VERSION "dbc-export 1 2025.20.8"

NS_ :

BS_:

BU_: ADSP APB APP APS APSB BB BMS CC CMP CMPD CP DAS DI DIF DIR DPB EPAS3P EPAS3S EPASTP EPASTS EPBL EPBR ESP EVSE FC GTW HCML HCMR HVP IBST ICR IDB LS OCS1P ODIN PARK PCS PLG PM PMF PMR PNCD PTC RADC RCM RCM2 RCM3 RCU SCCM SCM SCS SDCR TAS TCU TPMS TRCM UDS UI UIS UMC USM VC VCFRONT VCLEFT VCRIGHT VCSEC VEH

BO_ 1343 BMS_alertLog: 8 BMS
 SG_ BMS_alertID M : 0|8@1+ (1,0) [0|255] "" Vector__XXX
 SG_ BMS_alertSet : 15|1@1+ (1,0) [0|1] "" Vector__XXX
 SG_ BMS_a001_gatewayPackEnergy m1 : 16|2@1+ (1,0) [0|3] "" Vector__XXX
 SG_ BMS_a001_expectedPackEnergy m1 : 18|2@1+ (1,0) [0|3] "" Vector__XXX
 SG_ BMS_a002_gatewayPackPerformanceD m2 : 16|3@1+ (1,0) [0|7] "" Vector__XXX
 SG_ BMS_a002_expectedPackPerformance m2 : 19|3@1+ (1,0) [0|7] "" Vector__XXX
 SG_ BMS_a002_bmsPackMass m2 : 24|8@1+ (1,300) [300|555] "kg" Vector__XXX
 SG_ BMS_a003_calBlockData_0 m3 : 16|32@1+ (1,0) [0|4294967295] "" Vector__XXX
 SG_ BMS_a007_minPackTemperature m7 : 16|8@1+ (0.5,-40) [-40|87.5] "DegC" Vector__XXX
 SG_ BMS_a007_packCurrent m7 : 24|14@1+ (0.1,0) [0|1638.3] "A" Vector__XXX
 SG_ BMS_a007_idealCurrentTarget m7 : 40|14@1+ (0.1,0) [0|1638.3] "A" Vector__XXX
 SG_ BMS_a017_packCurrent m17 : 16|8@1+ (8,-1500) [-1500|540] "A" Vector__XXX
 SG_ BMS_a017_ovBrickVID m17 : 24|7@1+ (1,1) [1|128] "" Vector__XXX
 SG_ BMS_a017_ovBrickV m17 : 32|16@1+ (7.62939453125e-05,0) [0|4.99992370605] "V" Vector__XXX
 SG_ BMS_a018_packCurrent m18 : 16|8@1+ (8,-1496) [-1496|544] "A" Vector__XXX
 SG_ BMS_a018_uvBrickVID m18 : 24|7@1+ (1,1) [1|128] "" Vector__XXX
 SG_ BMS_a018_uvBrickV m18 : 32|16@1+ (7.62939453125e-05,0) [0|4.99992370605] "V" Vector__XXX
 SG_ BMS_a019_coolantInletT m19 : 16|8@1+ (0.4,-20) [-20|82] "C" Vector__XXX
 SG_ BMS_a019_activeCoolingTarget m19 : 24|8@1+ (0.4,-20) [-20|82] "C" Vector__XXX
 SG_ BMS_a019_maxBrickT m19 : 32|8@1+ (0.4,-20) [-20|82] "C" Vector__XXX
 SG_ BMS_a019_maxBrickTID m19 : 40|5@1+ (1,1) [1|32] "" Vector__XXX
 SG_ BMS_a021_chargeViolation m21 : 16|1@1+ (1,0) [0|1] "" Vector__XXX
 SG_ BMS_a021_currentLimit m21 : 24|8@1+ (8,-1496) [-1496|544] "A" Vector__XXX
 SG_ BMS_a021_packCurrent m21 : 32|8@1+ (8,-1496) [-1496|544] "A" Vector__XXX
 SG_ BMS_a022_chargeAccumulatorViolat m22 : 16|1@1+ (1,0) [0|1] "" Vector__XXX
 SG_ BMS_a022_chargeAccumulatorValue m22 : 17|23@1+ (10,0) [0|83886070] "A^2s" Vector__XXX
 SG_ BMS_a022_chargeAccumulatorLimit m22 : 40|23@1+ (10,0) [0|83886070] "A^2s" Vector__XXX
 SG_ BMS_a023_ovStackDeviceID m23 : 16|5@1+ (1,1) [1|32] "-" Vector__XXX
 SG_ BMS_a023_ovStackV m23 : 24|16@1+ (0.00128,0) [0|83.8848] "V" Vector__XXX
 SG_ BMS_a024_brickID m24 : 16|8@1+ (1,1) [1|256] "-" Vector__XXX
 SG_ BMS_a024_deltaV m24 : 24|16@1- (0.0001,0) [-3.2768|3.2767] "V" Vector__XXX
 SG_ BMS_a024_avgDvPrev m24 : 40|16@1- (0.0001,0) [-3.2768|3.2767] "V" Vector__XXX
 SG_ BMS_a024_packCurrent m24 : 56|8@1+ (8,-1500) [-1500|540] "A" Vector__XXX
 SG_ BMS_a027_swIsolationCount m27 : 16|8@1+ (1,0) [0|255] "" Vector__XXX
 SG_ BMS_a027_swIsoDegradationCount m27 : 24|8@1+ (1,0) [0|255] "" Vector__XXX
 SG_ BMS_a030_worstBrickID m30 : 16|8@1+ (1,1) [1|256] "" Vector__XXX
 SG_ BMS_a030_maxBrickImpedance m30 : 24|10@1+ (0.1,0) [0|102.3] "mOhm" Vector__XXX
 SG_ BMS_a030_maxNormalizedImpedanceD m30 : 34|7@1+ (0.04,0) [0|5.08] "Ratio" Vector__XXX
 SG_ BMS_a030_faultThreshold m30 : 41|7@1+ (0.04,0) [0|5.08] "Ratio" Vector__XXX
 SG_ BMS_a030_numBricks m30 : 48|8@1+ (1,0) [0|255] "" Vector__XXX
 SG_ BMS_a030_worstBrickSoc m30 : 56|8@1+ (0.5,0) [0|127.5] "PCT" Vector__XXX
 SG_ BMS_a035_isoR m35 : 16|9@1+ (10,0) [0|5110] "kOhm" Vector__XXX
 SG_ BMS_a035_mode m35 : 25|3@1+ (1,0) [0|7] "" Vector__XXX
 SG_ BMS_a035_activeSideVNoR m35 : 28|9@1+ (1,0) [0|511] "V" Vector__XXX
 SG_ BMS_a035_activeSideVWithR m35 : 37|9@1+ (1,0) [0|511] "V" Vector__XXX
 SG_ BMS_a035_passiveSideVNoR m35 : 46|9@1+ (1,0) [0|511] "V" Vector__XXX
 SG_ BMS_a035_passiveSideVWithR m35 : 55|9@1+ (1,0) [0|511] "V" Vector__XXX
 SG_ BMS_a037_floodPort1State m37 : 16|3@1+ (1,0) [1|7] "" Vector__XXX
 SG_ BMS_a037_floodPort1Voltage m37 : 19|12@1+ (0.001,0) [0|4.095] "V" Vector__XXX
 SG_ BMS_a037_floodPort2State m37 : 32|3@1+ (1,0) [1|7] "" Vector__XXX
 SG_ BMS_a037_floodPort2Voltage m37 : 35|12@1+ (0.001,0) [0|4.095] "V" Vector__XXX
 SG_ BMS_a039_dcLinkVoltage m39 : 16|10@1+ (1,0) [0|1023] "V" Vector__XXX
 SG_ BMS_a039_packVoltage m39 : 26|10@1+ (1,0) [0|1023] "V" Vector__XXX
 SG_ BMS_a039_packContactorState m39 : 36|4@1+ (1,0) [1|15] "" Vector__XXX
 SG_ BMS_a039_packCurrent m39 : 40|8@1+ (8,-1496) [-1496|544] "A" Vector__XXX
 SG_ BMS_a039_maxBrickV m39 : 48|8@1+ (0.01,2) [2|4.55] "V" Vector__XXX
 SG_ BMS_a039_state m39 : 56|4@1+ (1,0) [0|15] "" Vector__XXX
 SG_ BMS_a041_resetType m41 : 16|4@1+ (1,0) [0|15] "" Vector__XXX
 SG_ BMS_a050_MIA_numBadReadings m50 : 16|8@1+ (1,0) [0|255] "" Vector__XXX
 SG_ BMS_a050_MIA_numSnaReadings m50 : 24|8@1+ (1,0) [0|255] "" Vector__XXX
 SG_ BMS_a051_hvp1V5Ref m51 : 16|12@1+ (0.001,0) [0|4.095] "V" Vector__XXX
 SG_ BMS_a051_hvp3V0Ref m51 : 28|12@1+ (0.001,0) [0|4.095] "V" Vector__XXX
 SG_ BMS_a051_bms3V0Ref m51 : 40|12@1+ (0.001,0) [0|4.095] "V" Vector__XXX
 SG_ BMS_a056_standbySupplyOutV m56 : 16|12@1+ (0.01,0) [0|40.95] "V" Vector__XXX
 SG_ BMS_a056_packVoltage m56 : 28|16@1+ (0.01,0) [0|655.35] "V" Vector__XXX
 SG_ BMS_a056_minBrickVoltage m56 : 44|12@1+ (0.002,0) [0|8.19] "V" Vector__XXX
 SG_ BMS_a056_standbyEnabled m56 : 56|1@1+ (1,0) [0|1] "" Vector__XXX
 SG_ BMS_a056_standbySwGood m56 : 57|1@1+ (1,0) [0|1] "" Vector__XXX
 SG_ BMS_a056_ssOutTooHigh m56 : 58|1@1+ (1,0) [0|1] "" Vector__XXX
 SG_ BMS_a056_ssOutTooLow m56 : 59|1@1+ (1,0) [0|1] "" Vector__XXX
 SG_ BMS_a056_ssStuckOn m56 : 60|1@1+ (1,0) [0|1] "" Vector__XXX
 SG_ BMS_a056_ssStuckOff m56 : 61|1@1+ (1,0) [0|1] "" Vector__XXX
 SG_ BMS_a058_bandoThmModelState m58 : 16|4@1+ (1,0) [1|15] "" Vector__XXX
 SG_ BMS_a058_thermistorTempsInvalid m58 : 20|1@1+ (1,0) [0|1] "" Vector__XXX
 SG_ BMS_a058_inletCoolantTempInvalid m58 : 21|1@1+ (1,0) [0|1] "" Vector__XXX
 SG_ BMS_a058_ambientTempInvalid m58 : 22|1@1+ (1,0) [0|1] "" Vector__XXX
 SG_ BMS_a058_flowRateInvalid m58 : 23|1@1+ (1,0) [0|1] "" Vector__XXX
 SG_ BMS_a058_brickDissipationInvalid m58 : 24|1@1+ (1,0) [0|1] "" Vector__XXX
 SG_ BMS_a058_sanityCheckFailed m58 : 25|1@1+ (1,0) [0|1] "" Vector__XXX
 SG_ BMS_a058_tempDelta1 m58 : 32|7@1- (0.2,0) [-12.8|12.6] "C" Vector__XXX
 SG_ BMS_a058_tempDelta2 m58 : 40|7@1- (0.2,0) [-12.8|12.6] "C" Vector__XXX
 SG_ BMS_a058_tempDelta3 m58 : 48|7@1- (0.2,0) [-12.8|12.6] "C" Vector__XXX
 SG_ BMS_a058_tempDelta4 m58 : 56|7@1- (0.2,0) [-12.8|12.6] "C" Vector__XXX
 SG_ BMS_a059_sumBrickVoltages m59 : 16|16@1+ (0.01,0) [0|655.35] "V" Vector__XXX
 SG_ BMS_a059_packVoltage m59 : 32|16@1+ (0.01,0) [0|655.35] "V" Vector__XXX
 SG_ BMS_a062_state m62 : 16|4@1+ (1,0) [0|15] "" Vector__XXX
 SG_ BMS_a062_minBrickVId m62 : 24|7@1+ (1,1) [1|128] "" Vector__XXX
 SG_ BMS_a062_minBrickVoltage m62 : 32|12@1+ (0.002,0) [0|8.19] "V" Vector__XXX
 SG_ BMS_a062_maxBrickVId m62 : 44|7@1+ (1,1) [1|128] "" Vector__XXX
 SG_ BMS_a062_maxBrickVoltage m62 : 51|12@1+ (0.002,0) [0|8.19] "V" Vector__XXX
 SG_ BMS_a063_cpFaultInV m63 : 16|12@1+ (0.001,0) [0|4.095] "V" Vector__XXX
 SG_ BMS_a064_minBrickSOCID m64 : 16|7@1+ (1,1) [1|128] "" Vector__XXX
 SG_ BMS_a064_minBrickSOC m64 : 24|8@1+ (0.5,0) [0|127.5] "PCT" Vector__XXX
 SG_ BMS_a064_maxBrickSOCID m64 : 32|7@1+ (1,1) [1|128] "" Vector__XXX
 SG_ BMS_a064_maxBrickSOC m64 : 40|8@1+ (0.5,0) [0|127.5] "PCT" Vector__XXX
 SG_ BMS_a064_avgBrickSOC m64 : 48|8@1+ (0.5,0) [0|127.5] "PCT" Vector__XXX
 SG_ BMS_a065_minBrickCacId m65 : 16|7@1+ (1,1) [1|128] "" Vector__XXX
 SG_ BMS_a065_minBrickCac m65 : 24|13@1+ (0.1,0) [0|819.1] "Ah" Vector__XXX
 SG_ BMS_a065_avgBrickCac m65 : 40|13@1+ (0.1,0) [0|819.1] "Ah" Vector__XXX
 SG_ BMS_a065_modCacImbalancePct m65 : 53|10@1+ (0.1,0) [0|102.3] "%" Vector__XXX
 SG_ BMS_a066_minBrickSocId m66 : 16|7@1+ (1,1) [1|128] "" Vector__XXX
 SG_ BMS_a066_minBrickSocByOcvMax m66 : 24|8@1+ (0.5,0) [0|127.5] "PCT" Vector__XXX
 SG_ BMS_a066_maxBrickSocId m66 : 32|7@1+ (1,1) [1|128] "" Vector__XXX
 SG_ BMS_a066_maxBrickSocByOcvMin m66 : 40|8@1+ (0.5,0) [0|127.5] "PCT" Vector__XXX
 SG_ BMS_a066_maxBrickSoc m66 : 48|8@1+ (0.5,0) [0|127.5] "PCT" Vector__XXX
 SG_ BMS_a066_avgBrickSoc m66 : 56|8@1+ (0.5,0) [0|127.5] "PCT" Vector__XXX
 SG_ BMS_a067_minBrickCacId m67 : 16|7@1+ (1,1) [1|128] "" Vector__XXX
 SG_ BMS_a067_minBrickCac m67 : 24|13@1+ (0.1,0) [0|819.1] "Ah" Vector__XXX
 SG_ BMS_a067_avgBrickCac m67 : 40|13@1+ (0.1,0) [0|819.1] "Ah" Vector__XXX
 SG_ BMS_a067_modCacImbalancePct m67 : 53|10@1+ (0.1,0) [0|102.3] "%" Vector__XXX
 SG_ BMS_a068_minBrickCacId m68 : 16|7@1+ (1,1) [1|128] "" Vector__XXX
 SG_ BMS_a068_minBrickCac m68 : 24|13@1+ (0.1,0) [0|819.1] "Ah" Vector__XXX
 SG_ BMS_a068_avgBrickCac m68 : 40|13@1+ (0.1,0) [0|819.1] "Ah" Vector__XXX
 SG_ BMS_a068_modCacImbalancePct m68 : 53|10@1+ (0.1,0) [0|102.3] "%" Vector__XXX
 SG_ BMS_a069_dischargePowerPackVolta m69 : 16|8@1- (0.025,-3.15) [-6.35|0.025] "kW" Vector__XXX
 SG_ BMS_a069_dischargePowerBrickVolt m69 : 24|8@1- (0.005,-0.63) [-1.27|0.005] "kW" Vector__XXX
 SG_ BMS_a069_SOC m69 : 32|8@1+ (0.05,0) [0|12.75] "PCT" Vector__XXX
 SG_ BMS_a069_minBrickT m69 : 40|8@1- (0.5,24) [-40|87.5] "DegC" Vector__XXX
 SG_ BMS_a069_minBrickVLimit m69 : 48|8@1+ (0.01,2) [2|4.55] "V" Vector__XXX
 SG_ BMS_a069_minBrickV m69 : 56|8@1+ (0.01,2) [2|4.55] "V" Vector__XXX
 SG_ BMS_a070_state m70 : 16|4@1+ (1,0) [0|15] "" Vector__XXX
 SG_ BMS_a070_minBrickVId m70 : 24|7@1+ (1,1) [1|128] "" Vector__XXX
 SG_ BMS_a070_minBrickVoltage m70 : 32|12@1+ (0.002,0) [0|8.19] "V" Vector__XXX
 SG_ BMS_a070_maxBrickVId m70 : 44|7@1+ (1,1) [1|128] "" Vector__XXX
 SG_ BMS_a070_maxBrickVoltage m70 : 51|12@1+ (0.002,0) [0|8.19] "V" Vector__XXX
 SG_ BMS_a071_stateRequest m71 : 16|4@1+ (1,0) [0|15] "" Vector__XXX
 SG_ BMS_a071_state m71 : 20|4@1+ (1,0) [0|15] "" Vector__XXX
 SG_ BMS_a071_transitionAlertId m71 : 24|10@1+ (1,0) [0|1023] "" Vector__XXX
 SG_ BMS_a074_maxBrickVTarget m74 : 16|8@1+ (0.01,2) [2|4.55] "V" Vector__XXX
 SG_ BMS_a074_maxBrickV m74 : 24|8@1+ (0.01,2) [2|4.55] "V" Vector__XXX
 SG_ BMS_a075_chargeType m75 : 16|1@1+ (1,0) [0|1] "" Vector__XXX
 SG_ BMS_a076_netAh m76 : 16|21@1- (0.01,0) [-10485.76|10485.75] "Ah" Vector__XXX
 SG_ BMS_a076_tetheringActive m76 : 37|1@1+ (1,0) [0|1] "" Vector__XXX
 SG_ BMS_a078_peakDchInChg m78 : 16|16@1- (0.1,0) [-3276.8|3276.7] "A" Vector__XXX
 SG_ BMS_a079_maxBrickVTarget m79 : 16|8@1+ (0.01,2) [2|4.55] "V" Vector__XXX
 SG_ BMS_a079_maxBrickV m79 : 24|8@1+ (0.01,2) [2|4.55] "V" Vector__XXX
 SG_ BMS_a081_stateRequest m81 : 16|4@1+ (1,0) [0|15] "" Vector__XXX
 SG_ BMS_a081_firstBlockingAlertId m81 : 24|8@1+ (1,0) [0|255] "" Vector__XXX
 SG_ BMS_a081_secondBlockingAlertId m81 : 32|8@1+ (1,0) [0|255] "" Vector__XXX
 SG_ BMS_a081_thirdBlockingAlertId m81 : 40|8@1+ (1,0) [0|255] "" Vector__XXX
 SG_ BMS_a081_fourthBlockingAlertId m81 : 48|8@1+ (1,0) [0|255] "" Vector__XXX
 SG_ BMS_a081_totalAlertCount m81 : 56|8@1+ (1,0) [0|255] "" Vector__XXX
 SG_ BMS_a082_stateRequest m82 : 16|4@1+ (1,0) [0|15] "" Vector__XXX
 SG_ BMS_a082_firstAlertId m82 : 24|8@1+ (1,0) [0|255] "" Vector__XXX
 SG_ BMS_a082_secondAlertId m82 : 32|8@1+ (1,0) [0|255] "" Vector__XXX
 SG_ BMS_a082_thirdAlertId m82 : 40|8@1+ (1,0) [0|255] "" Vector__XXX
 SG_ BMS_a082_fourthAlertId m82 : 48|8@1+ (1,0) [0|255] "" Vector__XXX
 SG_ BMS_a082_totalAlertCount m82 : 56|8@1+ (1,0) [0|255] "" Vector__XXX
 SG_ BMS_a083_packContactorRequest m83 : 16|3@1+ (1,0) [1|7] "" Vector__XXX
 SG_ BMS_a085_packContactorSetStatePr m85 : 16|4@1+ (1,0) [1|15] "" Vector__XXX
 SG_ BMS_a085_packContactorSetState m85 : 20|4@1+ (1,0) [1|15] "" Vector__XXX
 SG_ BMS_a085_packContactorSetRe_0001 m85 : 24|3@1+ (1,0) [1|7] "" Vector__XXX
 SG_ BMS_a085_packContactorSetRequest m85 : 27|3@1+ (1,0) [1|7] "" Vector__XXX
 SG_ BMS_a086_fcContactorSetStatePrev m86 : 16|4@1+ (1,0) [1|15] "" Vector__XXX
 SG_ BMS_a086_fcContactorSetState m86 : 20|4@1+ (1,0) [1|15] "" Vector__XXX
 SG_ BMS_a086_fcContactorSetRequestPr m86 : 24|3@1+ (1,0) [1|7] "" Vector__XXX
 SG_ BMS_a086_fcContactorSetRequest m86 : 27|3@1+ (1,0) [1|7] "" Vector__XXX
 SG_ BMS_a087_blockingAlert m87 : 16|8@1+ (1,0) [0|255] "" Vector__XXX
 SG_ BMS_a090_GTWmessageTout m90 : 16|4@1+ (1,0) [0|15] "" Vector__XXX
 SG_ BMS_a097_missingFrame m97 : 16|1@1+ (1,0) [0|1] "" Vector__XXX
 SG_ BMS_a097_timeout m97 : 17|1@1+ (1,0) [0|1] "" Vector__XXX
 SG_ BMS_a098_breakLocationA m98 : 16|5@1+ (1,0) [0|31] "" Vector__XXX
 SG_ BMS_a098_bmbCommStatusTypeA m98 : 21|2@1+ (1,0) [0|3] "" Vector__XXX
 SG_ BMS_a098_breakLocationB m98 : 24|5@1+ (1,0) [0|31] "" Vector__XXX
 SG_ BMS_a098_bmbCommStatusTypeB m98 : 29|2@1+ (1,0) [0|3] "" Vector__XXX
 SG_ BMS_a098_alertFromHvp m98 : 31|1@1+ (1,0) [0|1] "" Vector__XXX
 SG_ BMS_a099_breakLocationA m99 : 16|5@1+ (1,0) [0|31] "" Vector__XXX
 SG_ BMS_a099_bmbCommStatusTypeA m99 : 21|2@1+ (1,0) [0|3] "" Vector__XXX
 SG_ BMS_a099_breakLocationB m99 : 24|5@1+ (1,0) [0|31] "" Vector__XXX
 SG_ BMS_a099_bmbCommStatusTypeB m99 : 29|2@1+ (1,0) [0|3] "" Vector__XXX
 SG_ BMS_a099_bmbChainBreakType m99 : 32|3@1+ (1,0) [0|7] "" Vector__XXX
 SG_ BMS_a099_alertFromHvp m99 : 35|1@1+ (1,0) [0|1] "" Vector__XXX
 SG_ BMS_a100_testTrigger m100 : 16|1@1+ (1,0) [0|1] "" Vector__XXX
 SG_ BMS_a100_setFromNvm m100 : 17|1@1+ (1,0) [0|1] "" Vector__XXX
 SG_ BMS_a100_voltageDeviation m100 : 18|1@1+ (1,0) [0|1] "" Vector__XXX
 SG_ BMS_a100_voltageLoss m100 : 19|1@1+ (1,0) [0|1] "" Vector__XXX
 SG_ BMS_a105_tSenseFailedModule1 m105 : 16|1@1+ (1,0) [0|1] "" Vector__XXX
 SG_ BMS_a105_avgBrickTModule1 m105 : 17|8@1+ (0.5,0) [0|127.5] "C" Vector__XXX
 SG_ BMS_a105_tSenseFailedModule2 m105 : 25|1@1+ (1,0) [0|1] "" Vector__XXX
 SG_ BMS_a105_avgBrickTModule2 m105 : 26|8@1+ (0.5,0) [0|127.5] "C" Vector__XXX
 SG_ BMS_a105_tSenseFailedModule3 m105 : 34|1@1+ (1,0) [0|1] "" Vector__XXX
 SG_ BMS_a105_avgBrickTModule3 m105 : 35|8@1+ (0.5,0) [0|127.5] "C" Vector__XXX
 SG_ BMS_a105_tSenseFailedModule4 m105 : 43|1@1+ (1,0) [0|1] "" Vector__XXX
 SG_ BMS_a105_avgBrickTModule4 m105 : 44|8@1+ (0.5,0) [0|127.5] "C" Vector__XXX
 SG_ BMS_a105_inletTemp m105 : 52|8@1+ (0.5,0) [0|127.5] "C" Vector__XXX
 SG_ BMS_a106_minBrickT m106 : 16|8@1+ (0.5,0) [0|127.5] "C" Vector__XXX
 SG_ BMS_a106_maxBrickT m106 : 24|8@1+ (0.5,0) [0|127.5] "C" Vector__XXX
 SG_ BMS_a106_avgBrickT m106 : 32|8@1+ (0.5,0) [0|127.5] "C" Vector__XXX
 SG_ BMS_a106_inletTemp m106 : 40|8@1+ (0.5,0) [0|127.5] "C" Vector__XXX
 SG_ BMS_a107_MIA_numBadReadings m107 : 16|8@1+ (1,0) [0|255] "" Vector__XXX
 SG_ BMS_a107_MIA_numSnaReadings m107 : 24|8@1+ (1,0) [0|255] "" Vector__XXX
 SG_ BMS_a109_muteMask m109 : 16|16@1+ (1,0) [0|65535] "" Vector__XXX
 SG_ BMS_a109_packInBleed m109 : 32|1@1+ (1,0) [0|1] "" Vector__XXX
 SG_ BMS_a117_brickID m117 : 16|7@1+ (1,1) [1|128] "" Vector__XXX
 SG_ BMS_a117_brickSoc2 m117 : 23|10@1+ (0.1,0) [0|102.2] "%" Vector__XXX
 SG_ BMS_a117_dSocAlertThreshold m117 : 33|5@1+ (0.125,-4) [-4|-0.125] "%" Vector__XXX
 SG_ BMS_a117_dSocAlpha m117 : 48|12@1+ (0.0030517578125,-12.4969482422) [-12.4969482422|-0.003051757825] "%" Vector__XXX
 SG_ BMS_a122_thermistorID m122 : 16|5@1+ (1,1) [1|32] "" Vector__XXX
 SG_ BMS_a122_irrationalThermistorTem m122 : 24|8@1+ (0.5,-40) [-40|87.5] "DegC" Vector__XXX
 SG_ BMS_a122_averageRawThermistorTem m122 : 32|8@1+ (0.5,-40) [-40|87.5] "DegC" Vector__XXX
 SG_ BMS_a122_minRawThermistorTemp m122 : 40|8@1+ (0.5,-40) [-40|87.5] "DegC" Vector__XXX
 SG_ BMS_a122_maxRawThermistorTemp m122 : 48|8@1+ (0.5,-40) [-40|87.5] "DegC" Vector__XXX
 SG_ BMS_a122_numValidThermistors m122 : 56|5@1+ (1,0) [0|31] "" Vector__XXX
 SG_ BMS_a123_packPlus m123 : 32|8@1+ (4,0) [0|1020] "V" Vector__XXX
 SG_ BMS_a123_isoR m123 : 40|10@1+ (10,0) [0|10230] "kOhm" Vector__XXX
 SG_ BMS_a123_packMinus m123 : 56|8@1- (4,0) [-512|508] "V" Vector__XXX
 SG_ BMS_a129_brickID m129 : 16|8@1+ (1,1) [1|256] "-" Vector__XXX
 SG_ BMS_a129_deltaV m129 : 24|16@1+ (0.0001,0) [0|6.5535] "V" Vector__XXX
 SG_ BMS_a129_retryCount m129 : 40|4@1+ (1,0) [0|15] "-" Vector__XXX
 SG_ BMS_a131_brickID m131 : 16|8@1+ (1,1) [1|256] "-" Vector__XXX
 SG_ BMS_a131_deltaV m131 : 24|16@1+ (0.0001,0) [0|6.5535] "V" Vector__XXX
 SG_ BMS_a131_retryCount m131 : 40|4@1+ (1,0) [0|15] "-" Vector__XXX
 SG_ BMS_a132_multiVendorErrorMask m132 : 16|16@1+ (1,0) [0|65535] "" Vector__XXX
 SG_ BMS_a135_bmbDiagnosticsType m135 : 16|2@1+ (1,0) [0|3] "" Vector__XXX
 SG_ BMS_a135_bmbDeviceId m135 : 18|4@1+ (1,1) [1|16] "" Vector__XXX
 SG_ BMS_a135_readCVA m135 : 22|1@1+ (1,0) [0|1] "" Vector__XXX
 SG_ BMS_a135_readCVB m135 : 23|1@1+ (1,0) [0|1] "" Vector__XXX
 SG_ BMS_a135_readCVC m135 : 24|1@1+ (1,0) [0|1] "" Vector__XXX
 SG_ BMS_a135_readCVD m135 : 25|1@1+ (1,0) [0|1] "" Vector__XXX
 SG_ BMS_a135_readCVE m135 : 26|1@1+ (1,0) [0|1] "" Vector__XXX
 SG_ BMS_a135_readCVF m135 : 27|1@1+ (1,0) [0|1] "" Vector__XXX
 SG_ BMS_a135_readSNA m135 : 28|1@1+ (1,0) [0|1] "" Vector__XXX
 SG_ BMS_a135_readSNB m135 : 29|1@1+ (1,0) [0|1] "" Vector__XXX
 SG_ BMS_a135_readSNC m135 : 30|1@1+ (1,0) [0|1] "" Vector__XXX
 SG_ BMS_a135_readSND m135 : 31|1@1+ (1,0) [0|1] "" Vector__XXX
 SG_ BMS_a135_readSNE m135 : 32|1@1+ (1,0) [0|1] "" Vector__XXX
 SG_ BMS_a135_readSNF m135 : 33|1@1+ (1,0) [0|1] "" Vector__XXX
 SG_ BMS_a135_readAUXA m135 : 34|1@1+ (1,0) [0|1] "" Vector__XXX
 SG_ BMS_a135_readAUXB m135 : 35|1@1+ (1,0) [0|1] "" Vector__XXX
 SG_ BMS_a135_readSTAT m135 : 36|1@1+ (1,0) [0|1] "" Vector__XXX
 SG_ BMS_a136_maxBrickTID m136 : 16|5@1+ (1,1) [1|32] "" Vector__XXX
 SG_ BMS_a136_coolantInletT m136 : 24|8@1+ (0.4,-20) [-20|82] "C" Vector__XXX
 SG_ BMS_a136_activeCoolingTarget m136 : 32|8@1+ (0.4,-20) [-20|82] "C" Vector__XXX
 SG_ BMS_a136_maxBrickT m136 : 40|8@1+ (0.4,-20) [-20|82] "C" Vector__XXX
 SG_ BMS_a139_packVoltage m139 : 16|16@1- (0.01,0) [-327.68|327.67] "V" Vector__XXX
 SG_ BMS_a139_dcLinkVoltage m139 : 32|16@1+ (0.01,0) [0|655.35] "V" Vector__XXX
 SG_ BMS_a140_bmbDeviceMask m140 : 16|16@1+ (1,0) [0|65535] "" Vector__XXX
 SG_ BMS_a140_faultType m140 : 32|8@1+ (1,0) [0|255] "" Vector__XXX
 SG_ BMS_a142_isolationResistance m142 : 16|10@1+ (10,0) [0|10230] "kOhm" Vector__XXX
 SG_ BMS_a142_mode m142 : 32|3@1+ (1,0) [0|7] "" Vector__XXX
 SG_ BMS_a143_initialSoc m143 : 16|9@1+ (0.2,0) [0|102.2] "%" Vector__XXX
 SG_ BMS_a143_endingSoc m143 : 25|9@1+ (0.2,0) [0|102.2] "%" Vector__XXX
 SG_ BMS_a143_deltaAh m143 : 34|9@1+ (0.5,0) [0|255.5] "Ah" Vector__XXX
 SG_ BMS_a143_cacChangeBrickID m143 : 48|7@1+ (1,1) [1|128] "" Vector__XXX
 SG_ BMS_a143_cacUpdateError m143 : 56|8@1+ (0.1,0) [0|25.5] "Ah" Vector__XXX
 SG_ BMS_a144_HVP_major_version m144 : 16|16@1+ (1,0) [0|65535] "" Vector__XXX
 SG_ BMS_a144_HVP_minor_version m144 : 32|16@1+ (1,0) [0|65535] "" Vector__XXX
 SG_ BMS_a144_BMS_minor_version m144 : 48|16@1+ (1,0) [0|65535] "" Vector__XXX
 SG_ BMS_a145_maxSocChange m145 : 16|11@1- (0.1,0) [-102.4|102.3] "%" Vector__XXX
 SG_ BMS_a145_maxSocChangeBrickID m145 : 32|7@1+ (1,1) [1|128] "" Vector__XXX
 SG_ BMS_a145_numBricksChanged m145 : 40|7@1+ (1,0) [0|127] "" Vector__XXX
 SG_ BMS_a145_brickChangeHystRatio m145 : 48|10@1+ (0.001,0) [0|1.022] "Ratio" Vector__XXX
 SG_ BMS_a146_maxBrickV m146 : 16|8@1+ (0.01,2) [2|4.55] "V" Vector__XXX
 SG_ BMS_a146_state m146 : 24|4@1+ (1,0) [0|15] "" Vector__XXX
 SG_ BMS_a146_packCurrent m146 : 32|8@1+ (8,-1496) [-1496|544] "A" Vector__XXX
 SG_ BMS_a146_uvBrickVID m146 : 40|7@1+ (1,1) [1|128] "" Vector__XXX
 SG_ BMS_a146_uvBrickV m146 : 48|16@1+ (7.62939453125e-05,0) [0|4.99992370605] "V" Vector__XXX
 SG_ BMS_a151_isoPositiveR m151 : 32|10@1+ (10,0) [0|10230] "kOhm" Vector__XXX
 SG_ BMS_a151_isoNegativeR m151 : 42|10@1+ (10,0) [0|10230] "kOhm" Vector__XXX
 SG_ BMS_a152_isoR m152 : 16|9@1+ (10,0) [0|5110] "kOhm" Vector__XXX
 SG_ BMS_a152_mode m152 : 25|3@1+ (1,0) [0|7] "" Vector__XXX
 SG_ BMS_a152_activeSideVNoR m152 : 28|9@1+ (1,0) [0|511] "V" Vector__XXX
 SG_ BMS_a152_activeSideVWithR m152 : 37|9@1+ (1,0) [0|511] "V" Vector__XXX
 SG_ BMS_a152_passiveSideVNoR m152 : 46|9@1+ (1,0) [0|511] "V" Vector__XXX
 SG_ BMS_a152_passiveSideVWithR m152 : 55|9@1+ (1,0) [0|511] "V" Vector__XXX
 SG_ BMS_a156_VrefSample m156 : 16|16@1+ (0.0001,0) [0|6.5535] "V" Vector__XXX
 SG_ BMS_a156_bmbDeviceId m156 : 32|4@1+ (1,1) [1|16] "" Vector__XXX
 SG_ BMS_a156_VrefStatus m156 : 36|2@1+ (1,0) [0|3] "" Vector__XXX
 SG_ BMS_a158_shuntCurrentMia m158 : 16|1@1+ (1,0) [0|1] "" Vector__XXX
 SG_ BMS_a158_contactorStateMia m158 : 17|1@1+ (1,0) [0|1] "" Vector__XXX
 SG_ BMS_a158_hvpFaultsMia m158 : 18|1@1+ (1,0) [0|1] "" Vector__XXX
 SG_ BMS_a162_dischargePower_W m162 : 16|16@1- (1,0) [-32768|32767] "W" Vector__XXX
 SG_ BMS_a162_minSoc m162 : 32|16@1+ (1,0) [0|65535] "%" Vector__XXX
 SG_ BMS_a162_socThreshold m162 : 48|16@1+ (1,0) [0|65535] "%" Vector__XXX
 SG_ BMS_a164_regenPower m164 : 16|32@1+ (1,0) [0|4294967295] "W" Vector__XXX
 SG_ BMS_a165_packPositiveV m165 : 16|12@1- (0.25,0) [-512|511.75] "V" Vector__XXX
 SG_ BMS_a165_packNegativeV m165 : 28|12@1- (0.25,0) [-512|511.75] "V" Vector__XXX
 SG_ BMS_a165_dcLinkPositiveV m165 : 40|12@1- (0.25,0) [-512|511.75] "V" Vector__XXX
 SG_ BMS_a165_dcLinkNegativeV m165 : 52|12@1- (0.25,0) [-512|511.75] "V" Vector__XXX
 SG_ BMS_a166_packPositiveV m166 : 16|12@1- (0.25,0) [-512|511.75] "V" Vector__XXX
 SG_ BMS_a166_packNegativeV m166 : 28|12@1- (0.25,0) [-512|511.75] "V" Vector__XXX
 SG_ BMS_a166_dcLinkPositiveV m166 : 40|12@1- (0.25,0) [-512|511.75] "V" Vector__XXX
 SG_ BMS_a166_dcLinkNegativeV m166 : 52|12@1- (0.25,0) [-512|511.75] "V" Vector__XXX
 SG_ BMS_a167_fcContPositiveAuxOpen m167 : 16|1@1+ (1,0) [0|1] "" Vector__XXX
 SG_ BMS_a167_fcContNegativeAuxOpen m167 : 17|1@1+ (1,0) [0|1] "" Vector__XXX
 SG_ BMS_a167_dcLinkPositiveV m167 : 18|11@1- (0.5,0) [-512|511.5] "V" Vector__XXX
 SG_ BMS_a167_dcLinkNegativeV m167 : 29|11@1- (0.5,0) [-512|511.5] "V" Vector__XXX
 SG_ BMS_a167_fcLinkPositiveV m167 : 40|11@1- (0.5,0) [-512|511.5] "V" Vector__XXX
 SG_ BMS_a167_fcLinkNegativeV m167 : 51|11@1- (0.5,0) [-512|511.5] "V" Vector__XXX
 SG_ BMS_a168_fcContPositiveAuxOpen m168 : 16|1@1+ (1,0) [0|1] "" Vector__XXX
 SG_ BMS_a168_fcContNegativeAuxOpen m168 : 17|1@1+ (1,0) [0|1] "" Vector__XXX
 SG_ BMS_a168_dcLinkPositiveV m168 : 18|11@1- (0.5,0) [-512|511.5] "V" Vector__XXX
 SG_ BMS_a168_dcLinkNegativeV m168 : 29|11@1- (0.5,0) [-512|511.5] "V" Vector__XXX
 SG_ BMS_a168_fcLinkPositiveV m168 : 40|11@1- (0.5,0) [-512|511.5] "V" Vector__XXX
 SG_ BMS_a168_fcLinkNegativeV m168 : 51|11@1- (0.5,0) [-512|511.5] "V" Vector__XXX
 SG_ BMS_a169_DCAndFCContactorsWelded m169 : 16|1@1+ (1,0) [0|1] "" Vector__XXX
 SG_ BMS_a170_limpModeActive m170 : 16|1@1+ (1,0) [0|1] "" Vector__XXX
 SG_ BMS_a171_stackVoltage m171 : 16|16@1+ (0.00128,0) [0|83.8848] "V" Vector__XXX
 SG_ BMS_a171_sumBrickVoltage m171 : 32|16@1+ (0.00128,0) [0|83.8848] "V" Vector__XXX
 SG_ BMS_a171_stackId m171 : 48|8@1+ (1,1) [1|256] "" Vector__XXX
 SG_ BMS_a172_swIsolationCount m172 : 16|8@1+ (1,0) [0|255] "" Vector__XXX
 SG_ BMS_a172_swIsoDegradationCount m172 : 24|8@1+ (1,0) [0|255] "" Vector__XXX
 SG_ BMS_a177_energyAlertThreshold m177 : 16|10@1+ (0.1,0) [0|102.3] "KWh" Vector__XXX
 SG_ BMS_a177_energyBuffer m177 : 26|10@1+ (0.1,0) [0|102.3] "KWh" Vector__XXX
 SG_ BMS_a178_diPower m178 : 16|9@1- (4.3137254715,250.196075439) [-854.117645265|1350.19607067] "kW" Vector__XXX
 SG_ BMS_a178_energyError m178 : 25|8@1- (2,0) [-256|254] "kJ" Vector__XXX
 SG_ BMS_a178_powerError m178 : 33|9@1- (1,0) [-256|255] "kW" Vector__XXX
 SG_ BMS_a178_minPowerError m178 : 42|9@1- (1,0) [-256|255] "kW" Vector__XXX
 SG_ BMS_a178_maxPowerError m178 : 51|9@1- (1,0) [-256|255] "kW" Vector__XXX
 SG_ BMS_a178_diMiaCount m178 : 60|2@1+ (1,0) [0|3] "" Vector__XXX
 SG_ BMS_a178_diSnaCount m178 : 62|2@1+ (1,0) [0|3] "" Vector__XXX

BO_ 800 BMS_alertMatrix: 8 BMS
 SG_ BMS_matrixIndex M : 0|4@1+ (1,0) [0|15] "" Vector__XXX
 SG_ BMS_a001_Pack_Config_Mismatch m0 : 4|1@1+ (1,0) [0|1] "" Vector__XXX
 SG_ BMS_a002_Pack_Performance_Config m0 : 5|1@1+ (1,0) [0|1] "" Vector__XXX
 SG_ BMS_a003_SW_Pack_Birth_Date_Miss m0 : 6|1@1+ (1,0) [0|1] "" Vector__XXX
 SG_ BMS_a004_Cal_Vs_Serial_Birth_Dat m0 : 7|1@1+ (1,0) [0|1] "" Vector__XXX
 SG_ BMS_a007_SW_Slowed_Chg_Batt_Cold m0 : 10|1@1+ (1,0) [0|1] "" Vector__XXX
 SG_ BMS_a016_Pack_Module_Id_Mismatch m0 : 19|1@1+ (1,0) [0|1] "" Vector__XXX
 SG_ BMS_a017_SW_Brick_OV m0 : 20|1@1+ (1,0) [0|1] "" Vector__XXX
 SG_ BMS_a018_SW_Brick_UV m0 : 21|1@1+ (1,0) [0|1] "" Vector__XXX
 SG_ BMS_a019_SW_Module_OT m0 : 22|1@1+ (1,0) [0|1] "" Vector__XXX
 SG_ BMS_a020_SW_Brick_Instability m0 : 23|1@1+ (1,0) [0|1] "" Vector__XXX
 SG_ BMS_a021_SW_Dr_Limits_Regulation m0 : 24|1@1+ (1,0) [0|1] "" Vector__XXX
 SG_ BMS_a022_SW_Over_Current m0 : 25|1@1+ (1,0) [0|1] "" Vector__XXX
 SG_ BMS_a023_SW_Stack_OV m0 : 26|1@1+ (1,0) [0|1] "" Vector__XXX
 SG_ BMS_a024_SW_Islanded_Brick m0 : 27|1@1+ (1,0) [0|1] "" Vector__XXX
 SG_ BMS_a025_SW_PwrBalance_Anomaly m0 : 28|1@1+ (1,0) [0|1] "" Vector__XXX
 SG_ BMS_a026_SW_HFCurrent_Anomaly m0 : 29|1@1+ (1,0) [0|1] "" Vector__XXX
 SG_ BMS_a027_SW_Repeated_Isolation_F m0 : 30|1@1+ (1,0) [0|1] "" Vector__XXX
 SG_ BMS_a028_ShuntAsicCurrentOffsetD m0 : 31|1@1+ (1,0) [0|1] "" Vector__XXX
 SG_ BMS_a029_dSoc_Limiting m0 : 32|1@1+ (1,0) [0|1] "" Vector__XXX
 SG_ BMS_a030_Impedance_Deviation m0 : 33|1@1+ (1,0) [0|1] "" Vector__XXX
 SG_ BMS_a031_AlertsSetDuringSleep m0 : 34|1@1+ (1,0) [0|1] "" Vector__XXX
 SG_ BMS_a032_VoltageLoss m0 : 35|1@1+ (1,0) [0|1] "" Vector__XXX
 SG_ BMS_a033_VoltageDeviation m0 : 36|1@1+ (1,0) [0|1] "" Vector__XXX
 SG_ BMS_a034_SW_Passive_Isolation m0 : 37|1@1+ (1,0) [0|1] "" Vector__XXX
 SG_ BMS_a035_SW_Isolation m0 : 38|1@1+ (1,0) [0|1] "" Vector__XXX
 SG_ BMS_a036_SW_HvpHvilFault m0 : 39|1@1+ (1,0) [0|1] "" Vector__XXX
 SG_ BMS_a037_SW_Flood_Port_Open m0 : 40|1@1+ (1,0) [0|1] "" Vector__XXX
 SG_ BMS_a039_SW_DC_Link_Over_Voltage m0 : 42|1@1+ (1,0) [0|1] "" Vector__XXX
 SG_ BMS_a040_SW_Watch_Dog_HW_Trigger m0 : 43|1@1+ (1,0) [0|1] "" Vector__XXX
 SG_ BMS_a041_SW_Destructive_Reset_So m0 : 44|1@1+ (1,0) [0|1] "" Vector__XXX
 SG_ BMS_a042_SW_MPU_Error m0 : 45|1@1+ (1,0) [0|1] "" Vector__XXX
 SG_ BMS_a043_SW_Watch_Dog_Reset m0 : 46|1@1+ (1,0) [0|1] "" Vector__XXX
 SG_ BMS_a044_SW_Assertion m0 : 47|1@1+ (1,0) [0|1] "" Vector__XXX
 SG_ BMS_a045_SW_Exception m0 : 48|1@1+ (1,0) [0|1] "" Vector__XXX
 SG_ BMS_a046_SW_Task_Stack_Usage m0 : 49|1@1+ (1,0) [0|1] "" Vector__XXX
 SG_ BMS_a047_SW_Task_Stack_Overflow m0 : 50|1@1+ (1,0) [0|1] "" Vector__XXX
 SG_ BMS_a048_SW_Watch_Dog_Warning m0 : 51|1@1+ (1,0) [0|1] "" Vector__XXX
 SG_ BMS_a049_SW_Thermal_Event m0 : 52|1@1+ (1,0) [0|1] "" Vector__XXX
 SG_ BMS_a050_SW_Brick_Voltage_MIA m0 : 53|1@1+ (1,0) [0|1] "" Vector__XXX
 SG_ BMS_a051_SW_HVC_Vref_Bad m0 : 54|1@1+ (1,0) [0|1] "" Vector__XXX
 SG_ BMS_a052_SW_PCS_MIA m0 : 55|1@1+ (1,0) [0|1] "" Vector__XXX
 SG_ BMS_a054_SW_Ver_Supply_Fault m0 : 57|1@1+ (1,0) [0|1] "" Vector__XXX
 SG_ BMS_a055_SW_HvChain_Model_Fault m0 : 58|1@1+ (1,0) [0|1] "" Vector__XXX
 SG_ BMS_a056_SW_Standby_Supply_Fault m0 : 59|1@1+ (1,0) [0|1] "" Vector__XXX
 SG_ BMS_a057_SW_Bandolier_Model_Warn m0 : 60|1@1+ (1,0) [0|1] "" Vector__XXX
 SG_ BMS_a058_SW_Bandolier_Model_Rese m0 : 61|1@1+ (1,0) [0|1] "" Vector__XXX
 SG_ BMS_a059_SW_Pack_Voltage_Sensing m0 : 62|1@1+ (1,0) [0|1] "" Vector__XXX
 SG_ BMS_a060_SW_Leakage_Test_Failure m0 : 63|1@1+ (1,0) [0|1] "" Vector__XXX
 SG_ BMS_a061_SW_BrickV_Change m1 : 4|1@1+ (1,0) [0|1] "" Vector__XXX
 SG_ BMS_a062_SW_BrickV_Imbalance m1 : 5|1@1+ (1,0) [0|1] "" Vector__XXX
 SG_ BMS_a063_SW_ChargePort_Fault m1 : 6|1@1+ (1,0) [0|1] "" Vector__XXX
 SG_ BMS_a064_SW_SOC_Imbalance m1 : 7|1@1+ (1,0) [0|1] "" Vector__XXX
 SG_ BMS_a065_SW_CAC_Imbalance m1 : 8|1@1+ (1,0) [0|1] "" Vector__XXX
 SG_ BMS_a066_SOC_Imbalance_Warning m1 : 9|1@1+ (1,0) [0|1] "" Vector__XXX
 SG_ BMS_a067_CAC_Imbalance_Limiting m1 : 10|1@1+ (1,0) [0|1] "" Vector__XXX
 SG_ BMS_a068_CAC_Imbalance_Limp m1 : 11|1@1+ (1,0) [0|1] "" Vector__XXX
 SG_ BMS_a069_SW_Low_Power m1 : 12|1@1+ (1,0) [0|1] "" Vector__XXX
 SG_ BMS_a070_BrickV_Imbalance_Limiti m1 : 13|1@1+ (1,0) [0|1] "" Vector__XXX
 SG_ BMS_a071_SW_SM_TransCon_Not_Met m1 : 14|1@1+ (1,0) [0|1] "" Vector__XXX
 SG_ BMS_a072_Module_Brick_Split m1 : 15|1@1+ (1,0) [0|1] "" Vector__XXX
 SG_ BMS_a073_Unexpected_Loss_Of_Lv m1 : 16|1@1+ (1,0) [0|1] "" Vector__XXX
 SG_ BMS_a074_Max_Charge_Level_Reduce m1 : 17|1@1+ (1,0) [0|1] "" Vector__XXX
 SG_ BMS_a075_SW_Chg_Disable_Failure m1 : 18|1@1+ (1,0) [0|1] "" Vector__XXX
 SG_ BMS_a076_SW_Dch_While_Charging m1 : 19|1@1+ (1,0) [0|1] "" Vector__XXX
 SG_ BMS_a077_SW_Charger_Regulation m1 : 20|1@1+ (1,0) [0|1] "" Vector__XXX
 SG_ BMS_a078_Rapid_Dch_While_Chargin m1 : 21|1@1+ (1,0) [0|1] "" Vector__XXX
 SG_ BMS_a079_Max_Charge_Level_Exceed m1 : 22|1@1+ (1,0) [0|1] "" Vector__XXX
 SG_ BMS_a080_SW_Pack_Ctr_Impedance m1 : 23|1@1+ (1,0) [0|1] "" Vector__XXX
 SG_ BMS_a081_SW_Ctr_Close_Blocked m1 : 24|1@1+ (1,0) [0|1] "" Vector__XXX
 SG_ BMS_a082_SW_Ctr_Force_Open m1 : 25|1@1+ (1,0) [0|1] "" Vector__XXX
 SG_ BMS_a083_SW_Ctr_Close_Failure m1 : 26|1@1+ (1,0) [0|1] "" Vector__XXX
 SG_ BMS_a084_SW_Sleep_Wake_Aborted m1 : 27|1@1+ (1,0) [0|1] "" Vector__XXX
 SG_ BMS_a085_SW_Pack_Contactor_Misma m1 : 28|1@1+ (1,0) [0|1] "" Vector__XXX
 SG_ BMS_a086_SW_FC_Contactor_Mismatc m1 : 29|1@1+ (1,0) [0|1] "" Vector__XXX
 SG_ BMS_a087_SW_Feim_Test_Blocked m1 : 30|1@1+ (1,0) [0|1] "" Vector__XXX
 SG_ BMS_a088_SW_VcFront_MIA_InDrive m1 : 31|1@1+ (1,0) [0|1] "" Vector__XXX
 SG_ BMS_a089_SW_VcFront_MIA m1 : 32|1@1+ (1,0) [0|1] "" Vector__XXX
 SG_ BMS_a090_SW_Gateway_MIA m1 : 33|1@1+ (1,0) [0|1] "" Vector__XXX
 SG_ BMS_a091_SW_ChargePort_MIA m1 : 34|1@1+ (1,0) [0|1] "" Vector__XXX
 SG_ BMS_a092_SW_ChargePort_Mia_On_Hv m1 : 35|1@1+ (1,0) [0|1] "" Vector__XXX
 SG_ BMS_a094_SW_Drive_Inverter_MIA m1 : 37|1@1+ (1,0) [0|1] "" Vector__XXX
 SG_ BMS_a095_SW_UI_MIA m1 : 38|1@1+ (1,0) [0|1] "" Vector__XXX
 SG_ BMS_a097_SW_BMB_Over_CAN_Communi m1 : 40|1@1+ (1,0) [0|1] "" Vector__XXX
 SG_ BMS_a098_SW_BMB_Data_Integrity_L m1 : 41|1@1+ (1,0) [0|1] "" Vector__XXX
 SG_ BMS_a099_SW_BMB_Communication m1 : 42|1@1+ (1,0) [0|1] "" Vector__XXX
 SG_ BMS_a100_ThermalEventSuspected m1 : 43|1@1+ (1,0) [0|1] "" Vector__XXX
 SG_ BMS_a105_SW_One_Module_Tsense m1 : 48|1@1+ (1,0) [0|1] "" Vector__XXX
 SG_ BMS_a106_SW_All_Module_Tsense m1 : 49|1@1+ (1,0) [0|1] "" Vector__XXX
 SG_ BMS_a107_SW_Stack_Voltage_MIA m1 : 50|1@1+ (1,0) [0|1] "" Vector__XXX
 SG_ BMS_a108_SW_BMB_Device_OT m1 : 51|1@1+ (1,0) [0|1] "" Vector__XXX
 SG_ BMS_a109_HW_BMB_Mute_Status_Mism m1 : 52|1@1+ (1,0) [0|1] "" Vector__XXX
 SG_ BMS_a110_LifeModel_AvgOffset_Cha m1 : 53|1@1+ (1,0) [0|1] "" Vector__XXX
 SG_ BMS_a111_LifeModel_Spread_Change m1 : 54|1@1+ (1,0) [0|1] "" Vector__XXX
 SG_ BMS_a112_LifeModel_Discontinuity m1 : 55|1@1+ (1,0) [0|1] "" Vector__XXX
 SG_ BMS_a115_Energy_Rubberbanding_Re m1 : 58|1@1+ (1,0) [0|1] "" Vector__XXX
 SG_ BMS_a117_SW_Delta_SOC_Weak_Short m1 : 60|1@1+ (1,0) [0|1] "" Vector__XXX
 SG_ BMS_a119_Fast_Open_Vsh_Detected m1 : 62|1@1+ (1,0) [0|1] "" Vector__XXX
 SG_ BMS_a121_SW_NVRAM_Config_Error m2 : 4|1@1+ (1,0) [0|1] "" Vector__XXX
 SG_ BMS_a122_SW_BMS_Therm_Irrational m2 : 5|1@1+ (1,0) [0|1] "" Vector__XXX
 SG_ BMS_a123_SW_Internal_Isolation m2 : 6|1@1+ (1,0) [0|1] "" Vector__XXX
 SG_ BMS_a124_Battery_Coolant_Flood m2 : 7|1@1+ (1,0) [0|1] "" Vector__XXX
 SG_ BMS_a126_SW_Thermistor_Failure m2 : 9|1@1+ (1,0) [0|1] "" Vector__XXX
 SG_ BMS_a127_SW_shunt_SNA m2 : 10|1@1+ (1,0) [0|1] "" Vector__XXX
 SG_ BMS_a128_SW_shunt_MIA m2 : 11|1@1+ (1,0) [0|1] "" Vector__XXX
 SG_ BMS_a129_SW_VSH_Failure m2 : 12|1@1+ (1,0) [0|1] "" Vector__XXX
 SG_ BMS_a130_IO_CAN_Error m2 : 13|1@1+ (1,0) [0|1] "" Vector__XXX
 SG_ BMS_a131_Bleed_FET_Failure m2 : 14|1@1+ (1,0) [0|1] "" Vector__XXX
 SG_ BMS_a132_HW_BMB_OTP_Uncorrctbl m2 : 15|1@1+ (1,0) [0|1] "" Vector__XXX
 SG_ BMS_a133_IO_CAN_Bus_Off m2 : 16|1@1+ (1,0) [0|1] "" Vector__XXX
 SG_ BMS_a134_SW_Delayed_Ctr_Off m2 : 17|1@1+ (1,0) [0|1] "" Vector__XXX
 SG_ BMS_a135_HW_BMB_Diagnostics_Fail m2 : 18|1@1+ (1,0) [0|1] "" Vector__XXX
 SG_ BMS_a136_SW_Module_OT_Warning m2 : 19|1@1+ (1,0) [0|1] "" Vector__XXX
 SG_ BMS_a137_SW_Brick_UV_Warning m2 : 20|1@1+ (1,0) [0|1] "" Vector__XXX
 SG_ BMS_a138_SW_Brick_OV_Warning m2 : 21|1@1+ (1,0) [0|1] "" Vector__XXX
 SG_ BMS_a139_SW_DC_Link_V_Irrational m2 : 22|1@1+ (1,0) [0|1] "" Vector__XXX
 SG_ BMS_a140_HW_BMB_Status_Fault m2 : 23|1@1+ (1,0) [0|1] "" Vector__XXX
 SG_ BMS_a141_SW_BMB_Status_Warning m2 : 24|1@1+ (1,0) [0|1] "" Vector__XXX
 SG_ BMS_a142_SW_Isolation_Degradatio m2 : 25|1@1+ (1,0) [0|1] "" Vector__XXX
 SG_ BMS_a143_SW_CAC_Change m2 : 26|1@1+ (1,0) [0|1] "" Vector__XXX
 SG_ BMS_a144_Hvp_Config_Mismatch m2 : 27|1@1+ (1,0) [0|1] "" Vector__XXX
 SG_ BMS_a145_SW_SOC_Change m2 : 28|1@1+ (1,0) [0|1] "" Vector__XXX
 SG_ BMS_a146_SW_Brick_Overdischarged m2 : 29|1@1+ (1,0) [0|1] "" Vector__XXX
 SG_ BMS_a147_SW_SOC_High_Ah_Error m2 : 30|1@1+ (1,0) [0|1] "" Vector__XXX
 SG_ BMS_a148_SW_Unsupported_BMB_ASIC m2 : 31|1@1+ (1,0) [0|1] "" Vector__XXX
 SG_ BMS_a149_SW_Missing_Config_Block m2 : 32|1@1+ (1,0) [0|1] "" Vector__XXX
 SG_ BMS_a150_SW_Missing_Part_Number m2 : 33|1@1+ (1,0) [0|1] "" Vector__XXX
 SG_ BMS_a151_SW_external_isolation m2 : 34|1@1+ (1,0) [0|1] "" Vector__XXX
 SG_ BMS_a152_Isolation_In_Dc_Charge m2 : 35|1@1+ (1,0) [0|1] "" Vector__XXX
 SG_ BMS_a154_SW_Brick_OV_Warning_Sto m2 : 37|1@1+ (1,0) [0|1] "" Vector__XXX
 SG_ BMS_a155_SW_Weak_short_impedence m2 : 38|1@1+ (1,0) [0|1] "" Vector__XXX
 SG_ BMS_a156_SW_BMB_Vref_bad m2 : 39|1@1+ (1,0) [0|1] "" Vector__XXX
 SG_ BMS_a157_SW_Hist_Update_Missed m2 : 40|1@1+ (1,0) [0|1] "" Vector__XXX
 SG_ BMS_a158_SW_HVP_HVI_Comms m2 : 41|1@1+ (1,0) [0|1] "" Vector__XXX
 SG_ BMS_a159_SW_HVP_ECU_Error m2 : 42|1@1+ (1,0) [0|1] "" Vector__XXX
 SG_ BMS_a160_SW_FC_Ctr_Clean_Failed m2 : 43|1@1+ (1,0) [0|1] "" Vector__XXX
 SG_ BMS_a161_SW_BMB_Vref_warning m2 : 44|1@1+ (1,0) [0|1] "" Vector__XXX
 SG_ BMS_a162_SW_No_Power_For_Support m2 : 45|1@1+ (1,0) [0|1] "" Vector__XXX
 SG_ BMS_a164_SW_Uncontrolled_Regen m2 : 47|1@1+ (1,0) [0|1] "" Vector__XXX
 SG_ BMS_a165_SW_Pack_Partial_Weld m2 : 48|1@1+ (1,0) [0|1] "" Vector__XXX
 SG_ BMS_a166_SW_Pack_Full_Weld m2 : 49|1@1+ (1,0) [0|1] "" Vector__XXX
 SG_ BMS_a167_SW_FC_Partial_Weld m2 : 50|1@1+ (1,0) [0|1] "" Vector__XXX
 SG_ BMS_a168_SW_FC_Full_Weld m2 : 51|1@1+ (1,0) [0|1] "" Vector__XXX
 SG_ BMS_a169_SW_FC_Pack_Weld m2 : 52|1@1+ (1,0) [0|1] "" Vector__XXX
 SG_ BMS_a170_SW_Limp_Mode m2 : 53|1@1+ (1,0) [0|1] "" Vector__XXX
 SG_ BMS_a171_SW_Stack_Voltage_Sense m2 : 54|1@1+ (1,0) [0|1] "" Vector__XXX
 SG_ BMS_a172_SW_Isolation_Failure_In m2 : 55|1@1+ (1,0) [0|1] "" Vector__XXX
 SG_ BMS_a174_SW_Charge_Failure m2 : 57|1@1+ (1,0) [0|1] "" Vector__XXX
 SG_ BMS_a175_Charge_Failure_External m2 : 58|1@1+ (1,0) [0|1] "" Vector__XXX
 SG_ BMS_a176_SW_GracefulPowerOff m2 : 59|1@1+ (1,0) [0|1] "" Vector__XXX
 SG_ BMS_a177_SW_Energy_Buffer_Size m2 : 60|1@1+ (1,0) [0|1] "" Vector__XXX
 SG_ BMS_a178_SW_Uncontrolled_Regen_P m2 : 61|1@1+ (1,0) [0|1] "" Vector__XXX
 SG_ BMS_a179_HvpGpoRequestActive m2 : 62|1@1+ (1,0) [0|1] "" Vector__XXX
 SG_ BMS_a180_SW_ECU_reset_blocked m2 : 63|1@1+ (1,0) [0|1] "" Vector__XXX
 SG_ BMS_a181_SW_Shunt_Over_Temperatu m3 : 4|1@1+ (1,0) [0|1] "" Vector__XXX
 SG_ BMS_a182_LifeModel_NoCurrentLoss m3 : 5|1@1+ (1,0) [0|1] "" Vector__XXX
 SG_ BMS_a183_LifeModel_StoDcrGrowth_ m3 : 6|1@1+ (1,0) [0|1] "" Vector__XXX
 SG_ BMS_a184_LifeModel_CyclingLoss_C m3 : 7|1@1+ (1,0) [0|1] "" Vector__XXX
 SG_ BMS_a185_LifeModel_CyclingDcrGro m3 : 8|1@1+ (1,0) [0|1] "" Vector__XXX
 SG_ BMS_a186_RippleHeatingChargeFaul m3 : 9|1@1+ (1,0) [0|1] "" Vector__XXX
 SG_ BMS_a187_RippleHeatingEmergencyS m3 : 10|1@1+ (1,0) [0|1] "" Vector__XXX
 SG_ BMS_a188_DtcConfirmed m3 : 11|1@1+ (1,0) [0|1] "" Vector__XXX

BO_ 818 BMS_bmbMinMax: 6 BMS
 SG_ BMS_bmbMinMaxMultiplexer M : 0|2@1+ (1,0) [0|3] "" Vector__XXX
 SG_ BMS_thermistorNumTMin m0 : 2|4@1+ (1,0) [0|15] "" Vector__XXX
 SG_ BMS_thermistorNumTMax m0 : 8|4@1+ (1,0) [0|15] "" Vector__XXX
 SG_ BMS_thermistorTMax m0 : 16|8@1+ (0.5,-40) [-40|87.5] "DegC" Vector__XXX
 SG_ BMS_thermistorTMin m0 : 24|8@1+ (0.5,-40) [-40|87.5] "DegC" Vector__XXX
 SG_ BMS_thermistorTAvg m0 : 32|8@1+ (0.5,-40) [-40|87.5] "DegC" Vector__XXX
 SG_ BMS_brickVoltageMax m1 : 2|12@1+ (0.002,0) [0|5] "V" Vector__XXX
 SG_ BMS_brickVoltageMin m1 : 16|12@1+ (0.002,0) [0|5] "V" Vector__XXX
 SG_ BMS_brickNumVoltageMax m1 : 32|7@1+ (1,1) [1|128] "" Vector__XXX
 SG_ BMS_brickNumVoltageMin m1 : 40|7@1+ (1,1) [1|128] "" Vector__XXX

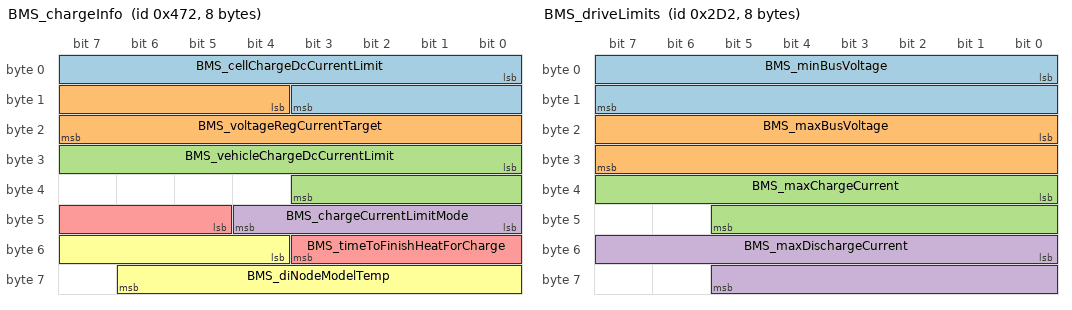
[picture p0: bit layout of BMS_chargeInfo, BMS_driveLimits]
BO_ 1138 BMS_chargeInfo: 8 BMS
 SG_ BMS_cellChargeDcCurrentLimit : 0|12@1+ (0.5,0) [0|2047.5] "A" Vector__XXX
 SG_ BMS_voltageRegCurrentTarget : 12|12@1+ (0.5,0) [0|2047.5] "A" Vector__XXX
 SG_ BMS_vehicleChargeDcCurrentLimit : 24|12@1+ (0.5,0) [0|2047.5] "A" Vector__XXX
 SG_ BMS_chargeCurrentLimitMode : 40|5@1+ (1,0) [0|31] "" Vector__XXX
 SG_ BMS_timeToFinishHeatForCharge : 45|7@1+ (5,0) [0|600] "min" Vector__XXX
 SG_ BMS_diNodeModelTemp : 52|11@1+ (0.1,-50) [-50|154.6] "degC" Vector__XXX

BO_ 562 BMS_contactorRequest: 8 BMS
 SG_ BMS_internalHvilSenseV : 16|16@1+ (0.001,0) [0|65.534] "V" Vector__XXX
 SG_ BMS_hvilCoverVSense : 32|16@1+ (0.001,0) [0|65.534] "V" Vector__XXX

BO_ 2029 BMS_debugInfo_10Hz: 8 BMS
 SG_ BMS_10HzDebug_Id M : 0|6@1+ (1,0) [0|63] "" Vector__XXX
 SG_ BMS_activeCoolCellTargetT m33 : 6|9@1+ (0.25,-25) [-25|100] "DegC" Vector__XXX
 SG_ BMS_passiveCoolCellTargetT m33 : 15|9@1+ (0.25,-25) [-25|100] "DegC" Vector__XXX

BO_ 722 BMS_driveLimits: 8 BMS
 SG_ BMS_minBusVoltage : 0|16@1+ (0.02,0) [0|1200] "V" Vector__XXX
 SG_ BMS_maxBusVoltage : 16|16@1+ (0.02,0) [0|1200] "V" Vector__XXX
 SG_ BMS_maxChargeCurrent : 32|14@1+ (0.1,0) [0|1638.2] "A" Vector__XXX
 SG_ BMS_maxDischargeCurrent : 48|14@1+ (0.15,0) [0|2455] "A" Vector__XXX

BO_ 690 BMS_energyStatus: 8 BMS
 SG_ BMS_energyStatusMultiplexer M : 0|2@1+ (1,0) [0|3] "" Vector__XXX
 SG_ BMS_nominalFullPackEnergy m0 : 16|16@1+ (0.02,0) [0|1310.68] "kWh" Vector__XXX
 SG_ BMS_nominalEnergyRemaining m0 : 32|16@1+ (0.02,0) [0|1310.68] "kWh" Vector__XXX
 SG_ BMS_idealEnergyRemaining m0 : 48|16@1+ (0.02,0) [0|1310.68] "kWh" Vector__XXX
 SG_ BMS_fullChargeComplete m1 : 15|1@1+ (1,0) [0|1] "" Vector__XXX
 SG_ BMS_energyBuffer m1 : 16|16@1+ (0.01,0) [0|655.34] "kWh" Vector__XXX
 SG_ BMS_expectedEnergyRemaining m1 : 32|16@1+ (0.02,0) [0|1310.68] "kWh" Vector__XXX
 SG_ BMS_energyToChargeComplete m1 : 48|16@1+ (0.02,0) [0|1310.68] "kWh" Vector__XXX
 SG_ BMS_energyRemainingDisplay m2 : 8|16@1+ (0.02,0) [0|1310.68] "kWh" Vector__XXX
 SG_ BMS_energyRemainingTDisplay m2 : 24|16@1+ (0.02,0) [0|1310.68] "kWh" Vector__XXX
 SG_ BMS_energyDisplayErrorBlendRate m2 : 40|12@1+ (0.0156288165599,0) [0|64] "%" Vector__XXX
 SG_ BMS_userFacingSoe m2 : 52|11@1+ (0.05,0) [0|100] "%" Vector__XXX

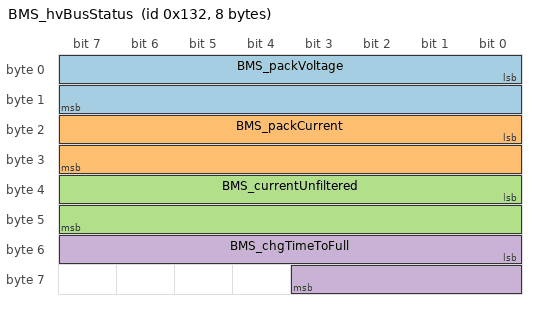
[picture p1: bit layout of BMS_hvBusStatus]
BO_ 306 BMS_hvBusStatus: 8 BMS
 SG_ BMS_packVoltage : 0|16@1+ (0.01,0) [0|655.35] "V" Vector__XXX
 SG_ BMS_packCurrent : 16|16@1- (0.1,0) [-3276.7|3276.7] "A" Vector__XXX
 SG_ BMS_currentUnfiltered : 32|16@1- (0.05,-822) [-2460.3|816.3] "A" Vector__XXX
 SG_ BMS_chgTimeToFull : 48|12@1+ (0.01666667,0) [0|68.23334698] "Hours" Vector__XXX

BO_ 768 BMS_info: 8 BMS
 SG_ BMS_infoIndex M : 0|8@1+ (1,0) [0|255] "" Vector__XXX
 SG_ BMS_buildType m10 : 8|3@1+ (1,0) [0|7] "" Vector__XXX
 SG_ BMS_buildConfigId m10 : 16|16@1+ (1,0) [0|65535] "" Vector__XXX
 SG_ BMS_hardwareId m10 : 32|16@1+ (1,0) [0|65535] "" Vector__XXX
 SG_ BMS_componentId m10 : 48|16@1+ (1,0) [0|65535] "" Vector__XXX
 SG_ BMS_pcbaId m11 : 16|8@1+ (1,0) [0|255] "" Vector__XXX
 SG_ BMS_assemblyId m11 : 24|8@1+ (1,0) [0|255] "" Vector__XXX
 SG_ BMS_usageId m11 : 32|16@1+ (1,0) [0|65535] "" Vector__XXX
 SG_ BMS_subUsageId m11 : 48|16@1+ (1,0) [0|65535] "" Vector__XXX
 SG_ BMS_platformType m13 : 8|8@1+ (1,0) [0|255] "" Vector__XXX
 SG_ BMS_appCrc m13 : 32|32@1+ (1,0) [0|4294967295] "" Vector__XXX
 SG_ BMS_appGitHash m17 : 8|56@1+ (1,0) [0|7.20575940379e+16] "" Vector__XXX
 SG_ BMS_bootGitHash m18 : 8|56@1+ (1,0) [0|7.20575940379e+16] "" Vector__XXX
 SG_ BMS_bootUdsProtoVersion m20 : 8|8@1+ (1,0) [0|255] "" Vector__XXX
 SG_ BMS_bootCrc m20 : 32|32@1+ (1,0) [0|4294967295] "" Vector__XXX

BO_ 978 BMS_kwhCounter: 8 BMS
 SG_ BMS_kwhDischargeTotal : 0|32@1+ (0.001,0) [0|268435.456] "KWh" Vector__XXX
 SG_ BMS_kwhChargeTotal : 32|32@1+ (0.001,0) [0|268435.456] "KWh" Vector__XXX

BO_ 1010 BMS_kwhCountersMultiplexed: 8 BMS
 SG_ BMS_kwhCounter_Id M : 0|4@1+ (1,0) [0|15] "" Vector__XXX
 SG_ BMS_acChargerKwhTotal m0 : 8|32@1+ (0.001,0) [0|268435.456] "KWh" Vector__XXX
 SG_ BMS_dcChargerKwhTotal m1 : 8|32@1+ (0.001,0) [0|268435.456] "KWh" Vector__XXX
 SG_ BMS_kwhRegenChargeTotal m2 : 8|32@1+ (0.001,0) [0|268435.456] "KWh" Vector__XXX
 SG_ BMS_kwhDriveDischargeTotal m3 : 8|32@1+ (0.001,0) [0|268435.456] "KWh" Vector__XXX
 SG_ BMS_kwhDischargeTotalModule1 m4 : 8|28@1+ (0.001,0) [0|268435.455] "KWh" Vector__XXX
 SG_ BMS_kwhChargeTotalModule1 m4 : 36|28@1+ (0.001,0) [0|268435.455] "KWh" Vector__XXX
 SG_ BMS_kwhAcChargeTotalModule1 m5 : 8|28@1+ (0.001,0) [0|268435.455] "KWh" Vector__XXX
 SG_ BMS_kwhDcChargeTotalModule1 m5 : 36|28@1+ (0.001,0) [0|268435.455] "KWh" Vector__XXX
 SG_ BMS_kwhDischargeTotalModule2 m6 : 8|28@1+ (0.001,0) [0|268435.455] "KWh" Vector__XXX
 SG_ BMS_kwhChargeTotalModule2 m6 : 36|28@1+ (0.001,0) [0|268435.455] "KWh" Vector__XXX
 SG_ BMS_kwhAcChargeTotalModule2 m7 : 8|28@1+ (0.001,0) [0|268435.455] "KWh" Vector__XXX
 SG_ BMS_kwhDcChargeTotalModule2 m7 : 36|28@1+ (0.001,0) [0|268435.455] "KWh" Vector__XXX
 SG_ BMS_kwhDischargeTotalModule3 m8 : 8|28@1+ (0.001,0) [0|268435.455] "KWh" Vector__XXX
 SG_ BMS_kwhChargeTotalModule3 m8 : 36|28@1+ (0.001,0) [0|268435.455] "KWh" Vector__XXX
 SG_ BMS_kwhAcChargeTotalModule3 m9 : 8|28@1+ (0.001,0) [0|268435.455] "KWh" Vector__XXX
 SG_ BMS_kwhDcChargeTotalModule3 m9 : 36|28@1+ (0.001,0) [0|268435.455] "KWh" Vector__XXX
 SG_ BMS_kwhDischargeTotalModule4 m10 : 8|28@1+ (0.001,0) [0|268435.455] "KWh" Vector__XXX
 SG_ BMS_kwhChargeTotalModule4 m10 : 36|28@1+ (0.001,0) [0|268435.455] "KWh" Vector__XXX
 SG_ BMS_kwhAcChargeTotalModule4 m11 : 8|28@1+ (0.001,0) [0|268435.455] "KWh" Vector__XXX
 SG_ BMS_kwhDcChargeTotalModule4 m11 : 36|28@1+ (0.001,0) [0|268435.455] "KWh" Vector__XXX

BO_ 884 BMS_log1: 8 BMS
 SG_ BMS_log1MuxId M : 0|8@1+ (1,0) [0|255] "" Vector__XXX
 SG_ BMS_hvChargeStatus m8 : 16|4@1+ (1,0) [0|15] "" Vector__XXX
 SG_ BMS_extDcPrechargeVoltageLimit m8 : 20|12@1+ (0.146502256393,0) [0|599.926739929] "V" Vector__XXX
 SG_ BMS_dcChargeCurrentRequest m8 : 32|14@1- (0.25,0) [-2048|2047.75] "A" Vector__XXX
 SG_ BMS_dcChargeCurrentLimit m8 : 46|13@1- (0.5,0) [-2048|2047.5] "A" Vector__XXX
 SG_ BMS_dcDischargeEnabled m8 : 59|1@1+ (1,0) [0|1] "" Vector__XXX
 SG_ BMS_rippleChargeRetryCount m8 : 60|3@1+ (1,0) [0|7] "" Vector__XXX
 SG_ BMS_dcChargeVoltageLimit m9 : 8|12@1+ (0.146502256393,0) [0|599.926739929] "V" Vector__XXX
 SG_ BMS_dcChargePowerLimit m9 : 20|12@1- (1,0) [-2048|2047] "kW" Vector__XXX
 SG_ BMS_acChargePowerRequest m9 : 32|16@1+ (0.001,0) [0|65.535] "kW" Vector__XXX
 SG_ BMS_maxExtIsoFcLinkV m9 : 48|13@1+ (0.134293735027,0) [0|1099.99998361] "V" Vector__XXX
 SG_ BMS_minModeledPackTemp m10 : 8|11@1+ (0.1,-50) [-50|154.7] "C" Vector__XXX
 SG_ BMS_maxModeledPackTemp m10 : 19|11@1+ (0.1,-50) [-50|154.7] "C" Vector__XXX
 SG_ BMS_socByDeltaVEnabled m15 : 8|1@1+ (1,0) [0|1] "" Vector__XXX
 SG_ BMS_socByDvMaxSocLimit m15 : 9|10@1+ (0.1,0) [0|102.2] "%" Vector__XXX
 SG_ BMS_socByDvVoltageChangeOverAh m15 : 19|9@1+ (0.002,0) [0|1] "V" Vector__XXX
 SG_ BMS_socByDvMaxSocByAhCorrected m15 : 28|10@1+ (0.1,0) [0|102.2] "%" Vector__XXX
 SG_ BMS_socByDvMaxBrickVoltage m15 : 40|12@1+ (0.002,0) [0|5] "V" Vector__XXX
 SG_ BMS_socByDvMaxBrickId m15 : 56|8@1+ (1,1) [1|256] "" Vector__XXX

BO_TX_BU_ 1343 : BMS;
BO_TX_BU_ 800 : BMS;
BO_TX_BU_ 818 : BMS;
BO_TX_BU_ 1138 : BMS;
BO_TX_BU_ 562 : BMS;
BO_TX_BU_ 2029 : BMS;
BO_TX_BU_ 722 : BMS;
BO_TX_BU_ 690 : BMS;
BO_TX_BU_ 306 : BMS;
BO_TX_BU_ 768 : BMS;
BO_TX_BU_ 978 : BMS;
BO_TX_BU_ 1010 : BMS;
BO_TX_BU_ 884 : BMS;
CM_ BO_ 1343 "High-voltage battery management system message: alert log";
CM_ SG_ 1343 BMS_alertID "High-voltage battery management system: alert ID; raw 127 = signal not available (SNA)";
CM_ SG_ 1343 BMS_alertSet "High-voltage battery management system: alert set";
CM_ SG_ 1343 BMS_a001_gatewayPackEnergy "High-voltage battery management system: a001 gateway pack energy";
CM_ SG_ 1343 BMS_a001_expectedPackEnergy "High-voltage battery management system: a001 expected pack energy";
CM_ SG_ 1343 BMS_a002_gatewayPackPerformanceD "High-voltage battery management system: a002 gateway pack performance deviation";
CM_ SG_ 1343 BMS_a002_expectedPackPerformance "High-voltage battery management system: a002 expected pack performance deviation";
CM_ SG_ 1343 BMS_a002_bmsPackMass "High-voltage battery management system: a002 bms pack mass";
CM_ SG_ 1343 BMS_a003_calBlockData_0 "High-voltage battery management system: a003 cal block data 0";
CM_ SG_ 1343 BMS_a007_minPackTemperature "High-voltage battery management system: a007 min pack temperature";
CM_ SG_ 1343 BMS_a007_packCurrent "High-voltage battery management system: a007 pack current";
CM_ SG_ 1343 BMS_a007_idealCurrentTarget "High-voltage battery management system: a007 ideal current target";
CM_ SG_ 1343 BMS_a017_packCurrent "High-voltage battery management system: a017 pack current";
CM_ SG_ 1343 BMS_a017_ovBrickVID "High-voltage battery management system: a017 ov brick VID";
CM_ SG_ 1343 BMS_a017_ovBrickV "High-voltage battery management system: a017 ov brick v";
CM_ SG_ 1343 BMS_a018_packCurrent "High-voltage battery management system: a018 pack current";
CM_ SG_ 1343 BMS_a018_uvBrickVID "High-voltage battery management system: a018 uv brick VID";
CM_ SG_ 1343 BMS_a018_uvBrickV "High-voltage battery management system: a018 uv brick v";
CM_ SG_ 1343 BMS_a019_coolantInletT "High-voltage battery management system: a019 coolant inlet t";
CM_ SG_ 1343 BMS_a019_activeCoolingTarget "High-voltage battery management system: a019 active cooling target";
CM_ SG_ 1343 BMS_a019_maxBrickT "High-voltage battery management system: a019 max brick t";
CM_ SG_ 1343 BMS_a019_maxBrickTID "High-voltage battery management system: a019 max brick TID";
CM_ SG_ 1343 BMS_a021_chargeViolation "High-voltage battery management system: a021 charge violation";
CM_ SG_ 1343 BMS_a021_currentLimit "High-voltage battery management system: a021 current limit";
CM_ SG_ 1343 BMS_a021_packCurrent "High-voltage battery management system: a021 pack current";
CM_ SG_ 1343 BMS_a022_chargeAccumulatorViolat "High-voltage battery management system: a022 charge accumulator violation";
CM_ SG_ 1343 BMS_a022_chargeAccumulatorValue "High-voltage battery management system: a022 charge accumulator value";
CM_ SG_ 1343 BMS_a022_chargeAccumulatorLimit "High-voltage battery management system: a022 charge accumulator limit";
CM_ SG_ 1343 BMS_a023_ovStackDeviceID "High-voltage battery management system: a023 ov stack device ID";
CM_ SG_ 1343 BMS_a023_ovStackV "High-voltage battery management system: a023 ov stack v";
CM_ SG_ 1343 BMS_a024_brickID "High-voltage battery management system: a024 brick ID";
CM_ SG_ 1343 BMS_a024_deltaV "High-voltage battery management system: a024 delta v";
CM_ SG_ 1343 BMS_a024_avgDvPrev "High-voltage battery management system: a024 avg dv prev";
CM_ SG_ 1343 BMS_a024_packCurrent "High-voltage battery management system: a024 pack current";
CM_ SG_ 1343 BMS_a027_swIsolationCount "High-voltage battery management system: a027 sw isolation count";
CM_ SG_ 1343 BMS_a027_swIsoDegradationCount "High-voltage battery management system: a027 sw iso degradation count";
CM_ SG_ 1343 BMS_a030_worstBrickID "High-voltage battery management system: a030 worst brick ID";
CM_ SG_ 1343 BMS_a030_maxBrickImpedance "High-voltage battery management system: a030 max brick impedance";
CM_ SG_ 1343 BMS_a030_maxNormalizedImpedanceD "High-voltage battery management system: a030 max normalized impedance dev";
CM_ SG_ 1343 BMS_a030_faultThreshold "High-voltage battery management system: a030 fault threshold";
CM_ SG_ 1343 BMS_a030_numBricks "High-voltage battery management system: a030 num bricks";
CM_ SG_ 1343 BMS_a030_worstBrickSoc "High-voltage battery management system: a030 worst brick soc";
CM_ SG_ 1343 BMS_a035_isoR "High-voltage battery management system: a035 iso r";
CM_ SG_ 1343 BMS_a035_mode "High-voltage battery management system: a035 mode";
CM_ SG_ 1343 BMS_a035_activeSideVNoR "High-voltage battery management system: a035 active side v no r";
CM_ SG_ 1343 BMS_a035_activeSideVWithR "High-voltage battery management system: a035 active side v with r";
CM_ SG_ 1343 BMS_a035_passiveSideVNoR "High-voltage battery management system: a035 passive side v no r";
CM_ SG_ 1343 BMS_a035_passiveSideVWithR "High-voltage battery management system: a035 passive side v with r";
CM_ SG_ 1343 BMS_a037_floodPort1State "High-voltage battery management system: a037 flood port1 state; raw 0 = signal not available (SNA)";
CM_ SG_ 1343 BMS_a037_floodPort1Voltage "High-voltage battery management system: a037 flood port1 voltage";
CM_ SG_ 1343 BMS_a037_floodPort2State "High-voltage battery management system: a037 flood port2 state; raw 0 = signal not available (SNA)";
CM_ SG_ 1343 BMS_a037_floodPort2Voltage "High-voltage battery management system: a037 flood port2 voltage";
CM_ SG_ 1343 BMS_a039_dcLinkVoltage "High-voltage battery management system: a039 dc link voltage";
CM_ SG_ 1343 BMS_a039_packVoltage "High-voltage battery management system: a039 pack voltage";
CM_ SG_ 1343 BMS_a039_packContactorState "High-voltage battery management system: a039 pack contactor state; raw 0 = signal not available (SNA)";
CM_ SG_ 1343 BMS_a039_packCurrent "High-voltage battery management system: a039 pack current";
CM_ SG_ 1343 BMS_a039_maxBrickV "High-voltage battery management system: a039 max brick v";
CM_ SG_ 1343 BMS_a039_state "High-voltage battery management system: a039 state; raw 9 = signal not available (SNA)";
CM_ SG_ 1343 BMS_a041_resetType "High-voltage battery management system: a041 reset type";
CM_ SG_ 1343 BMS_a050_MIA_numBadReadings "High-voltage battery management system: a050 MIA num bad readings";
CM_ SG_ 1343 BMS_a050_MIA_numSnaReadings "High-voltage battery management system: a050 MIA num sna readings";
CM_ SG_ 1343 BMS_a051_hvp1V5Ref "High-voltage battery management system: a051 hvp1 V5 ref";
CM_ SG_ 1343 BMS_a051_hvp3V0Ref "High-voltage battery management system: a051 hvp3 V0 ref";
CM_ SG_ 1343 BMS_a051_bms3V0Ref "High-voltage battery management system: a051 bms3 V0 ref";
CM_ SG_ 1343 BMS_a056_standbySupplyOutV "High-voltage battery management system: a056 standby supply out v";
CM_ SG_ 1343 BMS_a056_packVoltage "High-voltage battery management system: a056 pack voltage";
CM_ SG_ 1343 BMS_a056_minBrickVoltage "High-voltage battery management system: a056 min brick voltage";
CM_ SG_ 1343 BMS_a056_standbyEnabled "High-voltage battery management system: a056 standby enabled";
CM_ SG_ 1343 BMS_a056_standbySwGood "High-voltage battery management system: a056 standby sw good";
CM_ SG_ 1343 BMS_a056_ssOutTooHigh "High-voltage battery management system: a056 ss out too high";
CM_ SG_ 1343 BMS_a056_ssOutTooLow "High-voltage battery management system: a056 ss out too low";
CM_ SG_ 1343 BMS_a056_ssStuckOn "High-voltage battery management system: a056 ss stuck on";
CM_ SG_ 1343 BMS_a056_ssStuckOff "High-voltage battery management system: a056 ss stuck off";
CM_ SG_ 1343 BMS_a058_bandoThmModelState "High-voltage battery management system: a058 bando thm model state; raw 0 = signal not available (SNA)";
CM_ SG_ 1343 BMS_a058_thermistorTempsInvalid "High-voltage battery management system: a058 thermistor temps invalid";
CM_ SG_ 1343 BMS_a058_inletCoolantTempInvalid "High-voltage battery management system: a058 inlet coolant temp invalid";
CM_ SG_ 1343 BMS_a058_ambientTempInvalid "High-voltage battery management system: a058 ambient temp invalid";
CM_ SG_ 1343 BMS_a058_flowRateInvalid "High-voltage battery management system: a058 flow rate invalid";
CM_ SG_ 1343 BMS_a058_brickDissipationInvalid "High-voltage battery management system: a058 brick dissipation invalid";
CM_ SG_ 1343 BMS_a058_sanityCheckFailed "High-voltage battery management system: a058 sanity check failed";
CM_ SG_ 1343 BMS_a058_tempDelta1 "High-voltage battery management system: a058 temp delta1";
CM_ SG_ 1343 BMS_a058_tempDelta2 "High-voltage battery management system: a058 temp delta2";
CM_ SG_ 1343 BMS_a058_tempDelta3 "High-voltage battery management system: a058 temp delta3";
CM_ SG_ 1343 BMS_a058_tempDelta4 "High-voltage battery management system: a058 temp delta4";
CM_ SG_ 1343 BMS_a059_sumBrickVoltages "High-voltage battery management system: a059 sum brick voltages";
CM_ SG_ 1343 BMS_a059_packVoltage "High-voltage battery management system: a059 pack voltage";
CM_ SG_ 1343 BMS_a062_state "High-voltage battery management system: a062 state; raw 9 = signal not available (SNA)";
CM_ SG_ 1343 BMS_a062_minBrickVId "High-voltage battery management system: a062 min brick v id";
CM_ SG_ 1343 BMS_a062_minBrickVoltage "High-voltage battery management system: a062 min brick voltage";
CM_ SG_ 1343 BMS_a062_maxBrickVId "High-voltage battery management system: a062 max brick v id";
CM_ SG_ 1343 BMS_a062_maxBrickVoltage "High-voltage battery management system: a062 max brick voltage";
CM_ SG_ 1343 BMS_a063_cpFaultInV "High-voltage battery management system: a063 cp fault in v";
CM_ SG_ 1343 BMS_a064_minBrickSOCID "High-voltage battery management system: a064 min brick SOCID";
CM_ SG_ 1343 BMS_a064_minBrickSOC "High-voltage battery management system: a064 min brick SOC";
CM_ SG_ 1343 BMS_a064_maxBrickSOCID "High-voltage battery management system: a064 max brick SOCID";
CM_ SG_ 1343 BMS_a064_maxBrickSOC "High-voltage battery management system: a064 max brick SOC";
CM_ SG_ 1343 BMS_a064_avgBrickSOC "High-voltage battery management system: a064 avg brick SOC";
CM_ SG_ 1343 BMS_a065_minBrickCacId "High-voltage battery management system: a065 min brick cac id";
CM_ SG_ 1343 BMS_a065_minBrickCac "High-voltage battery management system: a065 min brick cac";
CM_ SG_ 1343 BMS_a065_avgBrickCac "High-voltage battery management system: a065 avg brick cac";
CM_ SG_ 1343 BMS_a065_modCacImbalancePct "High-voltage battery management system: a065 mod cac imbalance pct";
CM_ SG_ 1343 BMS_a066_minBrickSocId "High-voltage battery management system: a066 min brick soc id";
CM_ SG_ 1343 BMS_a066_minBrickSocByOcvMax "High-voltage battery management system: a066 min brick soc by ocv max";
CM_ SG_ 1343 BMS_a066_maxBrickSocId "High-voltage battery management system: a066 max brick soc id";
CM_ SG_ 1343 BMS_a066_maxBrickSocByOcvMin "High-voltage battery management system: a066 max brick soc by ocv min";
CM_ SG_ 1343 BMS_a066_maxBrickSoc "High-voltage battery management system: a066 max brick soc";
CM_ SG_ 1343 BMS_a066_avgBrickSoc "High-voltage battery management system: a066 avg brick soc";
CM_ SG_ 1343 BMS_a067_minBrickCacId "High-voltage battery management system: a067 min brick cac id";
CM_ SG_ 1343 BMS_a067_minBrickCac "High-voltage battery management system: a067 min brick cac";
CM_ SG_ 1343 BMS_a067_avgBrickCac "High-voltage battery management system: a067 avg brick cac";
CM_ SG_ 1343 BMS_a067_modCacImbalancePct "High-voltage battery management system: a067 mod cac imbalance pct";
CM_ SG_ 1343 BMS_a068_minBrickCacId "High-voltage battery management system: a068 min brick cac id";
CM_ SG_ 1343 BMS_a068_minBrickCac "High-voltage battery management system: a068 min brick cac";
CM_ SG_ 1343 BMS_a068_avgBrickCac "High-voltage battery management system: a068 avg brick cac";
CM_ SG_ 1343 BMS_a068_modCacImbalancePct "High-voltage battery management system: a068 mod cac imbalance pct";
CM_ SG_ 1343 BMS_a069_dischargePowerPackVolta "High-voltage battery management system: a069 discharge power pack voltage floor";
CM_ SG_ 1343 BMS_a069_dischargePowerBrickVolt "High-voltage battery management system: a069 discharge power brick voltage floor";
CM_ SG_ 1343 BMS_a069_SOC "High-voltage battery management system: a069 SOC";
CM_ SG_ 1343 BMS_a069_minBrickT "High-voltage battery management system: a069 min brick t";
CM_ SG_ 1343 BMS_a069_minBrickVLimit "High-voltage battery management system: a069 min brick v limit";
CM_ SG_ 1343 BMS_a069_minBrickV "High-voltage battery management system: a069 min brick v";
CM_ SG_ 1343 BMS_a070_state "High-voltage battery management system: a070 state; raw 9 = signal not available (SNA)";
CM_ SG_ 1343 BMS_a070_minBrickVId "High-voltage battery management system: a070 min brick v id";
CM_ SG_ 1343 BMS_a070_minBrickVoltage "High-voltage battery management system: a070 min brick voltage";
CM_ SG_ 1343 BMS_a070_maxBrickVId "High-voltage battery management system: a070 max brick v id";
CM_ SG_ 1343 BMS_a070_maxBrickVoltage "High-voltage battery management system: a070 max brick voltage";
CM_ SG_ 1343 BMS_a071_stateRequest "High-voltage battery management system: a071 state request; raw 9 = signal not available (SNA)";
CM_ SG_ 1343 BMS_a071_state "High-voltage battery management system: a071 state; raw 9 = signal not available (SNA)";
CM_ SG_ 1343 BMS_a071_transitionAlertId "High-voltage battery management system: a071 transition alert id";
CM_ SG_ 1343 BMS_a074_maxBrickVTarget "High-voltage battery management system: a074 max brick v target";
CM_ SG_ 1343 BMS_a074_maxBrickV "High-voltage battery management system: a074 max brick v";
CM_ SG_ 1343 BMS_a075_chargeType "High-voltage battery management system: a075 charge type";
CM_ SG_ 1343 BMS_a076_netAh "High-voltage battery management system: a076 net ah";
CM_ SG_ 1343 BMS_a076_tetheringActive "High-voltage battery management system: a076 tethering active";
CM_ SG_ 1343 BMS_a078_peakDchInChg "High-voltage battery management system: a078 peak dch in chg; raw 32768 = signal not available (SNA)";
CM_ SG_ 1343 BMS_a079_maxBrickVTarget "High-voltage battery management system: a079 max brick v target";
CM_ SG_ 1343 BMS_a079_maxBrickV "High-voltage battery management system: a079 max brick v";
CM_ SG_ 1343 BMS_a081_stateRequest "High-voltage battery management system: a081 state request; raw 9 = signal not available (SNA)";
CM_ SG_ 1343 BMS_a081_firstBlockingAlertId "High-voltage battery management system: a081 first blocking alert id; raw 127 = signal not available (SNA)";
CM_ SG_ 1343 BMS_a081_secondBlockingAlertId "High-voltage battery management system: a081 second blocking alert id; raw 127 = signal not available (SNA)";
CM_ SG_ 1343 BMS_a081_thirdBlockingAlertId "High-voltage battery management system: a081 third blocking alert id; raw 127 = signal not available (SNA)";
CM_ SG_ 1343 BMS_a081_fourthBlockingAlertId "High-voltage battery management system: a081 fourth blocking alert id; raw 127 = signal not available (SNA)";
CM_ SG_ 1343 BMS_a081_totalAlertCount "High-voltage battery management system: a081 total alert count";
CM_ SG_ 1343 BMS_a082_stateRequest "High-voltage battery management system: a082 state request; raw 9 = signal not available (SNA)";
CM_ SG_ 1343 BMS_a082_firstAlertId "High-voltage battery management system: a082 first alert id; raw 127 = signal not available (SNA)";
CM_ SG_ 1343 BMS_a082_secondAlertId "High-voltage battery management system: a082 second alert id; raw 127 = signal not available (SNA)";
CM_ SG_ 1343 BMS_a082_thirdAlertId "High-voltage battery management system: a082 third alert id; raw 127 = signal not available (SNA)";
CM_ SG_ 1343 BMS_a082_fourthAlertId "High-voltage battery management system: a082 fourth alert id; raw 127 = signal not available (SNA)";
CM_ SG_ 1343 BMS_a082_totalAlertCount "High-voltage battery management system: a082 total alert count";
CM_ SG_ 1343 BMS_a083_packContactorRequest "High-voltage battery management system: a083 pack contactor request; raw 0 = signal not available (SNA)";
CM_ SG_ 1343 BMS_a085_packContactorSetStatePr "High-voltage battery management system: a085 pack contactor set state prev; raw 0 = signal not available (SNA)";
CM_ SG_ 1343 BMS_a085_packContactorSetState "High-voltage battery management system: a085 pack contactor set state; raw 0 = signal not available (SNA)";
CM_ SG_ 1343 BMS_a085_packContactorSetRe_0001 "High-voltage battery management system: a085 pack contactor set request prev; raw 0 = signal not available (SNA)";
CM_ SG_ 1343 BMS_a085_packContactorSetRequest "High-voltage battery management system: a085 pack contactor set request; raw 0 = signal not available (SNA)";
CM_ SG_ 1343 BMS_a086_fcContactorSetStatePrev "High-voltage battery management system: a086 fc contactor set state prev; raw 0 = signal not available (SNA)";
CM_ SG_ 1343 BMS_a086_fcContactorSetState "High-voltage battery management system: a086 fc contactor set state; raw 0 = signal not available (SNA)";
CM_ SG_ 1343 BMS_a086_fcContactorSetRequestPr "High-voltage battery management system: a086 fc contactor set request prev; raw 0 = signal not available (SNA)";
CM_ SG_ 1343 BMS_a086_fcContactorSetRequest "High-voltage battery management system: a086 fc contactor set request; raw 0 = signal not available (SNA)";
CM_ SG_ 1343 BMS_a087_blockingAlert "High-voltage battery management system: a087 blocking alert; raw 127 = signal not available (SNA)";
CM_ SG_ 1343 BMS_a090_GTWmessageTout "High-voltage battery management system: a090 GT wmessage tout";
CM_ SG_ 1343 BMS_a097_missingFrame "High-voltage battery management system: a097 missing frame";
CM_ SG_ 1343 BMS_a097_timeout "High-voltage battery management system: a097 timeout";
CM_ SG_ 1343 BMS_a098_breakLocationA "High-voltage battery management system: a098 break location a";
CM_ SG_ 1343 BMS_a098_bmbCommStatusTypeA "High-voltage battery management system: a098 bmb comm status type a";
CM_ SG_ 1343 BMS_a098_breakLocationB "High-voltage battery management system: a098 break location b";
CM_ SG_ 1343 BMS_a098_bmbCommStatusTypeB "High-voltage battery management system: a098 bmb comm status type b";
CM_ SG_ 1343 BMS_a098_alertFromHvp "High-voltage battery management system: a098 alert from hvp";
CM_ SG_ 1343 BMS_a099_breakLocationA "High-voltage battery management system: a099 break location a";
CM_ SG_ 1343 BMS_a099_bmbCommStatusTypeA "High-voltage battery management system: a099 bmb comm status type a";
CM_ SG_ 1343 BMS_a099_breakLocationB "High-voltage battery management system: a099 break location b";
CM_ SG_ 1343 BMS_a099_bmbCommStatusTypeB "High-voltage battery management system: a099 bmb comm status type b";
CM_ SG_ 1343 BMS_a099_bmbChainBreakType "High-voltage battery management system: a099 bmb chain break type";
CM_ SG_ 1343 BMS_a099_alertFromHvp "High-voltage battery management system: a099 alert from hvp";
CM_ SG_ 1343 BMS_a100_testTrigger "High-voltage battery management system: a100 test trigger";
CM_ SG_ 1343 BMS_a100_setFromNvm "High-voltage battery management system: a100 set from nvm";
CM_ SG_ 1343 BMS_a100_voltageDeviation "High-voltage battery management system: a100 voltage deviation";
CM_ SG_ 1343 BMS_a100_voltageLoss "High-voltage battery management system: a100 voltage loss";
CM_ SG_ 1343 BMS_a105_tSenseFailedModule1 "High-voltage battery management system: a105 t sense failed module1";
CM_ SG_ 1343 BMS_a105_avgBrickTModule1 "High-voltage battery management system: a105 avg brick t module1";
CM_ SG_ 1343 BMS_a105_tSenseFailedModule2 "High-voltage battery management system: a105 t sense failed module2";
CM_ SG_ 1343 BMS_a105_avgBrickTModule2 "High-voltage battery management system: a105 avg brick t module2";
CM_ SG_ 1343 BMS_a105_tSenseFailedModule3 "High-voltage battery management system: a105 t sense failed module3";
CM_ SG_ 1343 BMS_a105_avgBrickTModule3 "High-voltage battery management system: a105 avg brick t module3";
CM_ SG_ 1343 BMS_a105_tSenseFailedModule4 "High-voltage battery management system: a105 t sense failed module4";
CM_ SG_ 1343 BMS_a105_avgBrickTModule4 "High-voltage battery management system: a105 avg brick t module4";
CM_ SG_ 1343 BMS_a105_inletTemp "High-voltage battery management system: a105 inlet temp";
CM_ SG_ 1343 BMS_a106_minBrickT "High-voltage battery management system: a106 min brick t";
CM_ SG_ 1343 BMS_a106_maxBrickT "High-voltage battery management system: a106 max brick t";
CM_ SG_ 1343 BMS_a106_avgBrickT "High-voltage battery management system: a106 avg brick t";
CM_ SG_ 1343 BMS_a106_inletTemp "High-voltage battery management system: a106 inlet temp";
CM_ SG_ 1343 BMS_a107_MIA_numBadReadings "High-voltage battery management system: a107 MIA num bad readings";
CM_ SG_ 1343 BMS_a107_MIA_numSnaReadings "High-voltage battery management system: a107 MIA num sna readings";
CM_ SG_ 1343 BMS_a109_muteMask "High-voltage battery management system: a109 mute mask";
CM_ SG_ 1343 BMS_a109_packInBleed "High-voltage battery management system: a109 pack in bleed";
CM_ SG_ 1343 BMS_a117_brickID "High-voltage battery management system: a117 brick ID";
CM_ SG_ 1343 BMS_a117_brickSoc2 "High-voltage battery management system: a117 brick soc2; raw 1023 = signal not available (SNA)";
CM_ SG_ 1343 BMS_a117_dSocAlertThreshold "High-voltage battery management system: a117 d soc alert threshold";
CM_ SG_ 1343 BMS_a117_dSocAlpha "High-voltage battery management system: a117 d soc alpha; raw 4095 = signal not available (SNA)";
CM_ SG_ 1343 BMS_a122_thermistorID "High-voltage battery management system: a122 thermistor ID";
CM_ SG_ 1343 BMS_a122_irrationalThermistorTem "High-voltage battery management system: a122 irrational thermistor temp";
CM_ SG_ 1343 BMS_a122_averageRawThermistorTem "High-voltage battery management system: a122 average raw thermistor temp";
CM_ SG_ 1343 BMS_a122_minRawThermistorTemp "High-voltage battery management system: a122 min raw thermistor temp";
CM_ SG_ 1343 BMS_a122_maxRawThermistorTemp "High-voltage battery management system: a122 max raw thermistor temp";
CM_ SG_ 1343 BMS_a122_numValidThermistors "High-voltage battery management system: a122 num valid thermistors";
CM_ SG_ 1343 BMS_a123_packPlus "High-voltage battery management system: a123 pack plus";
CM_ SG_ 1343 BMS_a123_isoR "High-voltage battery management system: a123 iso r";
CM_ SG_ 1343 BMS_a123_packMinus "High-voltage battery management system: a123 pack minus";
CM_ SG_ 1343 BMS_a129_brickID "High-voltage battery management system: a129 brick ID";
CM_ SG_ 1343 BMS_a129_deltaV "High-voltage battery management system: a129 delta v";
CM_ SG_ 1343 BMS_a129_retryCount "High-voltage battery management system: a129 retry count";
CM_ SG_ 1343 BMS_a131_brickID "High-voltage battery management system: a131 brick ID";
CM_ SG_ 1343 BMS_a131_deltaV "High-voltage battery management system: a131 delta v";
CM_ SG_ 1343 BMS_a131_retryCount "High-voltage battery management system: a131 retry count";
CM_ SG_ 1343 BMS_a132_multiVendorErrorMask "High-voltage battery management system: a132 multi vendor error mask";
CM_ SG_ 1343 BMS_a135_bmbDiagnosticsType "High-voltage battery management system: a135 bmb diagnostics type";
CM_ SG_ 1343 BMS_a135_bmbDeviceId "High-voltage battery management system: a135 bmb device id";
CM_ SG_ 1343 BMS_a135_readCVA "High-voltage battery management system: a135 read CVA";
CM_ SG_ 1343 BMS_a135_readCVB "High-voltage battery management system: a135 read CVB";
CM_ SG_ 1343 BMS_a135_readCVC "High-voltage battery management system: a135 read CVC";
CM_ SG_ 1343 BMS_a135_readCVD "High-voltage battery management system: a135 read CVD";
CM_ SG_ 1343 BMS_a135_readCVE "High-voltage battery management system: a135 read CVE";
CM_ SG_ 1343 BMS_a135_readCVF "High-voltage battery management system: a135 read CVF";
CM_ SG_ 1343 BMS_a135_readSNA "High-voltage battery management system: a135 read SNA";
CM_ SG_ 1343 BMS_a135_readSNB "High-voltage battery management system: a135 read SNB";
CM_ SG_ 1343 BMS_a135_readSNC "High-voltage battery management system: a135 read SNC";
CM_ SG_ 1343 BMS_a135_readSND "High-voltage battery management system: a135 read SND";
CM_ SG_ 1343 BMS_a135_readSNE "High-voltage battery management system: a135 read SNE";
CM_ SG_ 1343 BMS_a135_readSNF "High-voltage battery management system: a135 read SNF";
CM_ SG_ 1343 BMS_a135_readAUXA "High-voltage battery management system: a135 read AUXA";
CM_ SG_ 1343 BMS_a135_readAUXB "High-voltage battery management system: a135 read AUXB";
CM_ SG_ 1343 BMS_a135_readSTAT "High-voltage battery management system: a135 read STAT";
CM_ SG_ 1343 BMS_a136_maxBrickTID "High-voltage battery management system: a136 max brick TID";
CM_ SG_ 1343 BMS_a136_coolantInletT "High-voltage battery management system: a136 coolant inlet t";
CM_ SG_ 1343 BMS_a136_activeCoolingTarget "High-voltage battery management system: a136 active cooling target";
CM_ SG_ 1343 BMS_a136_maxBrickT "High-voltage battery management system: a136 max brick t";
CM_ SG_ 1343 BMS_a139_packVoltage "High-voltage battery management system: a139 pack voltage";
CM_ SG_ 1343 BMS_a139_dcLinkVoltage "High-voltage battery management system: a139 dc link voltage";
CM_ SG_ 1343 BMS_a140_bmbDeviceMask "High-voltage battery management system: a140 bmb device mask";
CM_ SG_ 1343 BMS_a140_faultType "High-voltage battery management system: a140 fault type";
CM_ SG_ 1343 BMS_a142_isolationResistance "High-voltage battery management system: a142 isolation resistance";
CM_ SG_ 1343 BMS_a142_mode "High-voltage battery management system: a142 mode";
CM_ SG_ 1343 BMS_a143_initialSoc "High-voltage battery management system: a143 initial soc";
CM_ SG_ 1343 BMS_a143_endingSoc "High-voltage battery management system: a143 ending soc";
CM_ SG_ 1343 BMS_a143_deltaAh "High-voltage battery management system: a143 delta ah";
CM_ SG_ 1343 BMS_a143_cacChangeBrickID "High-voltage battery management system: a143 cac change brick ID";
CM_ SG_ 1343 BMS_a143_cacUpdateError "High-voltage battery management system: a143 cac update error";
CM_ SG_ 1343 BMS_a144_HVP_major_version "High-voltage battery management system: a144 HVP major version";
CM_ SG_ 1343 BMS_a144_HVP_minor_version "High-voltage battery management system: a144 HVP minor version";
CM_ SG_ 1343 BMS_a144_BMS_minor_version "High-voltage battery management system: a144 BMS minor version";
CM_ SG_ 1343 BMS_a145_maxSocChange "High-voltage battery management system: a145 max soc change";
CM_ SG_ 1343 BMS_a145_maxSocChangeBrickID "High-voltage battery management system: a145 max soc change brick ID";
CM_ SG_ 1343 BMS_a145_numBricksChanged "High-voltage battery management system: a145 num bricks changed";
CM_ SG_ 1343 BMS_a145_brickChangeHystRatio "High-voltage battery management system: a145 brick change hyst ratio; raw 1023 = signal not available (SNA)";
CM_ SG_ 1343 BMS_a146_maxBrickV "High-voltage battery management system: a146 max brick v";
CM_ SG_ 1343 BMS_a146_state "High-voltage battery management system: a146 state; raw 9 = signal not available (SNA)";
CM_ SG_ 1343 BMS_a146_packCurrent "High-voltage battery management system: a146 pack current";
CM_ SG_ 1343 BMS_a146_uvBrickVID "High-voltage battery management system: a146 uv brick VID";
CM_ SG_ 1343 BMS_a146_uvBrickV "High-voltage battery management system: a146 uv brick v";
CM_ SG_ 1343 BMS_a151_isoPositiveR "High-voltage battery management system: a151 iso positive r";
CM_ SG_ 1343 BMS_a151_isoNegativeR "High-voltage battery management system: a151 iso negative r";
CM_ SG_ 1343 BMS_a152_isoR "High-voltage battery management system: a152 iso r";
CM_ SG_ 1343 BMS_a152_mode "High-voltage battery management system: a152 mode";
CM_ SG_ 1343 BMS_a152_activeSideVNoR "High-voltage battery management system: a152 active side v no r";
CM_ SG_ 1343 BMS_a152_activeSideVWithR "High-voltage battery management system: a152 active side v with r";
CM_ SG_ 1343 BMS_a152_passiveSideVNoR "High-voltage battery management system: a152 passive side v no r";
CM_ SG_ 1343 BMS_a152_passiveSideVWithR "High-voltage battery management system: a152 passive side v with r";
CM_ SG_ 1343 BMS_a156_VrefSample "High-voltage battery management system: a156 vref sample";
CM_ SG_ 1343 BMS_a156_bmbDeviceId "High-voltage battery management system: a156 bmb device id";
CM_ SG_ 1343 BMS_a156_VrefStatus "High-voltage battery management system: a156 vref status";
CM_ SG_ 1343 BMS_a158_shuntCurrentMia "High-voltage battery management system: a158 shunt current mia";
CM_ SG_ 1343 BMS_a158_contactorStateMia "High-voltage battery management system: a158 contactor state mia";
CM_ SG_ 1343 BMS_a158_hvpFaultsMia "High-voltage battery management system: a158 hvp faults mia";
CM_ SG_ 1343 BMS_a162_dischargePower_W "High-voltage battery management system: a162 discharge power w";
CM_ SG_ 1343 BMS_a162_minSoc "High-voltage battery management system: a162 min soc";
CM_ SG_ 1343 BMS_a162_socThreshold "High-voltage battery management system: a162 soc threshold";
CM_ SG_ 1343 BMS_a164_regenPower "High-voltage battery management system: a164 regen power";
CM_ SG_ 1343 BMS_a165_packPositiveV "High-voltage battery management system: a165 pack positive v";
CM_ SG_ 1343 BMS_a165_packNegativeV "High-voltage battery management system: a165 pack negative v";
CM_ SG_ 1343 BMS_a165_dcLinkPositiveV "High-voltage battery management system: a165 dc link positive v";
CM_ SG_ 1343 BMS_a165_dcLinkNegativeV "High-voltage battery management system: a165 dc link negative v";
CM_ SG_ 1343 BMS_a166_packPositiveV "High-voltage battery management system: a166 pack positive v";
CM_ SG_ 1343 BMS_a166_packNegativeV "High-voltage battery management system: a166 pack negative v";
CM_ SG_ 1343 BMS_a166_dcLinkPositiveV "High-voltage battery management system: a166 dc link positive v";
CM_ SG_ 1343 BMS_a166_dcLinkNegativeV "High-voltage battery management system: a166 dc link negative v";
CM_ SG_ 1343 BMS_a167_fcContPositiveAuxOpen "High-voltage battery management system: a167 fc cont positive aux open";
CM_ SG_ 1343 BMS_a167_fcContNegativeAuxOpen "High-voltage battery management system: a167 fc cont negative aux open";
CM_ SG_ 1343 BMS_a167_dcLinkPositiveV "High-voltage battery management system: a167 dc link positive v";
CM_ SG_ 1343 BMS_a167_dcLinkNegativeV "High-voltage battery management system: a167 dc link negative v";
CM_ SG_ 1343 BMS_a167_fcLinkPositiveV "High-voltage battery management system: a167 fc link positive v";
CM_ SG_ 1343 BMS_a167_fcLinkNegativeV "High-voltage battery management system: a167 fc link negative v";
CM_ SG_ 1343 BMS_a168_fcContPositiveAuxOpen "High-voltage battery management system: a168 fc cont positive aux open";
CM_ SG_ 1343 BMS_a168_fcContNegativeAuxOpen "High-voltage battery management system: a168 fc cont negative aux open";
CM_ SG_ 1343 BMS_a168_dcLinkPositiveV "High-voltage battery management system: a168 dc link positive v";
CM_ SG_ 1343 BMS_a168_dcLinkNegativeV "High-voltage battery management system: a168 dc link negative v";
CM_ SG_ 1343 BMS_a168_fcLinkPositiveV "High-voltage battery management system: a168 fc link positive v";
CM_ SG_ 1343 BMS_a168_fcLinkNegativeV "High-voltage battery management system: a168 fc link negative v";
CM_ SG_ 1343 BMS_a169_DCAndFCContactorsWelded "High-voltage battery management system: a169 DC and FC contactors welded";
CM_ SG_ 1343 BMS_a170_limpModeActive "High-voltage battery management system: a170 limp mode active";
CM_ SG_ 1343 BMS_a171_stackVoltage "High-voltage battery management system: a171 stack voltage";
CM_ SG_ 1343 BMS_a171_sumBrickVoltage "High-voltage battery management system: a171 sum brick voltage";
CM_ SG_ 1343 BMS_a171_stackId "High-voltage battery management system: a171 stack id";
CM_ SG_ 1343 BMS_a172_swIsolationCount "High-voltage battery management system: a172 sw isolation count";
CM_ SG_ 1343 BMS_a172_swIsoDegradationCount "High-voltage battery management system: a172 sw iso degradation count";
CM_ SG_ 1343 BMS_a177_energyAlertThreshold "High-voltage battery management system: a177 energy alert threshold";
CM_ SG_ 1343 BMS_a177_energyBuffer "High-voltage battery management system: a177 energy buffer";
CM_ SG_ 1343 BMS_a178_diPower "High-voltage battery management system: a178 di power";
CM_ SG_ 1343 BMS_a178_energyError "High-voltage battery management system: a178 energy error";
CM_ SG_ 1343 BMS_a178_powerError "High-voltage battery management system: a178 power error";
CM_ SG_ 1343 BMS_a178_minPowerError "High-voltage battery management system: a178 min power error";
CM_ SG_ 1343 BMS_a178_maxPowerError "High-voltage battery management system: a178 max power error";
CM_ SG_ 1343 BMS_a178_diMiaCount "High-voltage battery management system: a178 di mia count";
CM_ SG_ 1343 BMS_a178_diSnaCount "High-voltage battery management system: a178 di sna count";
CM_ BO_ 800 "High-voltage battery management system message: alert matrix";
CM_ SG_ 800 BMS_matrixIndex "High-voltage battery management system: matrix index";
CM_ SG_ 800 BMS_a001_Pack_Config_Mismatch "High-voltage battery management system: a001 pack config mismatch";
CM_ SG_ 800 BMS_a002_Pack_Performance_Config "High-voltage battery management system: a002 pack performance config mismatch";
CM_ SG_ 800 BMS_a003_SW_Pack_Birth_Date_Miss "High-voltage battery management system: a003 SW pack birth date missing";
CM_ SG_ 800 BMS_a004_Cal_Vs_Serial_Birth_Dat "High-voltage battery management system: a004 cal vs serial birth date mismatch";
CM_ SG_ 800 BMS_a007_SW_Slowed_Chg_Batt_Cold "High-voltage battery management system: a007 SW slowed chg batt cold";
CM_ SG_ 800 BMS_a016_Pack_Module_Id_Mismatch "High-voltage battery management system: a016 pack module id mismatch";
CM_ SG_ 800 BMS_a017_SW_Brick_OV "High-voltage battery management system: a017 SW brick OV";
CM_ SG_ 800 BMS_a018_SW_Brick_UV "High-voltage battery management system: a018 SW brick UV";
CM_ SG_ 800 BMS_a019_SW_Module_OT "High-voltage battery management system: a019 SW module OT";
CM_ SG_ 800 BMS_a020_SW_Brick_Instability "High-voltage battery management system: a020 SW brick instability";
CM_ SG_ 800 BMS_a021_SW_Dr_Limits_Regulation "High-voltage battery management system: a021 SW dr limits regulation";
CM_ SG_ 800 BMS_a022_SW_Over_Current "High-voltage battery management system: a022 SW over current";
CM_ SG_ 800 BMS_a023_SW_Stack_OV "High-voltage battery management system: a023 SW stack OV";
CM_ SG_ 800 BMS_a024_SW_Islanded_Brick "High-voltage battery management system: a024 SW islanded brick";
CM_ SG_ 800 BMS_a025_SW_PwrBalance_Anomaly "High-voltage battery management system: a025 SW pwr balance anomaly";
CM_ SG_ 800 BMS_a026_SW_HFCurrent_Anomaly "High-voltage battery management system: a026 SW HF current anomaly";
CM_ SG_ 800 BMS_a027_SW_Repeated_Isolation_F "High-voltage battery management system: a027 SW repeated isolation failure in drive";
CM_ SG_ 800 BMS_a028_ShuntAsicCurrentOffsetD "High-voltage battery management system: a028 shunt asic current offset deviation";
CM_ SG_ 800 BMS_a029_dSoc_Limiting "High-voltage battery management system: a029 d soc limiting";
CM_ SG_ 800 BMS_a030_Impedance_Deviation "High-voltage battery management system: a030 impedance deviation";
CM_ SG_ 800 BMS_a031_AlertsSetDuringSleep "High-voltage battery management system: a031 alerts set during sleep";
CM_ SG_ 800 BMS_a032_VoltageLoss "High-voltage battery management system: a032 voltage loss";
CM_ SG_ 800 BMS_a033_VoltageDeviation "High-voltage battery management system: a033 voltage deviation";
CM_ SG_ 800 BMS_a034_SW_Passive_Isolation "High-voltage battery management system: a034 SW passive isolation";
CM_ SG_ 800 BMS_a035_SW_Isolation "High-voltage battery management system: a035 SW isolation";
CM_ SG_ 800 BMS_a036_SW_HvpHvilFault "High-voltage battery management system: a036 SW hvp hvil fault";
CM_ SG_ 800 BMS_a037_SW_Flood_Port_Open "High-voltage battery management system: a037 SW flood port open";
CM_ SG_ 800 BMS_a039_SW_DC_Link_Over_Voltage "High-voltage battery management system: a039 SW DC link over voltage";
CM_ SG_ 800 BMS_a040_SW_Watch_Dog_HW_Trigger "High-voltage battery management system: a040 SW watch dog HW triggered";
CM_ SG_ 800 BMS_a041_SW_Destructive_Reset_So "High-voltage battery management system: a041 SW destructive reset source";
CM_ SG_ 800 BMS_a042_SW_MPU_Error "High-voltage battery management system: a042 SW MPU error";
CM_ SG_ 800 BMS_a043_SW_Watch_Dog_Reset "High-voltage battery management system: a043 SW watch dog reset";
CM_ SG_ 800 BMS_a044_SW_Assertion "High-voltage battery management system: a044 SW assertion";
CM_ SG_ 800 BMS_a045_SW_Exception "High-voltage battery management system: a045 SW exception";
CM_ SG_ 800 BMS_a046_SW_Task_Stack_Usage "High-voltage battery management system: a046 SW task stack usage";
CM_ SG_ 800 BMS_a047_SW_Task_Stack_Overflow "High-voltage battery management system: a047 SW task stack overflow";
CM_ SG_ 800 BMS_a048_SW_Watch_Dog_Warning "High-voltage battery management system: a048 SW watch dog warning";
CM_ SG_ 800 BMS_a049_SW_Thermal_Event "High-voltage battery management system: a049 SW thermal event";
CM_ SG_ 800 BMS_a050_SW_Brick_Voltage_MIA "High-voltage battery management system: a050 SW brick voltage MIA";
CM_ SG_ 800 BMS_a051_SW_HVC_Vref_Bad "High-voltage battery management system: a051 SW HVC vref bad";
CM_ SG_ 800 BMS_a052_SW_PCS_MIA "High-voltage battery management system: a052 SW PCS MIA";
CM_ SG_ 800 BMS_a054_SW_Ver_Supply_Fault "High-voltage battery management system: a054 SW ver supply fault";
CM_ SG_ 800 BMS_a055_SW_HvChain_Model_Fault "High-voltage battery management system: a055 SW hv chain model fault";
CM_ SG_ 800 BMS_a056_SW_Standby_Supply_Fault "High-voltage battery management system: a056 SW standby supply fault";
CM_ SG_ 800 BMS_a057_SW_Bandolier_Model_Warn "High-voltage battery management system: a057 SW bandolier model warning";
CM_ SG_ 800 BMS_a058_SW_Bandolier_Model_Rese "High-voltage battery management system: a058 SW bandolier model reset";
CM_ SG_ 800 BMS_a059_SW_Pack_Voltage_Sensing "High-voltage battery management system: a059 SW pack voltage sensing";
CM_ SG_ 800 BMS_a060_SW_Leakage_Test_Failure "High-voltage battery management system: a060 SW leakage test failure";
CM_ SG_ 800 BMS_a061_SW_BrickV_Change "High-voltage battery management system: a061 SW brick v change";
CM_ SG_ 800 BMS_a062_SW_BrickV_Imbalance "High-voltage battery management system: a062 SW brick v imbalance";
CM_ SG_ 800 BMS_a063_SW_ChargePort_Fault "High-voltage battery management system: a063 SW charge port fault";
CM_ SG_ 800 BMS_a064_SW_SOC_Imbalance "High-voltage battery management system: a064 SW SOC imbalance";
CM_ SG_ 800 BMS_a065_SW_CAC_Imbalance "High-voltage battery management system: a065 SW CAC imbalance";
CM_ SG_ 800 BMS_a066_SOC_Imbalance_Warning "High-voltage battery management system: a066 SOC imbalance warning";
CM_ SG_ 800 BMS_a067_CAC_Imbalance_Limiting "High-voltage battery management system: a067 CAC imbalance limiting";
CM_ SG_ 800 BMS_a068_CAC_Imbalance_Limp "High-voltage battery management system: a068 CAC imbalance limp";
CM_ SG_ 800 BMS_a069_SW_Low_Power "High-voltage battery management system: a069 SW low power";
CM_ SG_ 800 BMS_a070_BrickV_Imbalance_Limiti "High-voltage battery management system: a070 brick v imbalance limiting";
CM_ SG_ 800 BMS_a071_SW_SM_TransCon_Not_Met "High-voltage battery management system: a071 SW SM trans con not met";
CM_ SG_ 800 BMS_a072_Module_Brick_Split "High-voltage battery management system: a072 module brick split";
CM_ SG_ 800 BMS_a073_Unexpected_Loss_Of_Lv "High-voltage battery management system: a073 unexpected loss of lv";
CM_ SG_ 800 BMS_a074_Max_Charge_Level_Reduce "High-voltage battery management system: a074 max charge level reduced";
CM_ SG_ 800 BMS_a075_SW_Chg_Disable_Failure "High-voltage battery management system: a075 SW chg disable failure";
CM_ SG_ 800 BMS_a076_SW_Dch_While_Charging "High-voltage battery management system: a076 SW dch while charging";
CM_ SG_ 800 BMS_a077_SW_Charger_Regulation "High-voltage battery management system: a077 SW charger regulation";
CM_ SG_ 800 BMS_a078_Rapid_Dch_While_Chargin "High-voltage battery management system: a078 rapid dch while charging";
CM_ SG_ 800 BMS_a079_Max_Charge_Level_Exceed "High-voltage battery management system: a079 max charge level exceeded";
CM_ SG_ 800 BMS_a080_SW_Pack_Ctr_Impedance "High-voltage battery management system: a080 SW pack ctr impedance";
CM_ SG_ 800 BMS_a081_SW_Ctr_Close_Blocked "High-voltage battery management system: a081 SW ctr close blocked";
CM_ SG_ 800 BMS_a082_SW_Ctr_Force_Open "High-voltage battery management system: a082 SW ctr force open";
CM_ SG_ 800 BMS_a083_SW_Ctr_Close_Failure "High-voltage battery management system: a083 SW ctr close failure";
CM_ SG_ 800 BMS_a084_SW_Sleep_Wake_Aborted "High-voltage battery management system: a084 SW sleep wake aborted";
CM_ SG_ 800 BMS_a085_SW_Pack_Contactor_Misma "High-voltage battery management system: a085 SW pack contactor mismatch";
CM_ SG_ 800 BMS_a086_SW_FC_Contactor_Mismatc "High-voltage battery management system: a086 SW FC contactor mismatch";
CM_ SG_ 800 BMS_a087_SW_Feim_Test_Blocked "High-voltage battery management system: a087 SW feim test blocked";
CM_ SG_ 800 BMS_a088_SW_VcFront_MIA_InDrive "High-voltage battery management system: a088 SW vc front MIA in drive";
CM_ SG_ 800 BMS_a089_SW_VcFront_MIA "High-voltage battery management system: a089 SW vc front MIA";
CM_ SG_ 800 BMS_a090_SW_Gateway_MIA "High-voltage battery management system: a090 SW gateway MIA";
CM_ SG_ 800 BMS_a091_SW_ChargePort_MIA "High-voltage battery management system: a091 SW charge port MIA";
CM_ SG_ 800 BMS_a092_SW_ChargePort_Mia_On_Hv "High-voltage battery management system: a092 SW charge port mia on hvs";
CM_ SG_ 800 BMS_a094_SW_Drive_Inverter_MIA "High-voltage battery management system: a094 SW drive inverter MIA";
CM_ SG_ 800 BMS_a095_SW_UI_MIA "High-voltage battery management system: a095 SW UI MIA";
CM_ SG_ 800 BMS_a097_SW_BMB_Over_CAN_Communi "High-voltage battery management system: a097 SW BMB over CAN communication";
CM_ SG_ 800 BMS_a098_SW_BMB_Data_Integrity_L "High-voltage battery management system: a098 SW BMB data integrity loss";
CM_ SG_ 800 BMS_a099_SW_BMB_Communication "High-voltage battery management system: a099 SW BMB communication";
CM_ SG_ 800 BMS_a100_ThermalEventSuspected "High-voltage battery management system: a100 thermal event suspected";
CM_ SG_ 800 BMS_a105_SW_One_Module_Tsense "High-voltage battery management system: a105 SW one module tsense";
CM_ SG_ 800 BMS_a106_SW_All_Module_Tsense "High-voltage battery management system: a106 SW all module tsense";
CM_ SG_ 800 BMS_a107_SW_Stack_Voltage_MIA "High-voltage battery management system: a107 SW stack voltage MIA";
CM_ SG_ 800 BMS_a108_SW_BMB_Device_OT "High-voltage battery management system: a108 SW BMB device OT";
CM_ SG_ 800 BMS_a109_HW_BMB_Mute_Status_Mism "High-voltage battery management system: a109 HW BMB mute status mismatch";
CM_ SG_ 800 BMS_a110_LifeModel_AvgOffset_Cha "High-voltage battery management system: a110 life model avg offset change";
CM_ SG_ 800 BMS_a111_LifeModel_Spread_Change "High-voltage battery management system: a111 life model spread change";
CM_ SG_ 800 BMS_a112_LifeModel_Discontinuity "High-voltage battery management system: a112 life model discontinuity";
CM_ SG_ 800 BMS_a115_Energy_Rubberbanding_Re "High-voltage battery management system: a115 energy rubberbanding reset";
CM_ SG_ 800 BMS_a117_SW_Delta_SOC_Weak_Short "High-voltage battery management system: a117 SW delta SOC weak short";
CM_ SG_ 800 BMS_a119_Fast_Open_Vsh_Detected "High-voltage battery management system: a119 fast open vsh detected";
CM_ SG_ 800 BMS_a121_SW_NVRAM_Config_Error "High-voltage battery management system: a121 SW NVRAM config error";
CM_ SG_ 800 BMS_a122_SW_BMS_Therm_Irrational "High-voltage battery management system: a122 SW BMS therm irrational";
CM_ SG_ 800 BMS_a123_SW_Internal_Isolation "High-voltage battery management system: a123 SW internal isolation";
CM_ SG_ 800 BMS_a124_Battery_Coolant_Flood "High-voltage battery management system: a124 battery coolant flood";
CM_ SG_ 800 BMS_a126_SW_Thermistor_Failure "High-voltage battery management system: a126 SW thermistor failure";
CM_ SG_ 800 BMS_a127_SW_shunt_SNA "High-voltage battery management system: a127 SW shunt SNA";
CM_ SG_ 800 BMS_a128_SW_shunt_MIA "High-voltage battery management system: a128 SW shunt MIA";
CM_ SG_ 800 BMS_a129_SW_VSH_Failure "High-voltage battery management system: a129 SW VSH failure";
CM_ SG_ 800 BMS_a130_IO_CAN_Error "High-voltage battery management system: a130 IO CAN error";
CM_ SG_ 800 BMS_a131_Bleed_FET_Failure "High-voltage battery management system: a131 bleed FET failure";
CM_ SG_ 800 BMS_a132_HW_BMB_OTP_Uncorrctbl "High-voltage battery management system: a132 HW BMB OTP uncorrctbl";
CM_ SG_ 800 BMS_a133_IO_CAN_Bus_Off "High-voltage battery management system: a133 IO CAN bus off";
CM_ SG_ 800 BMS_a134_SW_Delayed_Ctr_Off "High-voltage battery management system: a134 SW delayed ctr off";
CM_ SG_ 800 BMS_a135_HW_BMB_Diagnostics_Fail "High-voltage battery management system: a135 HW BMB diagnostics failure";
CM_ SG_ 800 BMS_a136_SW_Module_OT_Warning "High-voltage battery management system: a136 SW module OT warning";
CM_ SG_ 800 BMS_a137_SW_Brick_UV_Warning "High-voltage battery management system: a137 SW brick UV warning";
CM_ SG_ 800 BMS_a138_SW_Brick_OV_Warning "High-voltage battery management system: a138 SW brick OV warning";
CM_ SG_ 800 BMS_a139_SW_DC_Link_V_Irrational "High-voltage battery management system: a139 SW DC link v irrational";
CM_ SG_ 800 BMS_a140_HW_BMB_Status_Fault "High-voltage battery management system: a140 HW BMB status fault";
CM_ SG_ 800 BMS_a141_SW_BMB_Status_Warning "High-voltage battery management system: a141 SW BMB status warning";
CM_ SG_ 800 BMS_a142_SW_Isolation_Degradatio "High-voltage battery management system: a142 SW isolation degradation";
CM_ SG_ 800 BMS_a143_SW_CAC_Change "High-voltage battery management system: a143 SW CAC change";
CM_ SG_ 800 BMS_a144_Hvp_Config_Mismatch "High-voltage battery management system: a144 hvp config mismatch";
CM_ SG_ 800 BMS_a145_SW_SOC_Change "High-voltage battery management system: a145 SW SOC change";
CM_ SG_ 800 BMS_a146_SW_Brick_Overdischarged "High-voltage battery management system: a146 SW brick overdischarged";
CM_ SG_ 800 BMS_a147_SW_SOC_High_Ah_Error "High-voltage battery management system: a147 SW SOC high ah error";
CM_ SG_ 800 BMS_a148_SW_Unsupported_BMB_ASIC "High-voltage battery management system: a148 SW unsupported BMB ASIC type";
CM_ SG_ 800 BMS_a149_SW_Missing_Config_Block "High-voltage battery management system: a149 SW missing config block";
CM_ SG_ 800 BMS_a150_SW_Missing_Part_Number "High-voltage battery management system: a150 SW missing part number";
CM_ SG_ 800 BMS_a151_SW_external_isolation "High-voltage battery management system: a151 SW external isolation";
CM_ SG_ 800 BMS_a152_Isolation_In_Dc_Charge "High-voltage battery management system: a152 isolation in dc charge";
CM_ SG_ 800 BMS_a154_SW_Brick_OV_Warning_Sto "High-voltage battery management system: a154 SW brick OV warning stop charge";
CM_ SG_ 800 BMS_a155_SW_Weak_short_impedence "High-voltage battery management system: a155 SW weak short impedence";
CM_ SG_ 800 BMS_a156_SW_BMB_Vref_bad "High-voltage battery management system: a156 SW BMB vref bad";
CM_ SG_ 800 BMS_a157_SW_Hist_Update_Missed "High-voltage battery management system: a157 SW hist update missed";
CM_ SG_ 800 BMS_a158_SW_HVP_HVI_Comms "High-voltage battery management system: a158 SW HVP HVI comms";
CM_ SG_ 800 BMS_a159_SW_HVP_ECU_Error "High-voltage battery management system: a159 SW HVP ECU error";
CM_ SG_ 800 BMS_a160_SW_FC_Ctr_Clean_Failed "High-voltage battery management system: a160 SW FC ctr clean failed";
CM_ SG_ 800 BMS_a161_SW_BMB_Vref_warning "High-voltage battery management system: a161 SW BMB vref warning";
CM_ SG_ 800 BMS_a162_SW_No_Power_For_Support "High-voltage battery management system: a162 SW no power for support";
CM_ SG_ 800 BMS_a164_SW_Uncontrolled_Regen "High-voltage battery management system: a164 SW uncontrolled regen";
CM_ SG_ 800 BMS_a165_SW_Pack_Partial_Weld "High-voltage battery management system: a165 SW pack partial weld";
CM_ SG_ 800 BMS_a166_SW_Pack_Full_Weld "High-voltage battery management system: a166 SW pack full weld";
CM_ SG_ 800 BMS_a167_SW_FC_Partial_Weld "High-voltage battery management system: a167 SW FC partial weld";
CM_ SG_ 800 BMS_a168_SW_FC_Full_Weld "High-voltage battery management system: a168 SW FC full weld";
CM_ SG_ 800 BMS_a169_SW_FC_Pack_Weld "High-voltage battery management system: a169 SW FC pack weld";
CM_ SG_ 800 BMS_a170_SW_Limp_Mode "High-voltage battery management system: a170 SW limp mode";
CM_ SG_ 800 BMS_a171_SW_Stack_Voltage_Sense "High-voltage battery management system: a171 SW stack voltage sense";
CM_ SG_ 800 BMS_a172_SW_Isolation_Failure_In "High-voltage battery management system: a172 SW isolation failure in drive warning";
CM_ SG_ 800 BMS_a174_SW_Charge_Failure "High-voltage battery management system: a174 SW charge failure";
CM_ SG_ 800 BMS_a175_Charge_Failure_External "High-voltage battery management system: a175 charge failure external";
CM_ SG_ 800 BMS_a176_SW_GracefulPowerOff "High-voltage battery management system: a176 SW graceful power off";
CM_ SG_ 800 BMS_a177_SW_Energy_Buffer_Size "High-voltage battery management system: a177 SW energy buffer size";
CM_ SG_ 800 BMS_a178_SW_Uncontrolled_Regen_P "High-voltage battery management system: a178 SW uncontrolled regen pwr b";
CM_ SG_ 800 BMS_a179_HvpGpoRequestActive "High-voltage battery management system: a179 hvp gpo request active";
CM_ SG_ 800 BMS_a180_SW_ECU_reset_blocked "High-voltage battery management system: a180 SW ECU reset blocked";
CM_ SG_ 800 BMS_a181_SW_Shunt_Over_Temperatu "High-voltage battery management system: a181 SW shunt over temperature";
CM_ SG_ 800 BMS_a182_LifeModel_NoCurrentLoss "High-voltage battery management system: a182 life model no current loss change";
CM_ SG_ 800 BMS_a183_LifeModel_StoDcrGrowth_ "High-voltage battery management system: a183 life model sto dcr growth change";
CM_ SG_ 800 BMS_a184_LifeModel_CyclingLoss_C "High-voltage battery management system: a184 life model cycling loss change";
CM_ SG_ 800 BMS_a185_LifeModel_CyclingDcrGro "High-voltage battery management system: a185 life model cycling dcr growth change";
CM_ SG_ 800 BMS_a186_RippleHeatingChargeFaul "High-voltage battery management system: a186 ripple heating charge fault";
CM_ SG_ 800 BMS_a187_RippleHeatingEmergencyS "High-voltage battery management system: a187 ripple heating emergency shutdown";
CM_ SG_ 800 BMS_a188_DtcConfirmed "High-voltage battery management system: a188 dtc confirmed";
CM_ BO_ 818 "High-voltage battery management system message: bmb min max";
CM_ SG_ 818 BMS_bmbMinMaxMultiplexer "High-voltage battery management system: bmb min max multiplexer";
CM_ SG_ 818 BMS_thermistorNumTMin "BMB module number with minimum temperature.";
CM_ SG_ 818 BMS_thermistorNumTMax "BMB module number with maximum temperature.";
CM_ SG_ 818 BMS_thermistorTMax "Max temperature of all valid filtered thermistors";
CM_ SG_ 818 BMS_thermistorTMin "Min temperature of all valid filtered thermistors";
CM_ SG_ 818 BMS_thermistorTAvg "Average temperature of all valid filtered thermistors";
CM_ SG_ 818 BMS_brickVoltageMax "Brick voltage maximum.";
CM_ SG_ 818 BMS_brickVoltageMin "Brick voltage minimum.";
CM_ SG_ 818 BMS_brickNumVoltageMax "Brick number with maximum voltage (1 indexed)";
CM_ SG_ 818 BMS_brickNumVoltageMin "Brick number with minimum voltage (1 indexed)";
CM_ BO_ 1138 "High-voltage battery management system message: charge info";
CM_ SG_ 1138 BMS_cellChargeDcCurrentLimit "DC current target based on cell voltage & temp tables";
CM_ SG_ 1138 BMS_voltageRegCurrentTarget "DC current target based on voltage regulator";
CM_ SG_ 1138 BMS_vehicleChargeDcCurrentLimit "Charge current target after all aggregating all vehicle-side limits, exclude EVSE limits";
CM_ SG_ 1138 BMS_chargeCurrentLimitMode "BMS charging current limiting factor";
CM_ SG_ 1138 BMS_timeToFinishHeatForCharge "High-voltage battery management system: time to finish heat for charge; raw 127 = signal not available (SNA)";
CM_ SG_ 1138 BMS_diNodeModelTemp "High-voltage battery management system: di node model temp; raw 2047 = signal not available (SNA)";
CM_ BO_ 562 "High-voltage battery management system message: contactor request";
CM_ SG_ 562 BMS_internalHvilSenseV "High-voltage battery management system: internal hvil sense v";
CM_ SG_ 562 BMS_hvilCoverVSense "High-voltage battery management system: hvil cover v sense";
CM_ BO_ 2029 "High-voltage battery management system message: debug info 10 hz";
CM_ SG_ 2029 BMS_10HzDebug_Id "High-voltage battery management system: 10 hz debug id";
CM_ SG_ 2029 BMS_activeCoolCellTargetT "High-voltage battery management system: active cool cell target t";
CM_ SG_ 2029 BMS_passiveCoolCellTargetT "High-voltage battery management system: passive cool cell target t";
CM_ BO_ 722 "High-voltage battery management system message: drive limits";
CM_ SG_ 722 BMS_minBusVoltage "Calculated min bus voltage limit";
CM_ SG_ 722 BMS_maxBusVoltage "Calculated max bus voltage limit for the pack";
CM_ SG_ 722 BMS_maxChargeCurrent "Calculated max charge current limit for the pack";
CM_ SG_ 722 BMS_maxDischargeCurrent "Calculated max discharge current limit for the pack";
CM_ BO_ 690 "High-voltage battery management system message: energy status";
CM_ SG_ 690 BMS_energyStatusMultiplexer "High-voltage battery management system: energy status multiplexer";
CM_ SG_ 690 BMS_nominalFullPackEnergy "Full pack energy based on calculated pack energy from the full pack discharge energy walk; raw 65535 = signal not available (SNA)";
CM_ SG_ 690 BMS_nominalEnergyRemaining "Nominal energy remaining based on calculated pack energy from the nominal discharge energy walk; raw 65535 = signal not available (SNA)";
CM_ SG_ 690 BMS_idealEnergyRemaining "Ideal energy remaining based on calculated pack energy from ideal discharge energy walk; raw 65535 = signal not available (SNA)";
CM_ SG_ 690 BMS_fullChargeComplete "Indicates BMS is fully charged";
CM_ SG_ 690 BMS_energyBuffer "Rough indication of confidence in the energy estimation; raw 65535 = signal not available (SNA)";
CM_ SG_ 690 BMS_expectedEnergyRemaining "High-voltage battery management system: expected energy remaining; raw 65535 = signal not available (SNA)";
CM_ SG_ 690 BMS_energyToChargeComplete "Calculated energy required to reach charge complete; raw 65535 = signal not available (SNA)";
CM_ SG_ 690 BMS_energyRemainingDisplay "Rubber-banding energy remaining to be used for the UI facing miles remaining display; raw 65535 = signal not available (SNA)";
CM_ SG_ 690 BMS_energyRemainingTDisplay "Rubber-banding energy remaining to be used for the UI facing miles remaining display; raw 65535 = signal not available (SNA)";
CM_ SG_ 690 BMS_energyDisplayErrorBlendRate "Rubber-banding blend rate to be used to ensure consistency between the gauge display and UI energy algorithms";
CM_ SG_ 690 BMS_userFacingSoe "User facing state of energy; raw 2047 = signal not available (SNA)";
CM_ BO_ 306 "High-voltage battery management system message: hv bus status";
CM_ SG_ 306 BMS_packVoltage "Measures voltage on the battery side of the High Voltage (HV) contactors.";
CM_ SG_ 306 BMS_packCurrent "Current measured at the HV contactors of the HV battery; raw 32768 = signal not available (SNA)";
CM_ SG_ 306 BMS_currentUnfiltered "Pack current with no filters applied; raw 32768 = signal not available (SNA)";
CM_ SG_ 306 BMS_chgTimeToFull "Estimated time remaining until charge termination percent will be reached; raw 4095 = signal not available (SNA)";
CM_ BO_ 768 "High-voltage battery management system message: info";
CM_ SG_ 768 BMS_infoIndex "High-voltage battery management system: info index";
CM_ SG_ 768 BMS_buildType "High-voltage battery management system: build type";
CM_ SG_ 768 BMS_buildConfigId "High-voltage battery management system: build config id";
CM_ SG_ 768 BMS_hardwareId "High-voltage battery management system: hardware id";
CM_ SG_ 768 BMS_componentId "High-voltage battery management system: component id";
CM_ SG_ 768 BMS_pcbaId "BMS' assigned PCBA ID";
CM_ SG_ 768 BMS_assemblyId "BMS' assigned assembly ID";
CM_ SG_ 768 BMS_usageId "BMS' assigned usage ID";
CM_ SG_ 768 BMS_subUsageId "BMS' assigned subusage ID";
CM_ SG_ 768 BMS_platformType "High-voltage battery management system: platform type";
CM_ SG_ 768 BMS_appCrc "High-voltage battery management system: app crc";
CM_ SG_ 768 BMS_appGitHash "High-voltage battery management system: app git hash";
CM_ SG_ 768 BMS_bootGitHash "High-voltage battery management system: boot git hash";
CM_ SG_ 768 BMS_bootUdsProtoVersion "High-voltage battery management system: boot uds proto version";
CM_ SG_ 768 BMS_bootCrc "High-voltage battery management system: boot crc";
CM_ BO_ 978 "High-voltage battery management system message: kwh counter";
CM_ SG_ 978 BMS_kwhDischargeTotal "Total energy-lost kWh count during discharging";
CM_ SG_ 978 BMS_kwhChargeTotal "Total energy-gained kWh count during charging";
CM_ BO_ 1010 "High-voltage battery management system message: kwh counters multiplexed";
CM_ SG_ 1010 BMS_kwhCounter_Id "High-voltage battery management system: kwh counter id";
CM_ SG_ 1010 BMS_acChargerKwhTotal "Total energy-gained kWh count during AC charge";
CM_ SG_ 1010 BMS_dcChargerKwhTotal "Total energy-gained kWh count during DC charging";
CM_ SG_ 1010 BMS_kwhRegenChargeTotal "Total energy-gained kWh count during charging with regen";
CM_ SG_ 1010 BMS_kwhDriveDischargeTotal "Total energy-lost kWh count during discharging while driving";
CM_ SG_ 1010 BMS_kwhDischargeTotalModule1 "Total energy-lost kWh count during discharging for module number (1 indexed)";
CM_ SG_ 1010 BMS_kwhChargeTotalModule1 "Total energy-gained kWh count for module number (1 indexed)";
CM_ SG_ 1010 BMS_kwhAcChargeTotalModule1 "Total energy-gained kWh count during AC charge for module number (1 indexed)";
CM_ SG_ 1010 BMS_kwhDcChargeTotalModule1 "Total energy-gained kWh count during DC charge for module number (1 indexed)";
CM_ SG_ 1010 BMS_kwhDischargeTotalModule2 "Total energy-lost kWh count during discharging for module number (1 indexed)";
CM_ SG_ 1010 BMS_kwhChargeTotalModule2 "Total energy-gained kWh count for module number (1 indexed)";
CM_ SG_ 1010 BMS_kwhAcChargeTotalModule2 "Total energy-gained kWh count during AC charge for module number (1 indexed)";
CM_ SG_ 1010 BMS_kwhDcChargeTotalModule2 "Total energy-gained kWh count during DC charge for module number (1 indexed)";
CM_ SG_ 1010 BMS_kwhDischargeTotalModule3 "Total energy-lost kWh count during discharging for module number (1 indexed)";
CM_ SG_ 1010 BMS_kwhChargeTotalModule3 "Total energy-gained kWh count for module number (1 indexed)";
CM_ SG_ 1010 BMS_kwhAcChargeTotalModule3 "Total energy-gained kWh count during AC charge for module number (1 indexed)";
CM_ SG_ 1010 BMS_kwhDcChargeTotalModule3 "Total energy-gained kWh count during DC charge for module number (1 indexed)";
CM_ SG_ 1010 BMS_kwhDischargeTotalModule4 "Total energy-lost kWh count during discharging for module number (1 indexed)";
CM_ SG_ 1010 BMS_kwhChargeTotalModule4 "Total energy-gained kWh count for module number (1 indexed)";
CM_ SG_ 1010 BMS_kwhAcChargeTotalModule4 "Total energy-gained kWh count during AC charge for module number (1 indexed)";
CM_ SG_ 1010 BMS_kwhDcChargeTotalModule4 "Total energy-gained kWh count during DC charge for module number (1 indexed)";
CM_ BO_ 884 "High-voltage battery management system message: log1";
CM_ SG_ 884 BMS_log1MuxId "High-voltage battery management system: log1 mux id";
CM_ SG_ 884 BMS_hvChargeStatus "High-voltage battery management system: hv charge status";
CM_ SG_ 884 BMS_extDcPrechargeVoltageLimit "High-voltage battery management system: ext dc precharge voltage limit";
CM_ SG_ 884 BMS_dcChargeCurrentRequest "The BMS's instantaneous DC charge current request to the EVSE";
CM_ SG_ 884 BMS_dcChargeCurrentLimit "The vehicle's charge current limit on a DC EVSE's output";
CM_ SG_ 884 BMS_dcDischargeEnabled "High-voltage battery management system: dc discharge enabled";
CM_ SG_ 884 BMS_rippleChargeRetryCount "High-voltage battery management system: ripple charge retry count";
CM_ SG_ 884 BMS_dcChargeVoltageLimit "The vehicle's charge voltage limit on a DC EVSE's output";
CM_ SG_ 884 BMS_dcChargePowerLimit "Max power limit for pack during DC charging";
CM_ SG_ 884 BMS_acChargePowerRequest "High-voltage battery management system: ac charge power request";
CM_ SG_ 884 BMS_maxExtIsoFcLinkV "The max voltage read on the FC link during the external isolation check";
CM_ SG_ 884 BMS_minModeledPackTemp "High-voltage battery management system: min modeled pack temp";
CM_ SG_ 884 BMS_maxModeledPackTemp "High-voltage battery management system: max modeled pack temp";
CM_ SG_ 884 BMS_socByDeltaVEnabled "High-voltage battery management system: soc by delta v enabled";
CM_ SG_ 884 BMS_socByDvMaxSocLimit "High-voltage battery management system: soc by dv max soc limit";
CM_ SG_ 884 BMS_socByDvVoltageChangeOverAh "High-voltage battery management system: soc by dv voltage change over ah";
CM_ SG_ 884 BMS_socByDvMaxSocByAhCorrected "High-voltage battery management system: soc by dv max soc by ah corrected";
CM_ SG_ 884 BMS_socByDvMaxBrickVoltage "High-voltage battery management system: soc by dv max brick voltage";
CM_ SG_ 884 BMS_socByDvMaxBrickId "High-voltage battery management system: soc by dv max brick id";
BA_DEF_ BO_ "GenMsgCycleTime" INT 0 3600000;
BA_DEF_ BO_ "GenMsgSendType" ENUM "Cyclic","NotUsed","NotUsed","NotUsed","NotUsed","NotUsed","NotUsed","IfActive","NoMsgSendType","NotUsed";
BA_DEF_ BO_ "VFrameFormat" ENUM "StandardCAN","ExtendedCAN","reserved","J1939PG","reserved","reserved","reserved","reserved","reserved","reserved","reserved","reserved","reserved","reserved","StandardCAN_FD","ExtendedCAN_FD";
BA_DEF_ BO_ "CANFD_BRS" ENUM "0","1";
BA_DEF_ SG_ "GenSigSNA" STRING;
BA_DEF_ SG_ "SystemSignalLongSymbol" STRING;
BA_DEF_ SG_ "Confidence" ENUM "validated","plausible","layout-only","contradicted";
BA_DEF_DEF_ "GenMsgCycleTime" 0;
BA_DEF_DEF_ "GenMsgSendType" "NoMsgSendType";
BA_DEF_DEF_ "VFrameFormat" "StandardCAN";
BA_DEF_DEF_ "CANFD_BRS" "1";
BA_DEF_DEF_ "GenSigSNA" "";
BA_DEF_DEF_ "SystemSignalLongSymbol" "";
BA_DEF_DEF_ "Confidence" "layout-only";
BA_ "GenMsgCycleTime" BO_ 800 1000;
BA_ "GenMsgSendType" BO_ 800 0;
BA_ "GenMsgCycleTime" BO_ 818 1000;
BA_ "GenMsgSendType" BO_ 818 0;
BA_ "GenMsgCycleTime" BO_ 1138 1000;
BA_ "GenMsgSendType" BO_ 1138 0;
BA_ "GenMsgCycleTime" BO_ 562 100;
BA_ "GenMsgSendType" BO_ 562 0;
BA_ "GenMsgCycleTime" BO_ 2029 100;
BA_ "GenMsgSendType" BO_ 2029 0;
BA_ "GenMsgCycleTime" BO_ 722 100;
BA_ "GenMsgSendType" BO_ 722 0;
BA_ "GenMsgCycleTime" BO_ 690 2000;
BA_ "GenMsgSendType" BO_ 690 0;
BA_ "GenMsgCycleTime" BO_ 306 10;
BA_ "GenMsgSendType" BO_ 306 0;
BA_ "GenMsgCycleTime" BO_ 768 1000;
BA_ "GenMsgSendType" BO_ 768 0;
BA_ "GenMsgCycleTime" BO_ 978 1000;
BA_ "GenMsgSendType" BO_ 978 0;
BA_ "GenMsgCycleTime" BO_ 1010 1000;
BA_ "GenMsgSendType" BO_ 1010 0;
BA_ "GenMsgCycleTime" BO_ 884 1000;
BA_ "GenMsgSendType" BO_ 884 0;
BA_ "Confidence" SG_ 1343 BMS_alertID 1;
BA_ "GenSigSNA" SG_ 1343 BMS_alertID "127";
BA_ "Confidence" SG_ 1343 BMS_alertSet 1;
BA_ "Confidence" SG_ 1343 BMS_a001_gatewayPackEnergy 1;
BA_ "Confidence" SG_ 1343 BMS_a001_expectedPackEnergy 1;
BA_ "Confidence" SG_ 1343 BMS_a002_gatewayPackPerformanceD 1;
BA_ "SystemSignalLongSymbol" SG_ 1343 BMS_a002_gatewayPackPerformanceD "BMS_a002_gatewayPackPerformanceDeviation";
BA_ "Confidence" SG_ 1343 BMS_a002_expectedPackPerformance 1;
BA_ "SystemSignalLongSymbol" SG_ 1343 BMS_a002_expectedPackPerformance "BMS_a002_expectedPackPerformanceDeviation";
BA_ "Confidence" SG_ 1343 BMS_a002_bmsPackMass 1;
BA_ "Confidence" SG_ 1343 BMS_a007_minPackTemperature 1;
BA_ "Confidence" SG_ 1343 BMS_a007_packCurrent 1;
BA_ "Confidence" SG_ 1343 BMS_a007_idealCurrentTarget 1;
BA_ "Confidence" SG_ 1343 BMS_a017_packCurrent 1;
BA_ "Confidence" SG_ 1343 BMS_a017_ovBrickV 1;
BA_ "Confidence" SG_ 1343 BMS_a018_packCurrent 1;
BA_ "Confidence" SG_ 1343 BMS_a018_uvBrickV 1;
BA_ "Confidence" SG_ 1343 BMS_a019_coolantInletT 1;
BA_ "Confidence" SG_ 1343 BMS_a019_activeCoolingTarget 1;
BA_ "Confidence" SG_ 1343 BMS_a019_maxBrickT 1;
BA_ "Confidence" SG_ 1343 BMS_a021_currentLimit 1;
BA_ "Confidence" SG_ 1343 BMS_a021_packCurrent 1;
BA_ "SystemSignalLongSymbol" SG_ 1343 BMS_a022_chargeAccumulatorViolat "BMS_a022_chargeAccumulatorViolation";
BA_ "Confidence" SG_ 1343 BMS_a022_chargeAccumulatorValue 1;
BA_ "Confidence" SG_ 1343 BMS_a022_chargeAccumulatorLimit 1;
BA_ "Confidence" SG_ 1343 BMS_a023_ovStackDeviceID 1;
BA_ "Confidence" SG_ 1343 BMS_a023_ovStackV 1;
BA_ "Confidence" SG_ 1343 BMS_a024_brickID 1;
BA_ "Confidence" SG_ 1343 BMS_a024_deltaV 1;
BA_ "Confidence" SG_ 1343 BMS_a024_avgDvPrev 1;
BA_ "Confidence" SG_ 1343 BMS_a024_packCurrent 1;
BA_ "Confidence" SG_ 1343 BMS_a030_maxBrickImpedance 1;
BA_ "Confidence" SG_ 1343 BMS_a030_maxNormalizedImpedanceD 1;
BA_ "SystemSignalLongSymbol" SG_ 1343 BMS_a030_maxNormalizedImpedanceD "BMS_a030_maxNormalizedImpedanceDev";
BA_ "Confidence" SG_ 1343 BMS_a030_faultThreshold 1;
BA_ "Confidence" SG_ 1343 BMS_a030_worstBrickSoc 1;
BA_ "Confidence" SG_ 1343 BMS_a035_isoR 1;
BA_ "Confidence" SG_ 1343 BMS_a035_mode 1;
BA_ "Confidence" SG_ 1343 BMS_a035_activeSideVNoR 1;
BA_ "Confidence" SG_ 1343 BMS_a035_activeSideVWithR 1;
BA_ "Confidence" SG_ 1343 BMS_a035_passiveSideVNoR 1;
BA_ "Confidence" SG_ 1343 BMS_a035_passiveSideVWithR 1;
BA_ "Confidence" SG_ 1343 BMS_a037_floodPort1State 1;
BA_ "GenSigSNA" SG_ 1343 BMS_a037_floodPort1State "0";
BA_ "Confidence" SG_ 1343 BMS_a037_floodPort1Voltage 1;
BA_ "Confidence" SG_ 1343 BMS_a037_floodPort2State 1;
BA_ "GenSigSNA" SG_ 1343 BMS_a037_floodPort2State "0";
BA_ "Confidence" SG_ 1343 BMS_a037_floodPort2Voltage 1;
BA_ "Confidence" SG_ 1343 BMS_a039_dcLinkVoltage 1;
BA_ "Confidence" SG_ 1343 BMS_a039_packVoltage 1;
BA_ "Confidence" SG_ 1343 BMS_a039_packContactorState 1;
BA_ "GenSigSNA" SG_ 1343 BMS_a039_packContactorState "0";
BA_ "Confidence" SG_ 1343 BMS_a039_packCurrent 1;
BA_ "Confidence" SG_ 1343 BMS_a039_maxBrickV 1;
BA_ "Confidence" SG_ 1343 BMS_a039_state 1;
BA_ "GenSigSNA" SG_ 1343 BMS_a039_state "9";
BA_ "Confidence" SG_ 1343 BMS_a041_resetType 1;
BA_ "Confidence" SG_ 1343 BMS_a051_hvp1V5Ref 1;
BA_ "Confidence" SG_ 1343 BMS_a051_hvp3V0Ref 1;
BA_ "Confidence" SG_ 1343 BMS_a051_bms3V0Ref 1;
BA_ "Confidence" SG_ 1343 BMS_a056_standbySupplyOutV 1;
BA_ "Confidence" SG_ 1343 BMS_a056_packVoltage 1;
BA_ "Confidence" SG_ 1343 BMS_a056_minBrickVoltage 1;
BA_ "Confidence" SG_ 1343 BMS_a058_bandoThmModelState 1;
BA_ "GenSigSNA" SG_ 1343 BMS_a058_bandoThmModelState "0";
BA_ "Confidence" SG_ 1343 BMS_a058_tempDelta1 1;
BA_ "Confidence" SG_ 1343 BMS_a058_tempDelta2 1;
BA_ "Confidence" SG_ 1343 BMS_a058_tempDelta3 1;
BA_ "Confidence" SG_ 1343 BMS_a058_tempDelta4 1;
BA_ "Confidence" SG_ 1343 BMS_a059_sumBrickVoltages 1;
BA_ "Confidence" SG_ 1343 BMS_a059_packVoltage 1;
BA_ "Confidence" SG_ 1343 BMS_a062_state 1;
BA_ "GenSigSNA" SG_ 1343 BMS_a062_state "9";
BA_ "Confidence" SG_ 1343 BMS_a062_minBrickVoltage 1;
BA_ "Confidence" SG_ 1343 BMS_a062_maxBrickVoltage 1;
BA_ "Confidence" SG_ 1343 BMS_a063_cpFaultInV 1;
BA_ "Confidence" SG_ 1343 BMS_a064_minBrickSOC 1;
BA_ "Confidence" SG_ 1343 BMS_a064_maxBrickSOC 1;
BA_ "Confidence" SG_ 1343 BMS_a064_avgBrickSOC 1;
BA_ "Confidence" SG_ 1343 BMS_a065_minBrickCac 1;
BA_ "Confidence" SG_ 1343 BMS_a065_avgBrickCac 1;
BA_ "Confidence" SG_ 1343 BMS_a065_modCacImbalancePct 1;
BA_ "Confidence" SG_ 1343 BMS_a066_minBrickSocByOcvMax 1;
BA_ "Confidence" SG_ 1343 BMS_a066_maxBrickSocByOcvMin 1;
BA_ "Confidence" SG_ 1343 BMS_a066_maxBrickSoc 1;
BA_ "Confidence" SG_ 1343 BMS_a066_avgBrickSoc 1;
BA_ "Confidence" SG_ 1343 BMS_a067_minBrickCac 1;
BA_ "Confidence" SG_ 1343 BMS_a067_avgBrickCac 1;
BA_ "Confidence" SG_ 1343 BMS_a067_modCacImbalancePct 1;
BA_ "Confidence" SG_ 1343 BMS_a068_minBrickCac 1;
BA_ "Confidence" SG_ 1343 BMS_a068_avgBrickCac 1;
BA_ "Confidence" SG_ 1343 BMS_a068_modCacImbalancePct 1;
BA_ "Confidence" SG_ 1343 BMS_a069_dischargePowerPackVolta 1;
BA_ "SystemSignalLongSymbol" SG_ 1343 BMS_a069_dischargePowerPackVolta "BMS_a069_dischargePowerPackVoltageFloor";
BA_ "Confidence" SG_ 1343 BMS_a069_dischargePowerBrickVolt 1;
BA_ "SystemSignalLongSymbol" SG_ 1343 BMS_a069_dischargePowerBrickVolt "BMS_a069_dischargePowerBrickVoltageFloor";
BA_ "Confidence" SG_ 1343 BMS_a069_SOC 1;
BA_ "Confidence" SG_ 1343 BMS_a069_minBrickT 1;
BA_ "Confidence" SG_ 1343 BMS_a069_minBrickVLimit 1;
BA_ "Confidence" SG_ 1343 BMS_a069_minBrickV 1;
BA_ "Confidence" SG_ 1343 BMS_a070_state 1;
BA_ "GenSigSNA" SG_ 1343 BMS_a070_state "9";
BA_ "Confidence" SG_ 1343 BMS_a070_minBrickVoltage 1;
BA_ "Confidence" SG_ 1343 BMS_a070_maxBrickVoltage 1;
BA_ "Confidence" SG_ 1343 BMS_a071_stateRequest 1;
BA_ "GenSigSNA" SG_ 1343 BMS_a071_stateRequest "9";
BA_ "Confidence" SG_ 1343 BMS_a071_state 1;
BA_ "GenSigSNA" SG_ 1343 BMS_a071_state "9";
BA_ "Confidence" SG_ 1343 BMS_a074_maxBrickVTarget 1;
BA_ "Confidence" SG_ 1343 BMS_a074_maxBrickV 1;
BA_ "Confidence" SG_ 1343 BMS_a075_chargeType 1;
BA_ "Confidence" SG_ 1343 BMS_a076_netAh 1;
BA_ "Confidence" SG_ 1343 BMS_a078_peakDchInChg 1;
BA_ "GenSigSNA" SG_ 1343 BMS_a078_peakDchInChg "32768";
BA_ "Confidence" SG_ 1343 BMS_a079_maxBrickVTarget 1;
BA_ "Confidence" SG_ 1343 BMS_a079_maxBrickV 1;
BA_ "Confidence" SG_ 1343 BMS_a081_stateRequest 1;
BA_ "GenSigSNA" SG_ 1343 BMS_a081_stateRequest "9";
BA_ "Confidence" SG_ 1343 BMS_a081_firstBlockingAlertId 1;
BA_ "GenSigSNA" SG_ 1343 BMS_a081_firstBlockingAlertId "127";
BA_ "Confidence" SG_ 1343 BMS_a081_secondBlockingAlertId 1;
BA_ "GenSigSNA" SG_ 1343 BMS_a081_secondBlockingAlertId "127";
BA_ "Confidence" SG_ 1343 BMS_a081_thirdBlockingAlertId 1;
BA_ "GenSigSNA" SG_ 1343 BMS_a081_thirdBlockingAlertId "127";
BA_ "Confidence" SG_ 1343 BMS_a081_fourthBlockingAlertId 1;
BA_ "GenSigSNA" SG_ 1343 BMS_a081_fourthBlockingAlertId "127";
BA_ "Confidence" SG_ 1343 BMS_a082_stateRequest 1;
BA_ "GenSigSNA" SG_ 1343 BMS_a082_stateRequest "9";
BA_ "Confidence" SG_ 1343 BMS_a082_firstAlertId 1;
BA_ "GenSigSNA" SG_ 1343 BMS_a082_firstAlertId "127";
BA_ "Confidence" SG_ 1343 BMS_a082_secondAlertId 1;
BA_ "GenSigSNA" SG_ 1343 BMS_a082_secondAlertId "127";
BA_ "Confidence" SG_ 1343 BMS_a082_thirdAlertId 1;
BA_ "GenSigSNA" SG_ 1343 BMS_a082_thirdAlertId "127";
BA_ "Confidence" SG_ 1343 BMS_a082_fourthAlertId 1;
BA_ "GenSigSNA" SG_ 1343 BMS_a082_fourthAlertId "127";
BA_ "Confidence" SG_ 1343 BMS_a083_packContactorRequest 1;
BA_ "GenSigSNA" SG_ 1343 BMS_a083_packContactorRequest "0";
BA_ "Confidence" SG_ 1343 BMS_a085_packContactorSetStatePr 1;
BA_ "GenSigSNA" SG_ 1343 BMS_a085_packContactorSetStatePr "0";
BA_ "SystemSignalLongSymbol" SG_ 1343 BMS_a085_packContactorSetStatePr "BMS_a085_packContactorSetStatePrev";
BA_ "Confidence" SG_ 1343 BMS_a085_packContactorSetState 1;
BA_ "GenSigSNA" SG_ 1343 BMS_a085_packContactorSetState "0";
BA_ "Confidence" SG_ 1343 BMS_a085_packContactorSetRe_0001 1;
BA_ "GenSigSNA" SG_ 1343 BMS_a085_packContactorSetRe_0001 "0";
BA_ "SystemSignalLongSymbol" SG_ 1343 BMS_a085_packContactorSetRe_0001 "BMS_a085_packContactorSetRequestPrev";
BA_ "Confidence" SG_ 1343 BMS_a085_packContactorSetRequest 1;
BA_ "GenSigSNA" SG_ 1343 BMS_a085_packContactorSetRequest "0";
BA_ "Confidence" SG_ 1343 BMS_a086_fcContactorSetStatePrev 1;
BA_ "GenSigSNA" SG_ 1343 BMS_a086_fcContactorSetStatePrev "0";
BA_ "Confidence" SG_ 1343 BMS_a086_fcContactorSetState 1;
BA_ "GenSigSNA" SG_ 1343 BMS_a086_fcContactorSetState "0";
BA_ "Confidence" SG_ 1343 BMS_a086_fcContactorSetRequestPr 1;
BA_ "GenSigSNA" SG_ 1343 BMS_a086_fcContactorSetRequestPr "0";
BA_ "SystemSignalLongSymbol" SG_ 1343 BMS_a086_fcContactorSetRequestPr "BMS_a086_fcContactorSetRequestPrev";
BA_ "Confidence" SG_ 1343 BMS_a086_fcContactorSetRequest 1;
BA_ "GenSigSNA" SG_ 1343 BMS_a086_fcContactorSetRequest "0";
BA_ "Confidence" SG_ 1343 BMS_a087_blockingAlert 1;
BA_ "GenSigSNA" SG_ 1343 BMS_a087_blockingAlert "127";
BA_ "Confidence" SG_ 1343 BMS_a090_GTWmessageTout 1;
BA_ "Confidence" SG_ 1343 BMS_a098_bmbCommStatusTypeA 1;
BA_ "Confidence" SG_ 1343 BMS_a098_bmbCommStatusTypeB 1;
BA_ "Confidence" SG_ 1343 BMS_a099_bmbCommStatusTypeA 1;
BA_ "Confidence" SG_ 1343 BMS_a099_bmbCommStatusTypeB 1;
BA_ "Confidence" SG_ 1343 BMS_a099_bmbChainBreakType 1;
BA_ "Confidence" SG_ 1343 BMS_a105_avgBrickTModule1 1;
BA_ "Confidence" SG_ 1343 BMS_a105_avgBrickTModule2 1;
BA_ "Confidence" SG_ 1343 BMS_a105_avgBrickTModule3 1;
BA_ "Confidence" SG_ 1343 BMS_a105_avgBrickTModule4 1;
BA_ "Confidence" SG_ 1343 BMS_a105_inletTemp 1;
BA_ "Confidence" SG_ 1343 BMS_a106_minBrickT 1;
BA_ "Confidence" SG_ 1343 BMS_a106_maxBrickT 1;
BA_ "Confidence" SG_ 1343 BMS_a106_avgBrickT 1;
BA_ "Confidence" SG_ 1343 BMS_a106_inletTemp 1;
BA_ "Confidence" SG_ 1343 BMS_a117_brickSoc2 1;
BA_ "GenSigSNA" SG_ 1343 BMS_a117_brickSoc2 "1023";
BA_ "Confidence" SG_ 1343 BMS_a117_dSocAlertThreshold 1;
BA_ "Confidence" SG_ 1343 BMS_a117_dSocAlpha 1;
BA_ "GenSigSNA" SG_ 1343 BMS_a117_dSocAlpha "4095";
BA_ "Confidence" SG_ 1343 BMS_a122_irrationalThermistorTem 1;
BA_ "SystemSignalLongSymbol" SG_ 1343 BMS_a122_irrationalThermistorTem "BMS_a122_irrationalThermistorTemp";
BA_ "Confidence" SG_ 1343 BMS_a122_averageRawThermistorTem 1;
BA_ "SystemSignalLongSymbol" SG_ 1343 BMS_a122_averageRawThermistorTem "BMS_a122_averageRawThermistorTemp";
BA_ "Confidence" SG_ 1343 BMS_a122_minRawThermistorTemp 1;
BA_ "Confidence" SG_ 1343 BMS_a122_maxRawThermistorTemp 1;
BA_ "Confidence" SG_ 1343 BMS_a123_packPlus 1;
BA_ "Confidence" SG_ 1343 BMS_a123_isoR 1;
BA_ "Confidence" SG_ 1343 BMS_a123_packMinus 1;
BA_ "Confidence" SG_ 1343 BMS_a129_brickID 1;
BA_ "Confidence" SG_ 1343 BMS_a129_deltaV 1;
BA_ "Confidence" SG_ 1343 BMS_a129_retryCount 1;
BA_ "Confidence" SG_ 1343 BMS_a131_brickID 1;
BA_ "Confidence" SG_ 1343 BMS_a131_deltaV 1;
BA_ "Confidence" SG_ 1343 BMS_a131_retryCount 1;
BA_ "Confidence" SG_ 1343 BMS_a135_bmbDiagnosticsType 1;
BA_ "Confidence" SG_ 1343 BMS_a136_coolantInletT 1;
BA_ "Confidence" SG_ 1343 BMS_a136_activeCoolingTarget 1;
BA_ "Confidence" SG_ 1343 BMS_a136_maxBrickT 1;
BA_ "Confidence" SG_ 1343 BMS_a139_packVoltage 1;
BA_ "Confidence" SG_ 1343 BMS_a139_dcLinkVoltage 1;
BA_ "Confidence" SG_ 1343 BMS_a140_faultType 1;
BA_ "Confidence" SG_ 1343 BMS_a142_isolationResistance 1;
BA_ "Confidence" SG_ 1343 BMS_a142_mode 1;
BA_ "Confidence" SG_ 1343 BMS_a143_initialSoc 1;
BA_ "Confidence" SG_ 1343 BMS_a143_endingSoc 1;
BA_ "Confidence" SG_ 1343 BMS_a143_deltaAh 1;
BA_ "Confidence" SG_ 1343 BMS_a143_cacUpdateError 1;
BA_ "Confidence" SG_ 1343 BMS_a145_maxSocChange 1;
BA_ "Confidence" SG_ 1343 BMS_a145_brickChangeHystRatio 1;
BA_ "GenSigSNA" SG_ 1343 BMS_a145_brickChangeHystRatio "1023";
BA_ "Confidence" SG_ 1343 BMS_a146_maxBrickV 1;
BA_ "Confidence" SG_ 1343 BMS_a146_state 1;
BA_ "GenSigSNA" SG_ 1343 BMS_a146_state "9";
BA_ "Confidence" SG_ 1343 BMS_a146_packCurrent 1;
BA_ "Confidence" SG_ 1343 BMS_a146_uvBrickV 1;
BA_ "Confidence" SG_ 1343 BMS_a151_isoPositiveR 1;
BA_ "Confidence" SG_ 1343 BMS_a151_isoNegativeR 1;
BA_ "Confidence" SG_ 1343 BMS_a152_isoR 1;
BA_ "Confidence" SG_ 1343 BMS_a152_mode 1;
BA_ "Confidence" SG_ 1343 BMS_a152_activeSideVNoR 1;
BA_ "Confidence" SG_ 1343 BMS_a152_activeSideVWithR 1;
BA_ "Confidence" SG_ 1343 BMS_a152_passiveSideVNoR 1;
BA_ "Confidence" SG_ 1343 BMS_a152_passiveSideVWithR 1;
BA_ "Confidence" SG_ 1343 BMS_a156_VrefSample 1;
BA_ "Confidence" SG_ 1343 BMS_a156_VrefStatus 1;
BA_ "Confidence" SG_ 1343 BMS_a162_dischargePower_W 1;
BA_ "Confidence" SG_ 1343 BMS_a162_minSoc 1;
BA_ "Confidence" SG_ 1343 BMS_a162_socThreshold 1;
BA_ "Confidence" SG_ 1343 BMS_a164_regenPower 1;
BA_ "Confidence" SG_ 1343 BMS_a165_packPositiveV 1;
BA_ "Confidence" SG_ 1343 BMS_a165_packNegativeV 1;
BA_ "Confidence" SG_ 1343 BMS_a165_dcLinkPositiveV 1;
BA_ "Confidence" SG_ 1343 BMS_a165_dcLinkNegativeV 1;
BA_ "Confidence" SG_ 1343 BMS_a166_packPositiveV 1;
BA_ "Confidence" SG_ 1343 BMS_a166_packNegativeV 1;
BA_ "Confidence" SG_ 1343 BMS_a166_dcLinkPositiveV 1;
BA_ "Confidence" SG_ 1343 BMS_a166_dcLinkNegativeV 1;
BA_ "Confidence" SG_ 1343 BMS_a167_dcLinkPositiveV 1;
BA_ "Confidence" SG_ 1343 BMS_a167_dcLinkNegativeV 1;
BA_ "Confidence" SG_ 1343 BMS_a167_fcLinkPositiveV 1;
BA_ "Confidence" SG_ 1343 BMS_a167_fcLinkNegativeV 1;
BA_ "Confidence" SG_ 1343 BMS_a168_dcLinkPositiveV 1;
BA_ "Confidence" SG_ 1343 BMS_a168_dcLinkNegativeV 1;
BA_ "Confidence" SG_ 1343 BMS_a168_fcLinkPositiveV 1;
BA_ "Confidence" SG_ 1343 BMS_a168_fcLinkNegativeV 1;
BA_ "Confidence" SG_ 1343 BMS_a171_stackVoltage 1;
BA_ "Confidence" SG_ 1343 BMS_a171_sumBrickVoltage 1;
BA_ "Confidence" SG_ 1343 BMS_a177_energyAlertThreshold 1;
BA_ "Confidence" SG_ 1343 BMS_a177_energyBuffer 1;
BA_ "Confidence" SG_ 1343 BMS_a178_diPower 1;
BA_ "Confidence" SG_ 1343 BMS_a178_energyError 1;
BA_ "Confidence" SG_ 1343 BMS_a178_powerError 1;
BA_ "Confidence" SG_ 1343 BMS_a178_minPowerError 1;
BA_ "Confidence" SG_ 1343 BMS_a178_maxPowerError 1;
BA_ "Confidence" SG_ 800 BMS_matrixIndex 1;
BA_ "SystemSignalLongSymbol" SG_ 800 BMS_a002_Pack_Performance_Config "BMS_a002_Pack_Performance_Config_Mismatch";
BA_ "SystemSignalLongSymbol" SG_ 800 BMS_a003_SW_Pack_Birth_Date_Miss "BMS_a003_SW_Pack_Birth_Date_Missing";
BA_ "SystemSignalLongSymbol" SG_ 800 BMS_a004_Cal_Vs_Serial_Birth_Dat "BMS_a004_Cal_Vs_Serial_Birth_Date_Mismatch";
BA_ "SystemSignalLongSymbol" SG_ 800 BMS_a027_SW_Repeated_Isolation_F "BMS_a027_SW_Repeated_Isolation_Failure_In_Drive";
BA_ "SystemSignalLongSymbol" SG_ 800 BMS_a028_ShuntAsicCurrentOffsetD "BMS_a028_ShuntAsicCurrentOffsetDeviation";
BA_ "SystemSignalLongSymbol" SG_ 800 BMS_a040_SW_Watch_Dog_HW_Trigger "BMS_a040_SW_Watch_Dog_HW_Triggered";
BA_ "SystemSignalLongSymbol" SG_ 800 BMS_a041_SW_Destructive_Reset_So "BMS_a041_SW_Destructive_Reset_Source";
BA_ "SystemSignalLongSymbol" SG_ 800 BMS_a057_SW_Bandolier_Model_Warn "BMS_a057_SW_Bandolier_Model_Warning";
BA_ "SystemSignalLongSymbol" SG_ 800 BMS_a058_SW_Bandolier_Model_Rese "BMS_a058_SW_Bandolier_Model_Reset";
BA_ "SystemSignalLongSymbol" SG_ 800 BMS_a070_BrickV_Imbalance_Limiti "BMS_a070_BrickV_Imbalance_Limiting";
BA_ "SystemSignalLongSymbol" SG_ 800 BMS_a074_Max_Charge_Level_Reduce "BMS_a074_Max_Charge_Level_Reduced";
BA_ "SystemSignalLongSymbol" SG_ 800 BMS_a078_Rapid_Dch_While_Chargin "BMS_a078_Rapid_Dch_While_Charging";
BA_ "SystemSignalLongSymbol" SG_ 800 BMS_a079_Max_Charge_Level_Exceed "BMS_a079_Max_Charge_Level_Exceeded";
BA_ "Confidence" SG_ 800 BMS_a084_SW_Sleep_Wake_Aborted 0;
BA_ "SystemSignalLongSymbol" SG_ 800 BMS_a085_SW_Pack_Contactor_Misma "BMS_a085_SW_Pack_Contactor_Mismatch";
BA_ "SystemSignalLongSymbol" SG_ 800 BMS_a086_SW_FC_Contactor_Mismatc "BMS_a086_SW_FC_Contactor_Mismatch";
BA_ "SystemSignalLongSymbol" SG_ 800 BMS_a092_SW_ChargePort_Mia_On_Hv "BMS_a092_SW_ChargePort_Mia_On_Hvs";
BA_ "SystemSignalLongSymbol" SG_ 800 BMS_a097_SW_BMB_Over_CAN_Communi "BMS_a097_SW_BMB_Over_CAN_Communication";
BA_ "SystemSignalLongSymbol" SG_ 800 BMS_a098_SW_BMB_Data_Integrity_L "BMS_a098_SW_BMB_Data_Integrity_Loss";
BA_ "SystemSignalLongSymbol" SG_ 800 BMS_a109_HW_BMB_Mute_Status_Mism "BMS_a109_HW_BMB_Mute_Status_Mismatch";
BA_ "SystemSignalLongSymbol" SG_ 800 BMS_a110_LifeModel_AvgOffset_Cha "BMS_a110_LifeModel_AvgOffset_Change";
BA_ "SystemSignalLongSymbol" SG_ 800 BMS_a115_Energy_Rubberbanding_Re "BMS_a115_Energy_Rubberbanding_Reset";
BA_ "SystemSignalLongSymbol" SG_ 800 BMS_a135_HW_BMB_Diagnostics_Fail "BMS_a135_HW_BMB_Diagnostics_Failure";
BA_ "SystemSignalLongSymbol" SG_ 800 BMS_a142_SW_Isolation_Degradatio "BMS_a142_SW_Isolation_Degradation";
BA_ "SystemSignalLongSymbol" SG_ 800 BMS_a148_SW_Unsupported_BMB_ASIC "BMS_a148_SW_Unsupported_BMB_ASIC_Type";
BA_ "SystemSignalLongSymbol" SG_ 800 BMS_a154_SW_Brick_OV_Warning_Sto "BMS_a154_SW_Brick_OV_Warning_Stop_Charge";
BA_ "SystemSignalLongSymbol" SG_ 800 BMS_a172_SW_Isolation_Failure_In "BMS_a172_SW_Isolation_Failure_In_Drive_Warning";
BA_ "SystemSignalLongSymbol" SG_ 800 BMS_a178_SW_Uncontrolled_Regen_P "BMS_a178_SW_Uncontrolled_Regen_PwrB";
BA_ "SystemSignalLongSymbol" SG_ 800 BMS_a181_SW_Shunt_Over_Temperatu "BMS_a181_SW_Shunt_Over_Temperature";
BA_ "SystemSignalLongSymbol" SG_ 800 BMS_a182_LifeModel_NoCurrentLoss "BMS_a182_LifeModel_NoCurrentLoss_Change";
BA_ "SystemSignalLongSymbol" SG_ 800 BMS_a183_LifeModel_StoDcrGrowth_ "BMS_a183_LifeModel_StoDcrGrowth_Change";
BA_ "SystemSignalLongSymbol" SG_ 800 BMS_a184_LifeModel_CyclingLoss_C "BMS_a184_LifeModel_CyclingLoss_Change";
BA_ "SystemSignalLongSymbol" SG_ 800 BMS_a185_LifeModel_CyclingDcrGro "BMS_a185_LifeModel_CyclingDcrGrowth_Change";
BA_ "SystemSignalLongSymbol" SG_ 800 BMS_a186_RippleHeatingChargeFaul "BMS_a186_RippleHeatingChargeFault";
BA_ "SystemSignalLongSymbol" SG_ 800 BMS_a187_RippleHeatingEmergencyS "BMS_a187_RippleHeatingEmergencyShutdown";
BA_ "Confidence" SG_ 818 BMS_bmbMinMaxMultiplexer 0;
BA_ "Confidence" SG_ 818 BMS_thermistorNumTMin 1;
BA_ "Confidence" SG_ 818 BMS_thermistorNumTMax 1;
BA_ "Confidence" SG_ 818 BMS_thermistorTMax 1;
BA_ "Confidence" SG_ 818 BMS_thermistorTMin 1;
BA_ "Confidence" SG_ 818 BMS_thermistorTAvg 1;
BA_ "Confidence" SG_ 818 BMS_brickVoltageMax 0;
BA_ "Confidence" SG_ 818 BMS_brickVoltageMin 0;
BA_ "Confidence" SG_ 818 BMS_brickNumVoltageMax 0;
BA_ "Confidence" SG_ 818 BMS_brickNumVoltageMin 0;
BA_ "Confidence" SG_ 1138 BMS_cellChargeDcCurrentLimit 1;
BA_ "Confidence" SG_ 1138 BMS_voltageRegCurrentTarget 1;
BA_ "Confidence" SG_ 1138 BMS_vehicleChargeDcCurrentLimit 1;
BA_ "Confidence" SG_ 1138 BMS_chargeCurrentLimitMode 1;
BA_ "Confidence" SG_ 1138 BMS_timeToFinishHeatForCharge 1;
BA_ "GenSigSNA" SG_ 1138 BMS_timeToFinishHeatForCharge "127";
BA_ "Confidence" SG_ 1138 BMS_diNodeModelTemp 1;
BA_ "GenSigSNA" SG_ 1138 BMS_diNodeModelTemp "2047";
BA_ "Confidence" SG_ 562 BMS_internalHvilSenseV 1;
BA_ "Confidence" SG_ 562 BMS_hvilCoverVSense 1;
BA_ "Confidence" SG_ 2029 BMS_10HzDebug_Id 1;
BA_ "Confidence" SG_ 2029 BMS_activeCoolCellTargetT 1;
BA_ "Confidence" SG_ 2029 BMS_passiveCoolCellTargetT 1;
BA_ "Confidence" SG_ 722 BMS_minBusVoltage 1;
BA_ "Confidence" SG_ 722 BMS_maxBusVoltage 1;
BA_ "Confidence" SG_ 722 BMS_maxChargeCurrent 1;
BA_ "Confidence" SG_ 722 BMS_maxDischargeCurrent 1;
BA_ "Confidence" SG_ 690 BMS_energyStatusMultiplexer 1;
BA_ "Confidence" SG_ 690 BMS_nominalFullPackEnergy 1;
BA_ "GenSigSNA" SG_ 690 BMS_nominalFullPackEnergy "65535";
BA_ "Confidence" SG_ 690 BMS_nominalEnergyRemaining 1;
BA_ "GenSigSNA" SG_ 690 BMS_nominalEnergyRemaining "65535";
BA_ "Confidence" SG_ 690 BMS_idealEnergyRemaining 1;
BA_ "GenSigSNA" SG_ 690 BMS_idealEnergyRemaining "65535";
BA_ "Confidence" SG_ 690 BMS_fullChargeComplete 1;
BA_ "Confidence" SG_ 690 BMS_energyBuffer 1;
BA_ "GenSigSNA" SG_ 690 BMS_energyBuffer "65535";
BA_ "Confidence" SG_ 690 BMS_expectedEnergyRemaining 1;
BA_ "GenSigSNA" SG_ 690 BMS_expectedEnergyRemaining "65535";
BA_ "Confidence" SG_ 690 BMS_energyToChargeComplete 1;
BA_ "GenSigSNA" SG_ 690 BMS_energyToChargeComplete "65535";
BA_ "Confidence" SG_ 690 BMS_energyRemainingDisplay 1;
BA_ "GenSigSNA" SG_ 690 BMS_energyRemainingDisplay "65535";
BA_ "Confidence" SG_ 690 BMS_energyRemainingTDisplay 1;
BA_ "GenSigSNA" SG_ 690 BMS_energyRemainingTDisplay "65535";
BA_ "Confidence" SG_ 690 BMS_energyDisplayErrorBlendRate 1;
BA_ "Confidence" SG_ 690 BMS_userFacingSoe 1;
BA_ "GenSigSNA" SG_ 690 BMS_userFacingSoe "2047";
BA_ "Confidence" SG_ 306 BMS_packVoltage 1;
BA_ "Confidence" SG_ 306 BMS_packCurrent 0;
BA_ "GenSigSNA" SG_ 306 BMS_packCurrent "32768";
BA_ "Confidence" SG_ 306 BMS_currentUnfiltered 1;
BA_ "GenSigSNA" SG_ 306 BMS_currentUnfiltered "32768";
BA_ "Confidence" SG_ 306 BMS_chgTimeToFull 1;
BA_ "GenSigSNA" SG_ 306 BMS_chgTimeToFull "4095";
BA_ "Confidence" SG_ 768 BMS_infoIndex 1;
BA_ "Confidence" SG_ 768 BMS_buildType 1;
BA_ "Confidence" SG_ 768 BMS_pcbaId 1;
BA_ "Confidence" SG_ 768 BMS_assemblyId 1;
BA_ "Confidence" SG_ 768 BMS_usageId 1;
BA_ "Confidence" SG_ 768 BMS_subUsageId 1;
BA_ "Confidence" SG_ 978 BMS_kwhDischargeTotal 1;
BA_ "Confidence" SG_ 978 BMS_kwhChargeTotal 1;
BA_ "Confidence" SG_ 1010 BMS_kwhCounter_Id 0;
BA_ "Confidence" SG_ 1010 BMS_acChargerKwhTotal 0;
BA_ "Confidence" SG_ 1010 BMS_dcChargerKwhTotal 0;
BA_ "Confidence" SG_ 1010 BMS_kwhRegenChargeTotal 1;
BA_ "Confidence" SG_ 1010 BMS_kwhDriveDischargeTotal 1;
BA_ "Confidence" SG_ 1010 BMS_kwhDischargeTotalModule1 1;
BA_ "Confidence" SG_ 1010 BMS_kwhChargeTotalModule1 1;
BA_ "Confidence" SG_ 1010 BMS_kwhAcChargeTotalModule1 1;
BA_ "Confidence" SG_ 1010 BMS_kwhDcChargeTotalModule1 1;
BA_ "Confidence" SG_ 1010 BMS_kwhDischargeTotalModule2 1;
BA_ "Confidence" SG_ 1010 BMS_kwhChargeTotalModule2 1;
BA_ "Confidence" SG_ 1010 BMS_kwhAcChargeTotalModule2 1;
BA_ "Confidence" SG_ 1010 BMS_kwhDcChargeTotalModule2 1;
BA_ "Confidence" SG_ 1010 BMS_kwhDischargeTotalModule3 1;
BA_ "Confidence" SG_ 1010 BMS_kwhChargeTotalModule3 1;
BA_ "Confidence" SG_ 1010 BMS_kwhAcChargeTotalModule3 1;
BA_ "Confidence" SG_ 1010 BMS_kwhDcChargeTotalModule3 1;
BA_ "Confidence" SG_ 1010 BMS_kwhDischargeTotalModule4 1;
BA_ "Confidence" SG_ 1010 BMS_kwhChargeTotalModule4 1;
BA_ "Confidence" SG_ 1010 BMS_kwhAcChargeTotalModule4 1;
BA_ "Confidence" SG_ 1010 BMS_kwhDcChargeTotalModule4 1;
BA_ "Confidence" SG_ 884 BMS_log1MuxId 1;
BA_ "Confidence" SG_ 884 BMS_hvChargeStatus 1;
BA_ "Confidence" SG_ 884 BMS_extDcPrechargeVoltageLimit 1;
BA_ "Confidence" SG_ 884 BMS_dcChargeCurrentRequest 1;
BA_ "Confidence" SG_ 884 BMS_dcChargeCurrentLimit 1;
BA_ "Confidence" SG_ 884 BMS_dcChargeVoltageLimit 1;
BA_ "Confidence" SG_ 884 BMS_dcChargePowerLimit 1;
BA_ "Confidence" SG_ 884 BMS_acChargePowerRequest 1;
BA_ "Confidence" SG_ 884 BMS_maxExtIsoFcLinkV 1;
BA_ "Confidence" SG_ 884 BMS_minModeledPackTemp 1;
BA_ "Confidence" SG_ 884 BMS_maxModeledPackTemp 1;
BA_ "Confidence" SG_ 884 BMS_socByDvMaxSocLimit 1;
BA_ "Confidence" SG_ 884 BMS_socByDvVoltageChangeOverAh 1;
BA_ "Confidence" SG_ 884 BMS_socByDvMaxSocByAhCorrected 1;
BA_ "Confidence" SG_ 884 BMS_socByDvMaxBrickVoltage 1;
VAL_ 1343 BMS_alertID 188 "a188_DtcConfirmed" 187 "a187_RippleHeatingEmergencyShutdown" 186 "a186_RippleHeatingChargeFault" 185 "a185_LifeModel_CyclingDcrGrowth_Change" 184 "a184_LifeModel_CyclingLoss_Change" 183 "a183_LifeModel_StoDcrGrowth_Change" 182 "a182_LifeModel_NoCurrentLoss_Change" 181 "a181_SW_Shunt_Over_Temperature" 180 "a180_SW_ECU_reset_blocked" 179 "a179_HvpGpoRequestActive" 178 "a178_SW_Uncontrolled_Regen_PwrB" 177 "a177_SW_Energy_Buffer_Size" 176 "a176_SW_GracefulPowerOff" 175 "a175_Charge_Failure_External" 174 "a174_SW_Charge_Failure" 172 "a172_SW_Isolation_Failure_In_Drive_Warning" 171 "a171_SW_Stack_Voltage_Sense" 170 "a170_SW_Limp_Mode" 169 "a169_SW_FC_Pack_Weld" 168 "a168_SW_FC_Full_Weld" 167 "a167_SW_FC_Partial_Weld" 166 "a166_SW_Pack_Full_Weld" 165 "a165_SW_Pack_Partial_Weld" 164 "a164_SW_Uncontrolled_Regen" 162 "a162_SW_No_Power_For_Support" 161 "a161_SW_BMB_Vref_warning" 160 "a160_SW_FC_Ctr_Clean_Failed" 159 "a159_SW_HVP_ECU_Error" 158 "a158_SW_HVP_HVI_Comms" 157 "a157_SW_Hist_Update_Missed" 156 "a156_SW_BMB_Vref_bad" 155 "a155_SW_Weak_short_impedence" 154 "a154_SW_Brick_OV_Warning_Stop_Charge" 152 "a152_Isolation_In_Dc_Charge" 151 "a151_SW_external_isolation" 150 "a150_SW_Missing_Part_Number" 149 "a149_SW_Missing_Config_Block" 148 "a148_SW_Unsupported_BMB_ASIC_Type" 147 "a147_SW_SOC_High_Ah_Error" 146 "a146_SW_Brick_Overdischarged" 145 "a145_SW_SOC_Change" 144 "a144_Hvp_Config_Mismatch" 143 "a143_SW_CAC_Change" 142 "a142_SW_Isolation_Degradation" 141 "a141_SW_BMB_Status_Warning" 140 "a140_HW_BMB_Status_Fault" 139 "a139_SW_DC_Link_V_Irrational" 138 "a138_SW_Brick_OV_Warning" 137 "a137_SW_Brick_UV_Warning" 136 "a136_SW_Module_OT_Warning" 135 "a135_HW_BMB_Diagnostics_Failure" 134 "a134_SW_Delayed_Ctr_Off" 133 "a133_IO_CAN_Bus_Off" 132 "a132_HW_BMB_OTP_Uncorrctbl" 131 "a131_Bleed_FET_Failure" 130 "a130_IO_CAN_Error" 129 "a129_SW_VSH_Failure" 128 "a128_SW_shunt_MIA" 127 "a127_SW_shunt_SNA" 126 "a126_SW_Thermistor_Failure" 124 "a124_Battery_Coolant_Flood" 123 "a123_SW_Internal_Isolation" 122 "a122_SW_BMS_Therm_Irrational" 121 "a121_SW_NVRAM_Config_Error" 119 "a119_Fast_Open_Vsh_Detected" 117 "a117_SW_Delta_SOC_Weak_Short" 115 "a115_Energy_Rubberbanding_Reset" 112 "a112_LifeModel_Discontinuity" 111 "a111_LifeModel_Spread_Change" 110 "a110_LifeModel_AvgOffset_Change" 109 "a109_HW_BMB_Mute_Status_Mismatch" 108 "a108_SW_BMB_Device_OT" 107 "a107_SW_Stack_Voltage_MIA" 106 "a106_SW_All_Module_Tsense" 105 "a105_SW_One_Module_Tsense" 100 "a100_ThermalEventSuspected" 99 "a099_SW_BMB_Communication" 98 "a098_SW_BMB_Data_Integrity_Loss" 97 "a097_SW_BMB_Over_CAN_Communication" 95 "a095_SW_UI_MIA" 94 "a094_SW_Drive_Inverter_MIA" 92 "a092_SW_ChargePort_Mia_On_Hvs" 91 "a091_SW_ChargePort_MIA" 90 "a090_SW_Gateway_MIA" 89 "a089_SW_VcFront_MIA" 88 "a088_SW_VcFront_MIA_InDrive" 87 "a087_SW_Feim_Test_Blocked" 86 "a086_SW_FC_Contactor_Mismatch" 85 "a085_SW_Pack_Contactor_Mismatch" 84 "a084_SW_Sleep_Wake_Aborted" 83 "a083_SW_Ctr_Close_Failure" 82 "a082_SW_Ctr_Force_Open" 81 "a081_SW_Ctr_Close_Blocked" 80 "a080_SW_Pack_Ctr_Impedance" 79 "a079_Max_Charge_Level_Exceeded" 78 "a078_Rapid_Dch_While_Charging" 77 "a077_SW_Charger_Regulation" 76 "a076_SW_Dch_While_Charging" 75 "a075_SW_Chg_Disable_Failure" 74 "a074_Max_Charge_Level_Reduced" 73 "a073_Unexpected_Loss_Of_Lv" 72 "a072_Module_Brick_Split" 71 "a071_SW_SM_TransCon_Not_Met" 70 "a070_BrickV_Imbalance_Limiting" 69 "a069_SW_Low_Power" 68 "a068_CAC_Imbalance_Limp" 67 "a067_CAC_Imbalance_Limiting" 66 "a066_SOC_Imbalance_Warning" 65 "a065_SW_CAC_Imbalance" 64 "a064_SW_SOC_Imbalance" 63 "a063_SW_ChargePort_Fault" 62 "a062_SW_BrickV_Imbalance" 61 "a061_SW_BrickV_Change" 60 "a060_SW_Leakage_Test_Failure" 59 "a059_SW_Pack_Voltage_Sensing" 58 "a058_SW_Bandolier_Model_Reset" 57 "a057_SW_Bandolier_Model_Warning" 56 "a056_SW_Standby_Supply_Fault" 55 "a055_SW_HvChain_Model_Fault" 54 "a054_SW_Ver_Supply_Fault" 52 "a052_SW_PCS_MIA" 51 "a051_SW_HVC_Vref_Bad" 50 "a050_SW_Brick_Voltage_MIA" 49 "a049_SW_Thermal_Event" 48 "a048_SW_Watch_Dog_Warning" 47 "a047_SW_Task_Stack_Overflow" 46 "a046_SW_Task_Stack_Usage" 45 "a045_SW_Exception" 44 "a044_SW_Assertion" 43 "a043_SW_Watch_Dog_Reset" 42 "a042_SW_MPU_Error" 41 "a041_SW_Destructive_Reset_Source" 40 "a040_SW_Watch_Dog_HW_Triggered" 39 "a039_SW_DC_Link_Over_Voltage" 37 "a037_SW_Flood_Port_Open" 36 "a036_SW_HvpHvilFault" 35 "a035_SW_Isolation" 34 "a034_SW_Passive_Isolation" 33 "a033_VoltageDeviation" 32 "a032_VoltageLoss" 31 "a031_AlertsSetDuringSleep" 30 "a030_Impedance_Deviation" 29 "a029_dSoc_Limiting" 28 "a028_ShuntAsicCurrentOffsetDeviation" 27 "a027_SW_Repeated_Isolation_Failure_In_Drive" 26 "a026_SW_HFCurrent_Anomaly" 25 "a025_SW_PwrBalance_Anomaly" 24 "a024_SW_Islanded_Brick" 23 "a023_SW_Stack_OV" 22 "a022_SW_Over_Current" 21 "a021_SW_Dr_Limits_Regulation" 20 "a020_SW_Brick_Instability" 19 "a019_SW_Module_OT" 18 "a018_SW_Brick_UV" 17 "a017_SW_Brick_OV" 16 "a016_Pack_Module_Id_Mismatch" 7 "a007_SW_Slowed_Chg_Batt_Cold" 4 "a004_Cal_Vs_Serial_Birth_Date_Mismatch" 3 "a003_SW_Pack_Birth_Date_Missing" 2 "a002_Pack_Performance_Config_Mismatch" 1 "a001_Pack_Config_Mismatch" 0 "ALERT_DO_NOT_USE_ZERO" ;
VAL_ 1343 BMS_alertSet 1 "SET" 0 "CLEARED" ;
VAL_ 1343 BMS_a001_gatewayPackEnergy 2 "MR" 1 "LR" 0 "SR" ;
VAL_ 1343 BMS_a001_expectedPackEnergy 2 "MR" 1 "LR" 0 "SR" ;
VAL_ 1343 BMS_a002_gatewayPackPerformanceD 4 "PACK_MASS_DEVIATION_2" 3 "PACK_STRUCTURAL_DEVIATION_1" 2 "PACK_POWER_DEVIATION_1" 1 "PACK_MASS_DEVIATION_1" 0 "NO_DEVIATION" ;
VAL_ 1343 BMS_a002_expectedPackPerformance 4 "PACK_MASS_DEVIATION_2" 3 "PACK_STRUCTURAL_DEVIATION_1" 2 "PACK_POWER_DEVIATION_1" 1 "PACK_MASS_DEVIATION_1" 0 "NO_DEVIATION" ;
VAL_ 1343 BMS_a035_mode 4 "VOLTAGE_SETTLING_MODE" 3 "FEIM_POSITIVE_MODE" 2 "FEIM_NEGATIVE_MODE" 1 "VEHICLE_ISOLATION_MODE" 0 "MODE_RESET" ;
VAL_ 1343 BMS_a037_floodPort1State 4 "ERROR_HIGH" 3 "OPEN" 2 "CLOSED" 1 "ERROR_LOW" 0 "SNA" ;
VAL_ 1343 BMS_a037_floodPort2State 4 "ERROR_HIGH" 3 "OPEN" 2 "CLOSED" 1 "ERROR_LOW" 0 "SNA" ;
VAL_ 1343 BMS_a039_packContactorState 9 "NEGATIVE_CLOSED" 8 "POSITIVE_CLOSED" 7 "WELDED" 6 "PARTIAL_WELD" 5 "CLOSED" 4 "OPENING" 3 "BLOCKED" 2 "CLOSING" 1 "OPEN" 0 "SNA" ;
VAL_ 1343 BMS_a039_state 10 "DIAG" 9 "SNA" 8 "TEST" 7 "WELD" 6 "FAULT" 5 "CLEAR_FAULT" 4 "FEIM" 3 "CHARGE" 2 "SUPPORT" 1 "DRIVE" 0 "STANDBY" ;
VAL_ 1343 BMS_a041_resetType 8 "SWT1_RES" 7 "SWT0_RES" 6 "SUF" 5 "FUNC_ESC" 4 "SSCM_SEC" 3 "SOFT_DEST" 2 "HSM_DEST" 1 "POR" 0 "NONE" ;
VAL_ 1343 BMS_a058_bandoThmModelState 8 "PAUSED" 7 "REINIT" 6 "FAULT" 5 "ACTIVE" 4 "FIRST_CHECK" 3 "PREPARING" 2 "INIT" 1 "OFF" 0 "SNA" ;
VAL_ 1343 BMS_a062_state 10 "DIAG" 9 "SNA" 8 "TEST" 7 "WELD" 6 "FAULT" 5 "CLEAR_FAULT" 4 "FEIM" 3 "CHARGE" 2 "SUPPORT" 1 "DRIVE" 0 "STANDBY" ;
VAL_ 1343 BMS_a070_state 10 "DIAG" 9 "SNA" 8 "TEST" 7 "WELD" 6 "FAULT" 5 "CLEAR_FAULT" 4 "FEIM" 3 "CHARGE" 2 "SUPPORT" 1 "DRIVE" 0 "STANDBY" ;
VAL_ 1343 BMS_a071_stateRequest 10 "DIAG" 9 "SNA" 8 "TEST" 7 "WELD" 6 "FAULT" 5 "CLEAR_FAULT" 4 "FEIM" 3 "CHARGE" 2 "SUPPORT" 1 "DRIVE" 0 "STANDBY" ;
VAL_ 1343 BMS_a071_state 10 "DIAG" 9 "SNA" 8 "TEST" 7 "WELD" 6 "FAULT" 5 "CLEAR_FAULT" 4 "FEIM" 3 "CHARGE" 2 "SUPPORT" 1 "DRIVE" 0 "STANDBY" ;
VAL_ 1343 BMS_a075_chargeType 1 "AC_CHARGE_SESSION" 0 "DC_CHARGE_SESSION" ;
VAL_ 1343 BMS_a078_peakDchInChg -32768 "SNA" ;
VAL_ 1343 BMS_a081_stateRequest 10 "DIAG" 9 "SNA" 8 "TEST" 7 "WELD" 6 "FAULT" 5 "CLEAR_FAULT" 4 "FEIM" 3 "CHARGE" 2 "SUPPORT" 1 "DRIVE" 0 "STANDBY" ;
VAL_ 1343 BMS_a081_firstBlockingAlertId 188 "a188_DtcConfirmed" 187 "a187_RippleHeatingEmergencyShutdown" 186 "a186_RippleHeatingChargeFault" 185 "a185_LifeModel_CyclingDcrGrowth_Change" 184 "a184_LifeModel_CyclingLoss_Change" 183 "a183_LifeModel_StoDcrGrowth_Change" 182 "a182_LifeModel_NoCurrentLoss_Change" 181 "a181_SW_Shunt_Over_Temperature" 180 "a180_SW_ECU_reset_blocked" 179 "a179_HvpGpoRequestActive" 178 "a178_SW_Uncontrolled_Regen_PwrB" 177 "a177_SW_Energy_Buffer_Size" 176 "a176_SW_GracefulPowerOff" 175 "a175_Charge_Failure_External" 174 "a174_SW_Charge_Failure" 172 "a172_SW_Isolation_Failure_In_Drive_Warning" 171 "a171_SW_Stack_Voltage_Sense" 170 "a170_SW_Limp_Mode" 169 "a169_SW_FC_Pack_Weld" 168 "a168_SW_FC_Full_Weld" 167 "a167_SW_FC_Partial_Weld" 166 "a166_SW_Pack_Full_Weld" 165 "a165_SW_Pack_Partial_Weld" 164 "a164_SW_Uncontrolled_Regen" 162 "a162_SW_No_Power_For_Support" 161 "a161_SW_BMB_Vref_warning" 160 "a160_SW_FC_Ctr_Clean_Failed" 159 "a159_SW_HVP_ECU_Error" 158 "a158_SW_HVP_HVI_Comms" 157 "a157_SW_Hist_Update_Missed" 156 "a156_SW_BMB_Vref_bad" 155 "a155_SW_Weak_short_impedence" 154 "a154_SW_Brick_OV_Warning_Stop_Charge" 152 "a152_Isolation_In_Dc_Charge" 151 "a151_SW_external_isolation" 150 "a150_SW_Missing_Part_Number" 149 "a149_SW_Missing_Config_Block" 148 "a148_SW_Unsupported_BMB_ASIC_Type" 147 "a147_SW_SOC_High_Ah_Error" 146 "a146_SW_Brick_Overdischarged" 145 "a145_SW_SOC_Change" 144 "a144_Hvp_Config_Mismatch" 143 "a143_SW_CAC_Change" 142 "a142_SW_Isolation_Degradation" 141 "a141_SW_BMB_Status_Warning" 140 "a140_HW_BMB_Status_Fault" 139 "a139_SW_DC_Link_V_Irrational" 138 "a138_SW_Brick_OV_Warning" 137 "a137_SW_Brick_UV_Warning" 136 "a136_SW_Module_OT_Warning" 135 "a135_HW_BMB_Diagnostics_Failure" 134 "a134_SW_Delayed_Ctr_Off" 133 "a133_IO_CAN_Bus_Off" 132 "a132_HW_BMB_OTP_Uncorrctbl" 131 "a131_Bleed_FET_Failure" 130 "a130_IO_CAN_Error" 129 "a129_SW_VSH_Failure" 128 "a128_SW_shunt_MIA" 127 "a127_SW_shunt_SNA" 126 "a126_SW_Thermistor_Failure" 124 "a124_Battery_Coolant_Flood" 123 "a123_SW_Internal_Isolation" 122 "a122_SW_BMS_Therm_Irrational" 121 "a121_SW_NVRAM_Config_Error" 119 "a119_Fast_Open_Vsh_Detected" 117 "a117_SW_Delta_SOC_Weak_Short" 115 "a115_Energy_Rubberbanding_Reset" 112 "a112_LifeModel_Discontinuity" 111 "a111_LifeModel_Spread_Change" 110 "a110_LifeModel_AvgOffset_Change" 109 "a109_HW_BMB_Mute_Status_Mismatch" 108 "a108_SW_BMB_Device_OT" 107 "a107_SW_Stack_Voltage_MIA" 106 "a106_SW_All_Module_Tsense" 105 "a105_SW_One_Module_Tsense" 100 "a100_ThermalEventSuspected" 99 "a099_SW_BMB_Communication" 98 "a098_SW_BMB_Data_Integrity_Loss" 97 "a097_SW_BMB_Over_CAN_Communication" 95 "a095_SW_UI_MIA" 94 "a094_SW_Drive_Inverter_MIA" 92 "a092_SW_ChargePort_Mia_On_Hvs" 91 "a091_SW_ChargePort_MIA" 90 "a090_SW_Gateway_MIA" 89 "a089_SW_VcFront_MIA" 88 "a088_SW_VcFront_MIA_InDrive" 87 "a087_SW_Feim_Test_Blocked" 86 "a086_SW_FC_Contactor_Mismatch" 85 "a085_SW_Pack_Contactor_Mismatch" 84 "a084_SW_Sleep_Wake_Aborted" 83 "a083_SW_Ctr_Close_Failure" 82 "a082_SW_Ctr_Force_Open" 81 "a081_SW_Ctr_Close_Blocked" 80 "a080_SW_Pack_Ctr_Impedance" 79 "a079_Max_Charge_Level_Exceeded" 78 "a078_Rapid_Dch_While_Charging" 77 "a077_SW_Charger_Regulation" 76 "a076_SW_Dch_While_Charging" 75 "a075_SW_Chg_Disable_Failure" 74 "a074_Max_Charge_Level_Reduced" 73 "a073_Unexpected_Loss_Of_Lv" 72 "a072_Module_Brick_Split" 71 "a071_SW_SM_TransCon_Not_Met" 70 "a070_BrickV_Imbalance_Limiting" 69 "a069_SW_Low_Power" 68 "a068_CAC_Imbalance_Limp" 67 "a067_CAC_Imbalance_Limiting" 66 "a066_SOC_Imbalance_Warning" 65 "a065_SW_CAC_Imbalance" 64 "a064_SW_SOC_Imbalance" 63 "a063_SW_ChargePort_Fault" 62 "a062_SW_BrickV_Imbalance" 61 "a061_SW_BrickV_Change" 60 "a060_SW_Leakage_Test_Failure" 59 "a059_SW_Pack_Voltage_Sensing" 58 "a058_SW_Bandolier_Model_Reset" 57 "a057_SW_Bandolier_Model_Warning" 56 "a056_SW_Standby_Supply_Fault" 55 "a055_SW_HvChain_Model_Fault" 54 "a054_SW_Ver_Supply_Fault" 52 "a052_SW_PCS_MIA" 51 "a051_SW_HVC_Vref_Bad" 50 "a050_SW_Brick_Voltage_MIA" 49 "a049_SW_Thermal_Event" 48 "a048_SW_Watch_Dog_Warning" 47 "a047_SW_Task_Stack_Overflow" 46 "a046_SW_Task_Stack_Usage" 45 "a045_SW_Exception" 44 "a044_SW_Assertion" 43 "a043_SW_Watch_Dog_Reset" 42 "a042_SW_MPU_Error" 41 "a041_SW_Destructive_Reset_Source" 40 "a040_SW_Watch_Dog_HW_Triggered" 39 "a039_SW_DC_Link_Over_Voltage" 37 "a037_SW_Flood_Port_Open" 36 "a036_SW_HvpHvilFault" 35 "a035_SW_Isolation" 34 "a034_SW_Passive_Isolation" 33 "a033_VoltageDeviation" 32 "a032_VoltageLoss" 31 "a031_AlertsSetDuringSleep" 30 "a030_Impedance_Deviation" 29 "a029_dSoc_Limiting" 28 "a028_ShuntAsicCurrentOffsetDeviation" 27 "a027_SW_Repeated_Isolation_Failure_In_Drive" 26 "a026_SW_HFCurrent_Anomaly" 25 "a025_SW_PwrBalance_Anomaly" 24 "a024_SW_Islanded_Brick" 23 "a023_SW_Stack_OV" 22 "a022_SW_Over_Current" 21 "a021_SW_Dr_Limits_Regulation" 20 "a020_SW_Brick_Instability" 19 "a019_SW_Module_OT" 18 "a018_SW_Brick_UV" 17 "a017_SW_Brick_OV" 16 "a016_Pack_Module_Id_Mismatch" 7 "a007_SW_Slowed_Chg_Batt_Cold" 4 "a004_Cal_Vs_Serial_Birth_Date_Mismatch" 3 "a003_SW_Pack_Birth_Date_Missing" 2 "a002_Pack_Performance_Config_Mismatch" 1 "a001_Pack_Config_Mismatch" 0 "ALERT_DO_NOT_USE_ZERO" ;
VAL_ 1343 BMS_a081_secondBlockingAlertId 188 "a188_DtcConfirmed" 187 "a187_RippleHeatingEmergencyShutdown" 186 "a186_RippleHeatingChargeFault" 185 "a185_LifeModel_CyclingDcrGrowth_Change" 184 "a184_LifeModel_CyclingLoss_Change" 183 "a183_LifeModel_StoDcrGrowth_Change" 182 "a182_LifeModel_NoCurrentLoss_Change" 181 "a181_SW_Shunt_Over_Temperature" 180 "a180_SW_ECU_reset_blocked" 179 "a179_HvpGpoRequestActive" 178 "a178_SW_Uncontrolled_Regen_PwrB" 177 "a177_SW_Energy_Buffer_Size" 176 "a176_SW_GracefulPowerOff" 175 "a175_Charge_Failure_External" 174 "a174_SW_Charge_Failure" 172 "a172_SW_Isolation_Failure_In_Drive_Warning" 171 "a171_SW_Stack_Voltage_Sense" 170 "a170_SW_Limp_Mode" 169 "a169_SW_FC_Pack_Weld" 168 "a168_SW_FC_Full_Weld" 167 "a167_SW_FC_Partial_Weld" 166 "a166_SW_Pack_Full_Weld" 165 "a165_SW_Pack_Partial_Weld" 164 "a164_SW_Uncontrolled_Regen" 162 "a162_SW_No_Power_For_Support" 161 "a161_SW_BMB_Vref_warning" 160 "a160_SW_FC_Ctr_Clean_Failed" 159 "a159_SW_HVP_ECU_Error" 158 "a158_SW_HVP_HVI_Comms" 157 "a157_SW_Hist_Update_Missed" 156 "a156_SW_BMB_Vref_bad" 155 "a155_SW_Weak_short_impedence" 154 "a154_SW_Brick_OV_Warning_Stop_Charge" 152 "a152_Isolation_In_Dc_Charge" 151 "a151_SW_external_isolation" 150 "a150_SW_Missing_Part_Number" 149 "a149_SW_Missing_Config_Block" 148 "a148_SW_Unsupported_BMB_ASIC_Type" 147 "a147_SW_SOC_High_Ah_Error" 146 "a146_SW_Brick_Overdischarged" 145 "a145_SW_SOC_Change" 144 "a144_Hvp_Config_Mismatch" 143 "a143_SW_CAC_Change" 142 "a142_SW_Isolation_Degradation" 141 "a141_SW_BMB_Status_Warning" 140 "a140_HW_BMB_Status_Fault" 139 "a139_SW_DC_Link_V_Irrational" 138 "a138_SW_Brick_OV_Warning" 137 "a137_SW_Brick_UV_Warning" 136 "a136_SW_Module_OT_Warning" 135 "a135_HW_BMB_Diagnostics_Failure" 134 "a134_SW_Delayed_Ctr_Off" 133 "a133_IO_CAN_Bus_Off" 132 "a132_HW_BMB_OTP_Uncorrctbl" 131 "a131_Bleed_FET_Failure" 130 "a130_IO_CAN_Error" 129 "a129_SW_VSH_Failure" 128 "a128_SW_shunt_MIA" 127 "a127_SW_shunt_SNA" 126 "a126_SW_Thermistor_Failure" 124 "a124_Battery_Coolant_Flood" 123 "a123_SW_Internal_Isolation" 122 "a122_SW_BMS_Therm_Irrational" 121 "a121_SW_NVRAM_Config_Error" 119 "a119_Fast_Open_Vsh_Detected" 117 "a117_SW_Delta_SOC_Weak_Short" 115 "a115_Energy_Rubberbanding_Reset" 112 "a112_LifeModel_Discontinuity" 111 "a111_LifeModel_Spread_Change" 110 "a110_LifeModel_AvgOffset_Change" 109 "a109_HW_BMB_Mute_Status_Mismatch" 108 "a108_SW_BMB_Device_OT" 107 "a107_SW_Stack_Voltage_MIA" 106 "a106_SW_All_Module_Tsense" 105 "a105_SW_One_Module_Tsense" 100 "a100_ThermalEventSuspected" 99 "a099_SW_BMB_Communication" 98 "a098_SW_BMB_Data_Integrity_Loss" 97 "a097_SW_BMB_Over_CAN_Communication" 95 "a095_SW_UI_MIA" 94 "a094_SW_Drive_Inverter_MIA" 92 "a092_SW_ChargePort_Mia_On_Hvs" 91 "a091_SW_ChargePort_MIA" 90 "a090_SW_Gateway_MIA" 89 "a089_SW_VcFront_MIA" 88 "a088_SW_VcFront_MIA_InDrive" 87 "a087_SW_Feim_Test_Blocked" 86 "a086_SW_FC_Contactor_Mismatch" 85 "a085_SW_Pack_Contactor_Mismatch" 84 "a084_SW_Sleep_Wake_Aborted" 83 "a083_SW_Ctr_Close_Failure" 82 "a082_SW_Ctr_Force_Open" 81 "a081_SW_Ctr_Close_Blocked" 80 "a080_SW_Pack_Ctr_Impedance" 79 "a079_Max_Charge_Level_Exceeded" 78 "a078_Rapid_Dch_While_Charging" 77 "a077_SW_Charger_Regulation" 76 "a076_SW_Dch_While_Charging" 75 "a075_SW_Chg_Disable_Failure" 74 "a074_Max_Charge_Level_Reduced" 73 "a073_Unexpected_Loss_Of_Lv" 72 "a072_Module_Brick_Split" 71 "a071_SW_SM_TransCon_Not_Met" 70 "a070_BrickV_Imbalance_Limiting" 69 "a069_SW_Low_Power" 68 "a068_CAC_Imbalance_Limp" 67 "a067_CAC_Imbalance_Limiting" 66 "a066_SOC_Imbalance_Warning" 65 "a065_SW_CAC_Imbalance" 64 "a064_SW_SOC_Imbalance" 63 "a063_SW_ChargePort_Fault" 62 "a062_SW_BrickV_Imbalance" 61 "a061_SW_BrickV_Change" 60 "a060_SW_Leakage_Test_Failure" 59 "a059_SW_Pack_Voltage_Sensing" 58 "a058_SW_Bandolier_Model_Reset" 57 "a057_SW_Bandolier_Model_Warning" 56 "a056_SW_Standby_Supply_Fault" 55 "a055_SW_HvChain_Model_Fault" 54 "a054_SW_Ver_Supply_Fault" 52 "a052_SW_PCS_MIA" 51 "a051_SW_HVC_Vref_Bad" 50 "a050_SW_Brick_Voltage_MIA" 49 "a049_SW_Thermal_Event" 48 "a048_SW_Watch_Dog_Warning" 47 "a047_SW_Task_Stack_Overflow" 46 "a046_SW_Task_Stack_Usage" 45 "a045_SW_Exception" 44 "a044_SW_Assertion" 43 "a043_SW_Watch_Dog_Reset" 42 "a042_SW_MPU_Error" 41 "a041_SW_Destructive_Reset_Source" 40 "a040_SW_Watch_Dog_HW_Triggered" 39 "a039_SW_DC_Link_Over_Voltage" 37 "a037_SW_Flood_Port_Open" 36 "a036_SW_HvpHvilFault" 35 "a035_SW_Isolation" 34 "a034_SW_Passive_Isolation" 33 "a033_VoltageDeviation" 32 "a032_VoltageLoss" 31 "a031_AlertsSetDuringSleep" 30 "a030_Impedance_Deviation" 29 "a029_dSoc_Limiting" 28 "a028_ShuntAsicCurrentOffsetDeviation" 27 "a027_SW_Repeated_Isolation_Failure_In_Drive" 26 "a026_SW_HFCurrent_Anomaly" 25 "a025_SW_PwrBalance_Anomaly" 24 "a024_SW_Islanded_Brick" 23 "a023_SW_Stack_OV" 22 "a022_SW_Over_Current" 21 "a021_SW_Dr_Limits_Regulation" 20 "a020_SW_Brick_Instability" 19 "a019_SW_Module_OT" 18 "a018_SW_Brick_UV" 17 "a017_SW_Brick_OV" 16 "a016_Pack_Module_Id_Mismatch" 7 "a007_SW_Slowed_Chg_Batt_Cold" 4 "a004_Cal_Vs_Serial_Birth_Date_Mismatch" 3 "a003_SW_Pack_Birth_Date_Missing" 2 "a002_Pack_Performance_Config_Mismatch" 1 "a001_Pack_Config_Mismatch" 0 "ALERT_DO_NOT_USE_ZERO" ;
VAL_ 1343 BMS_a081_thirdBlockingAlertId 188 "a188_DtcConfirmed" 187 "a187_RippleHeatingEmergencyShutdown" 186 "a186_RippleHeatingChargeFault" 185 "a185_LifeModel_CyclingDcrGrowth_Change" 184 "a184_LifeModel_CyclingLoss_Change" 183 "a183_LifeModel_StoDcrGrowth_Change" 182 "a182_LifeModel_NoCurrentLoss_Change" 181 "a181_SW_Shunt_Over_Temperature" 180 "a180_SW_ECU_reset_blocked" 179 "a179_HvpGpoRequestActive" 178 "a178_SW_Uncontrolled_Regen_PwrB" 177 "a177_SW_Energy_Buffer_Size" 176 "a176_SW_GracefulPowerOff" 175 "a175_Charge_Failure_External" 174 "a174_SW_Charge_Failure" 172 "a172_SW_Isolation_Failure_In_Drive_Warning" 171 "a171_SW_Stack_Voltage_Sense" 170 "a170_SW_Limp_Mode" 169 "a169_SW_FC_Pack_Weld" 168 "a168_SW_FC_Full_Weld" 167 "a167_SW_FC_Partial_Weld" 166 "a166_SW_Pack_Full_Weld" 165 "a165_SW_Pack_Partial_Weld" 164 "a164_SW_Uncontrolled_Regen" 162 "a162_SW_No_Power_For_Support" 161 "a161_SW_BMB_Vref_warning" 160 "a160_SW_FC_Ctr_Clean_Failed" 159 "a159_SW_HVP_ECU_Error" 158 "a158_SW_HVP_HVI_Comms" 157 "a157_SW_Hist_Update_Missed" 156 "a156_SW_BMB_Vref_bad" 155 "a155_SW_Weak_short_impedence" 154 "a154_SW_Brick_OV_Warning_Stop_Charge" 152 "a152_Isolation_In_Dc_Charge" 151 "a151_SW_external_isolation" 150 "a150_SW_Missing_Part_Number" 149 "a149_SW_Missing_Config_Block" 148 "a148_SW_Unsupported_BMB_ASIC_Type" 147 "a147_SW_SOC_High_Ah_Error" 146 "a146_SW_Brick_Overdischarged" 145 "a145_SW_SOC_Change" 144 "a144_Hvp_Config_Mismatch" 143 "a143_SW_CAC_Change" 142 "a142_SW_Isolation_Degradation" 141 "a141_SW_BMB_Status_Warning" 140 "a140_HW_BMB_Status_Fault" 139 "a139_SW_DC_Link_V_Irrational" 138 "a138_SW_Brick_OV_Warning" 137 "a137_SW_Brick_UV_Warning" 136 "a136_SW_Module_OT_Warning" 135 "a135_HW_BMB_Diagnostics_Failure" 134 "a134_SW_Delayed_Ctr_Off" 133 "a133_IO_CAN_Bus_Off" 132 "a132_HW_BMB_OTP_Uncorrctbl" 131 "a131_Bleed_FET_Failure" 130 "a130_IO_CAN_Error" 129 "a129_SW_VSH_Failure" 128 "a128_SW_shunt_MIA" 127 "a127_SW_shunt_SNA" 126 "a126_SW_Thermistor_Failure" 124 "a124_Battery_Coolant_Flood" 123 "a123_SW_Internal_Isolation" 122 "a122_SW_BMS_Therm_Irrational" 121 "a121_SW_NVRAM_Config_Error" 119 "a119_Fast_Open_Vsh_Detected" 117 "a117_SW_Delta_SOC_Weak_Short" 115 "a115_Energy_Rubberbanding_Reset" 112 "a112_LifeModel_Discontinuity" 111 "a111_LifeModel_Spread_Change" 110 "a110_LifeModel_AvgOffset_Change" 109 "a109_HW_BMB_Mute_Status_Mismatch" 108 "a108_SW_BMB_Device_OT" 107 "a107_SW_Stack_Voltage_MIA" 106 "a106_SW_All_Module_Tsense" 105 "a105_SW_One_Module_Tsense" 100 "a100_ThermalEventSuspected" 99 "a099_SW_BMB_Communication" 98 "a098_SW_BMB_Data_Integrity_Loss" 97 "a097_SW_BMB_Over_CAN_Communication" 95 "a095_SW_UI_MIA" 94 "a094_SW_Drive_Inverter_MIA" 92 "a092_SW_ChargePort_Mia_On_Hvs" 91 "a091_SW_ChargePort_MIA" 90 "a090_SW_Gateway_MIA" 89 "a089_SW_VcFront_MIA" 88 "a088_SW_VcFront_MIA_InDrive" 87 "a087_SW_Feim_Test_Blocked" 86 "a086_SW_FC_Contactor_Mismatch" 85 "a085_SW_Pack_Contactor_Mismatch" 84 "a084_SW_Sleep_Wake_Aborted" 83 "a083_SW_Ctr_Close_Failure" 82 "a082_SW_Ctr_Force_Open" 81 "a081_SW_Ctr_Close_Blocked" 80 "a080_SW_Pack_Ctr_Impedance" 79 "a079_Max_Charge_Level_Exceeded" 78 "a078_Rapid_Dch_While_Charging" 77 "a077_SW_Charger_Regulation" 76 "a076_SW_Dch_While_Charging" 75 "a075_SW_Chg_Disable_Failure" 74 "a074_Max_Charge_Level_Reduced" 73 "a073_Unexpected_Loss_Of_Lv" 72 "a072_Module_Brick_Split" 71 "a071_SW_SM_TransCon_Not_Met" 70 "a070_BrickV_Imbalance_Limiting" 69 "a069_SW_Low_Power" 68 "a068_CAC_Imbalance_Limp" 67 "a067_CAC_Imbalance_Limiting" 66 "a066_SOC_Imbalance_Warning" 65 "a065_SW_CAC_Imbalance" 64 "a064_SW_SOC_Imbalance" 63 "a063_SW_ChargePort_Fault" 62 "a062_SW_BrickV_Imbalance" 61 "a061_SW_BrickV_Change" 60 "a060_SW_Leakage_Test_Failure" 59 "a059_SW_Pack_Voltage_Sensing" 58 "a058_SW_Bandolier_Model_Reset" 57 "a057_SW_Bandolier_Model_Warning" 56 "a056_SW_Standby_Supply_Fault" 55 "a055_SW_HvChain_Model_Fault" 54 "a054_SW_Ver_Supply_Fault" 52 "a052_SW_PCS_MIA" 51 "a051_SW_HVC_Vref_Bad" 50 "a050_SW_Brick_Voltage_MIA" 49 "a049_SW_Thermal_Event" 48 "a048_SW_Watch_Dog_Warning" 47 "a047_SW_Task_Stack_Overflow" 46 "a046_SW_Task_Stack_Usage" 45 "a045_SW_Exception" 44 "a044_SW_Assertion" 43 "a043_SW_Watch_Dog_Reset" 42 "a042_SW_MPU_Error" 41 "a041_SW_Destructive_Reset_Source" 40 "a040_SW_Watch_Dog_HW_Triggered" 39 "a039_SW_DC_Link_Over_Voltage" 37 "a037_SW_Flood_Port_Open" 36 "a036_SW_HvpHvilFault" 35 "a035_SW_Isolation" 34 "a034_SW_Passive_Isolation" 33 "a033_VoltageDeviation" 32 "a032_VoltageLoss" 31 "a031_AlertsSetDuringSleep" 30 "a030_Impedance_Deviation" 29 "a029_dSoc_Limiting" 28 "a028_ShuntAsicCurrentOffsetDeviation" 27 "a027_SW_Repeated_Isolation_Failure_In_Drive" 26 "a026_SW_HFCurrent_Anomaly" 25 "a025_SW_PwrBalance_Anomaly" 24 "a024_SW_Islanded_Brick" 23 "a023_SW_Stack_OV" 22 "a022_SW_Over_Current" 21 "a021_SW_Dr_Limits_Regulation" 20 "a020_SW_Brick_Instability" 19 "a019_SW_Module_OT" 18 "a018_SW_Brick_UV" 17 "a017_SW_Brick_OV" 16 "a016_Pack_Module_Id_Mismatch" 7 "a007_SW_Slowed_Chg_Batt_Cold" 4 "a004_Cal_Vs_Serial_Birth_Date_Mismatch" 3 "a003_SW_Pack_Birth_Date_Missing" 2 "a002_Pack_Performance_Config_Mismatch" 1 "a001_Pack_Config_Mismatch" 0 "ALERT_DO_NOT_USE_ZERO" ;
VAL_ 1343 BMS_a081_fourthBlockingAlertId 188 "a188_DtcConfirmed" 187 "a187_RippleHeatingEmergencyShutdown" 186 "a186_RippleHeatingChargeFault" 185 "a185_LifeModel_CyclingDcrGrowth_Change" 184 "a184_LifeModel_CyclingLoss_Change" 183 "a183_LifeModel_StoDcrGrowth_Change" 182 "a182_LifeModel_NoCurrentLoss_Change" 181 "a181_SW_Shunt_Over_Temperature" 180 "a180_SW_ECU_reset_blocked" 179 "a179_HvpGpoRequestActive" 178 "a178_SW_Uncontrolled_Regen_PwrB" 177 "a177_SW_Energy_Buffer_Size" 176 "a176_SW_GracefulPowerOff" 175 "a175_Charge_Failure_External" 174 "a174_SW_Charge_Failure" 172 "a172_SW_Isolation_Failure_In_Drive_Warning" 171 "a171_SW_Stack_Voltage_Sense" 170 "a170_SW_Limp_Mode" 169 "a169_SW_FC_Pack_Weld" 168 "a168_SW_FC_Full_Weld" 167 "a167_SW_FC_Partial_Weld" 166 "a166_SW_Pack_Full_Weld" 165 "a165_SW_Pack_Partial_Weld" 164 "a164_SW_Uncontrolled_Regen" 162 "a162_SW_No_Power_For_Support" 161 "a161_SW_BMB_Vref_warning" 160 "a160_SW_FC_Ctr_Clean_Failed" 159 "a159_SW_HVP_ECU_Error" 158 "a158_SW_HVP_HVI_Comms" 157 "a157_SW_Hist_Update_Missed" 156 "a156_SW_BMB_Vref_bad" 155 "a155_SW_Weak_short_impedence" 154 "a154_SW_Brick_OV_Warning_Stop_Charge" 152 "a152_Isolation_In_Dc_Charge" 151 "a151_SW_external_isolation" 150 "a150_SW_Missing_Part_Number" 149 "a149_SW_Missing_Config_Block" 148 "a148_SW_Unsupported_BMB_ASIC_Type" 147 "a147_SW_SOC_High_Ah_Error" 146 "a146_SW_Brick_Overdischarged" 145 "a145_SW_SOC_Change" 144 "a144_Hvp_Config_Mismatch" 143 "a143_SW_CAC_Change" 142 "a142_SW_Isolation_Degradation" 141 "a141_SW_BMB_Status_Warning" 140 "a140_HW_BMB_Status_Fault" 139 "a139_SW_DC_Link_V_Irrational" 138 "a138_SW_Brick_OV_Warning" 137 "a137_SW_Brick_UV_Warning" 136 "a136_SW_Module_OT_Warning" 135 "a135_HW_BMB_Diagnostics_Failure" 134 "a134_SW_Delayed_Ctr_Off" 133 "a133_IO_CAN_Bus_Off" 132 "a132_HW_BMB_OTP_Uncorrctbl" 131 "a131_Bleed_FET_Failure" 130 "a130_IO_CAN_Error" 129 "a129_SW_VSH_Failure" 128 "a128_SW_shunt_MIA" 127 "a127_SW_shunt_SNA" 126 "a126_SW_Thermistor_Failure" 124 "a124_Battery_Coolant_Flood" 123 "a123_SW_Internal_Isolation" 122 "a122_SW_BMS_Therm_Irrational" 121 "a121_SW_NVRAM_Config_Error" 119 "a119_Fast_Open_Vsh_Detected" 117 "a117_SW_Delta_SOC_Weak_Short" 115 "a115_Energy_Rubberbanding_Reset" 112 "a112_LifeModel_Discontinuity" 111 "a111_LifeModel_Spread_Change" 110 "a110_LifeModel_AvgOffset_Change" 109 "a109_HW_BMB_Mute_Status_Mismatch" 108 "a108_SW_BMB_Device_OT" 107 "a107_SW_Stack_Voltage_MIA" 106 "a106_SW_All_Module_Tsense" 105 "a105_SW_One_Module_Tsense" 100 "a100_ThermalEventSuspected" 99 "a099_SW_BMB_Communication" 98 "a098_SW_BMB_Data_Integrity_Loss" 97 "a097_SW_BMB_Over_CAN_Communication" 95 "a095_SW_UI_MIA" 94 "a094_SW_Drive_Inverter_MIA" 92 "a092_SW_ChargePort_Mia_On_Hvs" 91 "a091_SW_ChargePort_MIA" 90 "a090_SW_Gateway_MIA" 89 "a089_SW_VcFront_MIA" 88 "a088_SW_VcFront_MIA_InDrive" 87 "a087_SW_Feim_Test_Blocked" 86 "a086_SW_FC_Contactor_Mismatch" 85 "a085_SW_Pack_Contactor_Mismatch" 84 "a084_SW_Sleep_Wake_Aborted" 83 "a083_SW_Ctr_Close_Failure" 82 "a082_SW_Ctr_Force_Open" 81 "a081_SW_Ctr_Close_Blocked" 80 "a080_SW_Pack_Ctr_Impedance" 79 "a079_Max_Charge_Level_Exceeded" 78 "a078_Rapid_Dch_While_Charging" 77 "a077_SW_Charger_Regulation" 76 "a076_SW_Dch_While_Charging" 75 "a075_SW_Chg_Disable_Failure" 74 "a074_Max_Charge_Level_Reduced" 73 "a073_Unexpected_Loss_Of_Lv" 72 "a072_Module_Brick_Split" 71 "a071_SW_SM_TransCon_Not_Met" 70 "a070_BrickV_Imbalance_Limiting" 69 "a069_SW_Low_Power" 68 "a068_CAC_Imbalance_Limp" 67 "a067_CAC_Imbalance_Limiting" 66 "a066_SOC_Imbalance_Warning" 65 "a065_SW_CAC_Imbalance" 64 "a064_SW_SOC_Imbalance" 63 "a063_SW_ChargePort_Fault" 62 "a062_SW_BrickV_Imbalance" 61 "a061_SW_BrickV_Change" 60 "a060_SW_Leakage_Test_Failure" 59 "a059_SW_Pack_Voltage_Sensing" 58 "a058_SW_Bandolier_Model_Reset" 57 "a057_SW_Bandolier_Model_Warning" 56 "a056_SW_Standby_Supply_Fault" 55 "a055_SW_HvChain_Model_Fault" 54 "a054_SW_Ver_Supply_Fault" 52 "a052_SW_PCS_MIA" 51 "a051_SW_HVC_Vref_Bad" 50 "a050_SW_Brick_Voltage_MIA" 49 "a049_SW_Thermal_Event" 48 "a048_SW_Watch_Dog_Warning" 47 "a047_SW_Task_Stack_Overflow" 46 "a046_SW_Task_Stack_Usage" 45 "a045_SW_Exception" 44 "a044_SW_Assertion" 43 "a043_SW_Watch_Dog_Reset" 42 "a042_SW_MPU_Error" 41 "a041_SW_Destructive_Reset_Source" 40 "a040_SW_Watch_Dog_HW_Triggered" 39 "a039_SW_DC_Link_Over_Voltage" 37 "a037_SW_Flood_Port_Open" 36 "a036_SW_HvpHvilFault" 35 "a035_SW_Isolation" 34 "a034_SW_Passive_Isolation" 33 "a033_VoltageDeviation" 32 "a032_VoltageLoss" 31 "a031_AlertsSetDuringSleep" 30 "a030_Impedance_Deviation" 29 "a029_dSoc_Limiting" 28 "a028_ShuntAsicCurrentOffsetDeviation" 27 "a027_SW_Repeated_Isolation_Failure_In_Drive" 26 "a026_SW_HFCurrent_Anomaly" 25 "a025_SW_PwrBalance_Anomaly" 24 "a024_SW_Islanded_Brick" 23 "a023_SW_Stack_OV" 22 "a022_SW_Over_Current" 21 "a021_SW_Dr_Limits_Regulation" 20 "a020_SW_Brick_Instability" 19 "a019_SW_Module_OT" 18 "a018_SW_Brick_UV" 17 "a017_SW_Brick_OV" 16 "a016_Pack_Module_Id_Mismatch" 7 "a007_SW_Slowed_Chg_Batt_Cold" 4 "a004_Cal_Vs_Serial_Birth_Date_Mismatch" 3 "a003_SW_Pack_Birth_Date_Missing" 2 "a002_Pack_Performance_Config_Mismatch" 1 "a001_Pack_Config_Mismatch" 0 "ALERT_DO_NOT_USE_ZERO" ;
VAL_ 1343 BMS_a082_stateRequest 10 "DIAG" 9 "SNA" 8 "TEST" 7 "WELD" 6 "FAULT" 5 "CLEAR_FAULT" 4 "FEIM" 3 "CHARGE" 2 "SUPPORT" 1 "DRIVE" 0 "STANDBY" ;
VAL_ 1343 BMS_a082_firstAlertId 188 "a188_DtcConfirmed" 187 "a187_RippleHeatingEmergencyShutdown" 186 "a186_RippleHeatingChargeFault" 185 "a185_LifeModel_CyclingDcrGrowth_Change" 184 "a184_LifeModel_CyclingLoss_Change" 183 "a183_LifeModel_StoDcrGrowth_Change" 182 "a182_LifeModel_NoCurrentLoss_Change" 181 "a181_SW_Shunt_Over_Temperature" 180 "a180_SW_ECU_reset_blocked" 179 "a179_HvpGpoRequestActive" 178 "a178_SW_Uncontrolled_Regen_PwrB" 177 "a177_SW_Energy_Buffer_Size" 176 "a176_SW_GracefulPowerOff" 175 "a175_Charge_Failure_External" 174 "a174_SW_Charge_Failure" 172 "a172_SW_Isolation_Failure_In_Drive_Warning" 171 "a171_SW_Stack_Voltage_Sense" 170 "a170_SW_Limp_Mode" 169 "a169_SW_FC_Pack_Weld" 168 "a168_SW_FC_Full_Weld" 167 "a167_SW_FC_Partial_Weld" 166 "a166_SW_Pack_Full_Weld" 165 "a165_SW_Pack_Partial_Weld" 164 "a164_SW_Uncontrolled_Regen" 162 "a162_SW_No_Power_For_Support" 161 "a161_SW_BMB_Vref_warning" 160 "a160_SW_FC_Ctr_Clean_Failed" 159 "a159_SW_HVP_ECU_Error" 158 "a158_SW_HVP_HVI_Comms" 157 "a157_SW_Hist_Update_Missed" 156 "a156_SW_BMB_Vref_bad" 155 "a155_SW_Weak_short_impedence" 154 "a154_SW_Brick_OV_Warning_Stop_Charge" 152 "a152_Isolation_In_Dc_Charge" 151 "a151_SW_external_isolation" 150 "a150_SW_Missing_Part_Number" 149 "a149_SW_Missing_Config_Block" 148 "a148_SW_Unsupported_BMB_ASIC_Type" 147 "a147_SW_SOC_High_Ah_Error" 146 "a146_SW_Brick_Overdischarged" 145 "a145_SW_SOC_Change" 144 "a144_Hvp_Config_Mismatch" 143 "a143_SW_CAC_Change" 142 "a142_SW_Isolation_Degradation" 141 "a141_SW_BMB_Status_Warning" 140 "a140_HW_BMB_Status_Fault" 139 "a139_SW_DC_Link_V_Irrational" 138 "a138_SW_Brick_OV_Warning" 137 "a137_SW_Brick_UV_Warning" 136 "a136_SW_Module_OT_Warning" 135 "a135_HW_BMB_Diagnostics_Failure" 134 "a134_SW_Delayed_Ctr_Off" 133 "a133_IO_CAN_Bus_Off" 132 "a132_HW_BMB_OTP_Uncorrctbl" 131 "a131_Bleed_FET_Failure" 130 "a130_IO_CAN_Error" 129 "a129_SW_VSH_Failure" 128 "a128_SW_shunt_MIA" 127 "a127_SW_shunt_SNA" 126 "a126_SW_Thermistor_Failure" 124 "a124_Battery_Coolant_Flood" 123 "a123_SW_Internal_Isolation" 122 "a122_SW_BMS_Therm_Irrational" 121 "a121_SW_NVRAM_Config_Error" 119 "a119_Fast_Open_Vsh_Detected" 117 "a117_SW_Delta_SOC_Weak_Short" 115 "a115_Energy_Rubberbanding_Reset" 112 "a112_LifeModel_Discontinuity" 111 "a111_LifeModel_Spread_Change" 110 "a110_LifeModel_AvgOffset_Change" 109 "a109_HW_BMB_Mute_Status_Mismatch" 108 "a108_SW_BMB_Device_OT" 107 "a107_SW_Stack_Voltage_MIA" 106 "a106_SW_All_Module_Tsense" 105 "a105_SW_One_Module_Tsense" 100 "a100_ThermalEventSuspected" 99 "a099_SW_BMB_Communication" 98 "a098_SW_BMB_Data_Integrity_Loss" 97 "a097_SW_BMB_Over_CAN_Communication" 95 "a095_SW_UI_MIA" 94 "a094_SW_Drive_Inverter_MIA" 92 "a092_SW_ChargePort_Mia_On_Hvs" 91 "a091_SW_ChargePort_MIA" 90 "a090_SW_Gateway_MIA" 89 "a089_SW_VcFront_MIA" 88 "a088_SW_VcFront_MIA_InDrive" 87 "a087_SW_Feim_Test_Blocked" 86 "a086_SW_FC_Contactor_Mismatch" 85 "a085_SW_Pack_Contactor_Mismatch" 84 "a084_SW_Sleep_Wake_Aborted" 83 "a083_SW_Ctr_Close_Failure" 82 "a082_SW_Ctr_Force_Open" 81 "a081_SW_Ctr_Close_Blocked" 80 "a080_SW_Pack_Ctr_Impedance" 79 "a079_Max_Charge_Level_Exceeded" 78 "a078_Rapid_Dch_While_Charging" 77 "a077_SW_Charger_Regulation" 76 "a076_SW_Dch_While_Charging" 75 "a075_SW_Chg_Disable_Failure" 74 "a074_Max_Charge_Level_Reduced" 73 "a073_Unexpected_Loss_Of_Lv" 72 "a072_Module_Brick_Split" 71 "a071_SW_SM_TransCon_Not_Met" 70 "a070_BrickV_Imbalance_Limiting" 69 "a069_SW_Low_Power" 68 "a068_CAC_Imbalance_Limp" 67 "a067_CAC_Imbalance_Limiting" 66 "a066_SOC_Imbalance_Warning" 65 "a065_SW_CAC_Imbalance" 64 "a064_SW_SOC_Imbalance" 63 "a063_SW_ChargePort_Fault" 62 "a062_SW_BrickV_Imbalance" 61 "a061_SW_BrickV_Change" 60 "a060_SW_Leakage_Test_Failure" 59 "a059_SW_Pack_Voltage_Sensing" 58 "a058_SW_Bandolier_Model_Reset" 57 "a057_SW_Bandolier_Model_Warning" 56 "a056_SW_Standby_Supply_Fault" 55 "a055_SW_HvChain_Model_Fault" 54 "a054_SW_Ver_Supply_Fault" 52 "a052_SW_PCS_MIA" 51 "a051_SW_HVC_Vref_Bad" 50 "a050_SW_Brick_Voltage_MIA" 49 "a049_SW_Thermal_Event" 48 "a048_SW_Watch_Dog_Warning" 47 "a047_SW_Task_Stack_Overflow" 46 "a046_SW_Task_Stack_Usage" 45 "a045_SW_Exception" 44 "a044_SW_Assertion" 43 "a043_SW_Watch_Dog_Reset" 42 "a042_SW_MPU_Error" 41 "a041_SW_Destructive_Reset_Source" 40 "a040_SW_Watch_Dog_HW_Triggered" 39 "a039_SW_DC_Link_Over_Voltage" 37 "a037_SW_Flood_Port_Open" 36 "a036_SW_HvpHvilFault" 35 "a035_SW_Isolation" 34 "a034_SW_Passive_Isolation" 33 "a033_VoltageDeviation" 32 "a032_VoltageLoss" 31 "a031_AlertsSetDuringSleep" 30 "a030_Impedance_Deviation" 29 "a029_dSoc_Limiting" 28 "a028_ShuntAsicCurrentOffsetDeviation" 27 "a027_SW_Repeated_Isolation_Failure_In_Drive" 26 "a026_SW_HFCurrent_Anomaly" 25 "a025_SW_PwrBalance_Anomaly" 24 "a024_SW_Islanded_Brick" 23 "a023_SW_Stack_OV" 22 "a022_SW_Over_Current" 21 "a021_SW_Dr_Limits_Regulation" 20 "a020_SW_Brick_Instability" 19 "a019_SW_Module_OT" 18 "a018_SW_Brick_UV" 17 "a017_SW_Brick_OV" 16 "a016_Pack_Module_Id_Mismatch" 7 "a007_SW_Slowed_Chg_Batt_Cold" 4 "a004_Cal_Vs_Serial_Birth_Date_Mismatch" 3 "a003_SW_Pack_Birth_Date_Missing" 2 "a002_Pack_Performance_Config_Mismatch" 1 "a001_Pack_Config_Mismatch" 0 "ALERT_DO_NOT_USE_ZERO" ;
VAL_ 1343 BMS_a082_secondAlertId 188 "a188_DtcConfirmed" 187 "a187_RippleHeatingEmergencyShutdown" 186 "a186_RippleHeatingChargeFault" 185 "a185_LifeModel_CyclingDcrGrowth_Change" 184 "a184_LifeModel_CyclingLoss_Change" 183 "a183_LifeModel_StoDcrGrowth_Change" 182 "a182_LifeModel_NoCurrentLoss_Change" 181 "a181_SW_Shunt_Over_Temperature" 180 "a180_SW_ECU_reset_blocked" 179 "a179_HvpGpoRequestActive" 178 "a178_SW_Uncontrolled_Regen_PwrB" 177 "a177_SW_Energy_Buffer_Size" 176 "a176_SW_GracefulPowerOff" 175 "a175_Charge_Failure_External" 174 "a174_SW_Charge_Failure" 172 "a172_SW_Isolation_Failure_In_Drive_Warning" 171 "a171_SW_Stack_Voltage_Sense" 170 "a170_SW_Limp_Mode" 169 "a169_SW_FC_Pack_Weld" 168 "a168_SW_FC_Full_Weld" 167 "a167_SW_FC_Partial_Weld" 166 "a166_SW_Pack_Full_Weld" 165 "a165_SW_Pack_Partial_Weld" 164 "a164_SW_Uncontrolled_Regen" 162 "a162_SW_No_Power_For_Support" 161 "a161_SW_BMB_Vref_warning" 160 "a160_SW_FC_Ctr_Clean_Failed" 159 "a159_SW_HVP_ECU_Error" 158 "a158_SW_HVP_HVI_Comms" 157 "a157_SW_Hist_Update_Missed" 156 "a156_SW_BMB_Vref_bad" 155 "a155_SW_Weak_short_impedence" 154 "a154_SW_Brick_OV_Warning_Stop_Charge" 152 "a152_Isolation_In_Dc_Charge" 151 "a151_SW_external_isolation" 150 "a150_SW_Missing_Part_Number" 149 "a149_SW_Missing_Config_Block" 148 "a148_SW_Unsupported_BMB_ASIC_Type" 147 "a147_SW_SOC_High_Ah_Error" 146 "a146_SW_Brick_Overdischarged" 145 "a145_SW_SOC_Change" 144 "a144_Hvp_Config_Mismatch" 143 "a143_SW_CAC_Change" 142 "a142_SW_Isolation_Degradation" 141 "a141_SW_BMB_Status_Warning" 140 "a140_HW_BMB_Status_Fault" 139 "a139_SW_DC_Link_V_Irrational" 138 "a138_SW_Brick_OV_Warning" 137 "a137_SW_Brick_UV_Warning" 136 "a136_SW_Module_OT_Warning" 135 "a135_HW_BMB_Diagnostics_Failure" 134 "a134_SW_Delayed_Ctr_Off" 133 "a133_IO_CAN_Bus_Off" 132 "a132_HW_BMB_OTP_Uncorrctbl" 131 "a131_Bleed_FET_Failure" 130 "a130_IO_CAN_Error" 129 "a129_SW_VSH_Failure" 128 "a128_SW_shunt_MIA" 127 "a127_SW_shunt_SNA" 126 "a126_SW_Thermistor_Failure" 124 "a124_Battery_Coolant_Flood" 123 "a123_SW_Internal_Isolation" 122 "a122_SW_BMS_Therm_Irrational" 121 "a121_SW_NVRAM_Config_Error" 119 "a119_Fast_Open_Vsh_Detected" 117 "a117_SW_Delta_SOC_Weak_Short" 115 "a115_Energy_Rubberbanding_Reset" 112 "a112_LifeModel_Discontinuity" 111 "a111_LifeModel_Spread_Change" 110 "a110_LifeModel_AvgOffset_Change" 109 "a109_HW_BMB_Mute_Status_Mismatch" 108 "a108_SW_BMB_Device_OT" 107 "a107_SW_Stack_Voltage_MIA" 106 "a106_SW_All_Module_Tsense" 105 "a105_SW_One_Module_Tsense" 100 "a100_ThermalEventSuspected" 99 "a099_SW_BMB_Communication" 98 "a098_SW_BMB_Data_Integrity_Loss" 97 "a097_SW_BMB_Over_CAN_Communication" 95 "a095_SW_UI_MIA" 94 "a094_SW_Drive_Inverter_MIA" 92 "a092_SW_ChargePort_Mia_On_Hvs" 91 "a091_SW_ChargePort_MIA" 90 "a090_SW_Gateway_MIA" 89 "a089_SW_VcFront_MIA" 88 "a088_SW_VcFront_MIA_InDrive" 87 "a087_SW_Feim_Test_Blocked" 86 "a086_SW_FC_Contactor_Mismatch" 85 "a085_SW_Pack_Contactor_Mismatch" 84 "a084_SW_Sleep_Wake_Aborted" 83 "a083_SW_Ctr_Close_Failure" 82 "a082_SW_Ctr_Force_Open" 81 "a081_SW_Ctr_Close_Blocked" 80 "a080_SW_Pack_Ctr_Impedance" 79 "a079_Max_Charge_Level_Exceeded" 78 "a078_Rapid_Dch_While_Charging" 77 "a077_SW_Charger_Regulation" 76 "a076_SW_Dch_While_Charging" 75 "a075_SW_Chg_Disable_Failure" 74 "a074_Max_Charge_Level_Reduced" 73 "a073_Unexpected_Loss_Of_Lv" 72 "a072_Module_Brick_Split" 71 "a071_SW_SM_TransCon_Not_Met" 70 "a070_BrickV_Imbalance_Limiting" 69 "a069_SW_Low_Power" 68 "a068_CAC_Imbalance_Limp" 67 "a067_CAC_Imbalance_Limiting" 66 "a066_SOC_Imbalance_Warning" 65 "a065_SW_CAC_Imbalance" 64 "a064_SW_SOC_Imbalance" 63 "a063_SW_ChargePort_Fault" 62 "a062_SW_BrickV_Imbalance" 61 "a061_SW_BrickV_Change" 60 "a060_SW_Leakage_Test_Failure" 59 "a059_SW_Pack_Voltage_Sensing" 58 "a058_SW_Bandolier_Model_Reset" 57 "a057_SW_Bandolier_Model_Warning" 56 "a056_SW_Standby_Supply_Fault" 55 "a055_SW_HvChain_Model_Fault" 54 "a054_SW_Ver_Supply_Fault" 52 "a052_SW_PCS_MIA" 51 "a051_SW_HVC_Vref_Bad" 50 "a050_SW_Brick_Voltage_MIA" 49 "a049_SW_Thermal_Event" 48 "a048_SW_Watch_Dog_Warning" 47 "a047_SW_Task_Stack_Overflow" 46 "a046_SW_Task_Stack_Usage" 45 "a045_SW_Exception" 44 "a044_SW_Assertion" 43 "a043_SW_Watch_Dog_Reset" 42 "a042_SW_MPU_Error" 41 "a041_SW_Destructive_Reset_Source" 40 "a040_SW_Watch_Dog_HW_Triggered" 39 "a039_SW_DC_Link_Over_Voltage" 37 "a037_SW_Flood_Port_Open" 36 "a036_SW_HvpHvilFault" 35 "a035_SW_Isolation" 34 "a034_SW_Passive_Isolation" 33 "a033_VoltageDeviation" 32 "a032_VoltageLoss" 31 "a031_AlertsSetDuringSleep" 30 "a030_Impedance_Deviation" 29 "a029_dSoc_Limiting" 28 "a028_ShuntAsicCurrentOffsetDeviation" 27 "a027_SW_Repeated_Isolation_Failure_In_Drive" 26 "a026_SW_HFCurrent_Anomaly" 25 "a025_SW_PwrBalance_Anomaly" 24 "a024_SW_Islanded_Brick" 23 "a023_SW_Stack_OV" 22 "a022_SW_Over_Current" 21 "a021_SW_Dr_Limits_Regulation" 20 "a020_SW_Brick_Instability" 19 "a019_SW_Module_OT" 18 "a018_SW_Brick_UV" 17 "a017_SW_Brick_OV" 16 "a016_Pack_Module_Id_Mismatch" 7 "a007_SW_Slowed_Chg_Batt_Cold" 4 "a004_Cal_Vs_Serial_Birth_Date_Mismatch" 3 "a003_SW_Pack_Birth_Date_Missing" 2 "a002_Pack_Performance_Config_Mismatch" 1 "a001_Pack_Config_Mismatch" 0 "ALERT_DO_NOT_USE_ZERO" ;
VAL_ 1343 BMS_a082_thirdAlertId 188 "a188_DtcConfirmed" 187 "a187_RippleHeatingEmergencyShutdown" 186 "a186_RippleHeatingChargeFault" 185 "a185_LifeModel_CyclingDcrGrowth_Change" 184 "a184_LifeModel_CyclingLoss_Change" 183 "a183_LifeModel_StoDcrGrowth_Change" 182 "a182_LifeModel_NoCurrentLoss_Change" 181 "a181_SW_Shunt_Over_Temperature" 180 "a180_SW_ECU_reset_blocked" 179 "a179_HvpGpoRequestActive" 178 "a178_SW_Uncontrolled_Regen_PwrB" 177 "a177_SW_Energy_Buffer_Size" 176 "a176_SW_GracefulPowerOff" 175 "a175_Charge_Failure_External" 174 "a174_SW_Charge_Failure" 172 "a172_SW_Isolation_Failure_In_Drive_Warning" 171 "a171_SW_Stack_Voltage_Sense" 170 "a170_SW_Limp_Mode" 169 "a169_SW_FC_Pack_Weld" 168 "a168_SW_FC_Full_Weld" 167 "a167_SW_FC_Partial_Weld" 166 "a166_SW_Pack_Full_Weld" 165 "a165_SW_Pack_Partial_Weld" 164 "a164_SW_Uncontrolled_Regen" 162 "a162_SW_No_Power_For_Support" 161 "a161_SW_BMB_Vref_warning" 160 "a160_SW_FC_Ctr_Clean_Failed" 159 "a159_SW_HVP_ECU_Error" 158 "a158_SW_HVP_HVI_Comms" 157 "a157_SW_Hist_Update_Missed" 156 "a156_SW_BMB_Vref_bad" 155 "a155_SW_Weak_short_impedence" 154 "a154_SW_Brick_OV_Warning_Stop_Charge" 152 "a152_Isolation_In_Dc_Charge" 151 "a151_SW_external_isolation" 150 "a150_SW_Missing_Part_Number" 149 "a149_SW_Missing_Config_Block" 148 "a148_SW_Unsupported_BMB_ASIC_Type" 147 "a147_SW_SOC_High_Ah_Error" 146 "a146_SW_Brick_Overdischarged" 145 "a145_SW_SOC_Change" 144 "a144_Hvp_Config_Mismatch" 143 "a143_SW_CAC_Change" 142 "a142_SW_Isolation_Degradation" 141 "a141_SW_BMB_Status_Warning" 140 "a140_HW_BMB_Status_Fault" 139 "a139_SW_DC_Link_V_Irrational" 138 "a138_SW_Brick_OV_Warning" 137 "a137_SW_Brick_UV_Warning" 136 "a136_SW_Module_OT_Warning" 135 "a135_HW_BMB_Diagnostics_Failure" 134 "a134_SW_Delayed_Ctr_Off" 133 "a133_IO_CAN_Bus_Off" 132 "a132_HW_BMB_OTP_Uncorrctbl" 131 "a131_Bleed_FET_Failure" 130 "a130_IO_CAN_Error" 129 "a129_SW_VSH_Failure" 128 "a128_SW_shunt_MIA" 127 "a127_SW_shunt_SNA" 126 "a126_SW_Thermistor_Failure" 124 "a124_Battery_Coolant_Flood" 123 "a123_SW_Internal_Isolation" 122 "a122_SW_BMS_Therm_Irrational" 121 "a121_SW_NVRAM_Config_Error" 119 "a119_Fast_Open_Vsh_Detected" 117 "a117_SW_Delta_SOC_Weak_Short" 115 "a115_Energy_Rubberbanding_Reset" 112 "a112_LifeModel_Discontinuity" 111 "a111_LifeModel_Spread_Change" 110 "a110_LifeModel_AvgOffset_Change" 109 "a109_HW_BMB_Mute_Status_Mismatch" 108 "a108_SW_BMB_Device_OT" 107 "a107_SW_Stack_Voltage_MIA" 106 "a106_SW_All_Module_Tsense" 105 "a105_SW_One_Module_Tsense" 100 "a100_ThermalEventSuspected" 99 "a099_SW_BMB_Communication" 98 "a098_SW_BMB_Data_Integrity_Loss" 97 "a097_SW_BMB_Over_CAN_Communication" 95 "a095_SW_UI_MIA" 94 "a094_SW_Drive_Inverter_MIA" 92 "a092_SW_ChargePort_Mia_On_Hvs" 91 "a091_SW_ChargePort_MIA" 90 "a090_SW_Gateway_MIA" 89 "a089_SW_VcFront_MIA" 88 "a088_SW_VcFront_MIA_InDrive" 87 "a087_SW_Feim_Test_Blocked" 86 "a086_SW_FC_Contactor_Mismatch" 85 "a085_SW_Pack_Contactor_Mismatch" 84 "a084_SW_Sleep_Wake_Aborted" 83 "a083_SW_Ctr_Close_Failure" 82 "a082_SW_Ctr_Force_Open" 81 "a081_SW_Ctr_Close_Blocked" 80 "a080_SW_Pack_Ctr_Impedance" 79 "a079_Max_Charge_Level_Exceeded" 78 "a078_Rapid_Dch_While_Charging" 77 "a077_SW_Charger_Regulation" 76 "a076_SW_Dch_While_Charging" 75 "a075_SW_Chg_Disable_Failure" 74 "a074_Max_Charge_Level_Reduced" 73 "a073_Unexpected_Loss_Of_Lv" 72 "a072_Module_Brick_Split" 71 "a071_SW_SM_TransCon_Not_Met" 70 "a070_BrickV_Imbalance_Limiting" 69 "a069_SW_Low_Power" 68 "a068_CAC_Imbalance_Limp" 67 "a067_CAC_Imbalance_Limiting" 66 "a066_SOC_Imbalance_Warning" 65 "a065_SW_CAC_Imbalance" 64 "a064_SW_SOC_Imbalance" 63 "a063_SW_ChargePort_Fault" 62 "a062_SW_BrickV_Imbalance" 61 "a061_SW_BrickV_Change" 60 "a060_SW_Leakage_Test_Failure" 59 "a059_SW_Pack_Voltage_Sensing" 58 "a058_SW_Bandolier_Model_Reset" 57 "a057_SW_Bandolier_Model_Warning" 56 "a056_SW_Standby_Supply_Fault" 55 "a055_SW_HvChain_Model_Fault" 54 "a054_SW_Ver_Supply_Fault" 52 "a052_SW_PCS_MIA" 51 "a051_SW_HVC_Vref_Bad" 50 "a050_SW_Brick_Voltage_MIA" 49 "a049_SW_Thermal_Event" 48 "a048_SW_Watch_Dog_Warning" 47 "a047_SW_Task_Stack_Overflow" 46 "a046_SW_Task_Stack_Usage" 45 "a045_SW_Exception" 44 "a044_SW_Assertion" 43 "a043_SW_Watch_Dog_Reset" 42 "a042_SW_MPU_Error" 41 "a041_SW_Destructive_Reset_Source" 40 "a040_SW_Watch_Dog_HW_Triggered" 39 "a039_SW_DC_Link_Over_Voltage" 37 "a037_SW_Flood_Port_Open" 36 "a036_SW_HvpHvilFault" 35 "a035_SW_Isolation" 34 "a034_SW_Passive_Isolation" 33 "a033_VoltageDeviation" 32 "a032_VoltageLoss" 31 "a031_AlertsSetDuringSleep" 30 "a030_Impedance_Deviation" 29 "a029_dSoc_Limiting" 28 "a028_ShuntAsicCurrentOffsetDeviation" 27 "a027_SW_Repeated_Isolation_Failure_In_Drive" 26 "a026_SW_HFCurrent_Anomaly" 25 "a025_SW_PwrBalance_Anomaly" 24 "a024_SW_Islanded_Brick" 23 "a023_SW_Stack_OV" 22 "a022_SW_Over_Current" 21 "a021_SW_Dr_Limits_Regulation" 20 "a020_SW_Brick_Instability" 19 "a019_SW_Module_OT" 18 "a018_SW_Brick_UV" 17 "a017_SW_Brick_OV" 16 "a016_Pack_Module_Id_Mismatch" 7 "a007_SW_Slowed_Chg_Batt_Cold" 4 "a004_Cal_Vs_Serial_Birth_Date_Mismatch" 3 "a003_SW_Pack_Birth_Date_Missing" 2 "a002_Pack_Performance_Config_Mismatch" 1 "a001_Pack_Config_Mismatch" 0 "ALERT_DO_NOT_USE_ZERO" ;
VAL_ 1343 BMS_a082_fourthAlertId 188 "a188_DtcConfirmed" 187 "a187_RippleHeatingEmergencyShutdown" 186 "a186_RippleHeatingChargeFault" 185 "a185_LifeModel_CyclingDcrGrowth_Change" 184 "a184_LifeModel_CyclingLoss_Change" 183 "a183_LifeModel_StoDcrGrowth_Change" 182 "a182_LifeModel_NoCurrentLoss_Change" 181 "a181_SW_Shunt_Over_Temperature" 180 "a180_SW_ECU_reset_blocked" 179 "a179_HvpGpoRequestActive" 178 "a178_SW_Uncontrolled_Regen_PwrB" 177 "a177_SW_Energy_Buffer_Size" 176 "a176_SW_GracefulPowerOff" 175 "a175_Charge_Failure_External" 174 "a174_SW_Charge_Failure" 172 "a172_SW_Isolation_Failure_In_Drive_Warning" 171 "a171_SW_Stack_Voltage_Sense" 170 "a170_SW_Limp_Mode" 169 "a169_SW_FC_Pack_Weld" 168 "a168_SW_FC_Full_Weld" 167 "a167_SW_FC_Partial_Weld" 166 "a166_SW_Pack_Full_Weld" 165 "a165_SW_Pack_Partial_Weld" 164 "a164_SW_Uncontrolled_Regen" 162 "a162_SW_No_Power_For_Support" 161 "a161_SW_BMB_Vref_warning" 160 "a160_SW_FC_Ctr_Clean_Failed" 159 "a159_SW_HVP_ECU_Error" 158 "a158_SW_HVP_HVI_Comms" 157 "a157_SW_Hist_Update_Missed" 156 "a156_SW_BMB_Vref_bad" 155 "a155_SW_Weak_short_impedence" 154 "a154_SW_Brick_OV_Warning_Stop_Charge" 152 "a152_Isolation_In_Dc_Charge" 151 "a151_SW_external_isolation" 150 "a150_SW_Missing_Part_Number" 149 "a149_SW_Missing_Config_Block" 148 "a148_SW_Unsupported_BMB_ASIC_Type" 147 "a147_SW_SOC_High_Ah_Error" 146 "a146_SW_Brick_Overdischarged" 145 "a145_SW_SOC_Change" 144 "a144_Hvp_Config_Mismatch" 143 "a143_SW_CAC_Change" 142 "a142_SW_Isolation_Degradation" 141 "a141_SW_BMB_Status_Warning" 140 "a140_HW_BMB_Status_Fault" 139 "a139_SW_DC_Link_V_Irrational" 138 "a138_SW_Brick_OV_Warning" 137 "a137_SW_Brick_UV_Warning" 136 "a136_SW_Module_OT_Warning" 135 "a135_HW_BMB_Diagnostics_Failure" 134 "a134_SW_Delayed_Ctr_Off" 133 "a133_IO_CAN_Bus_Off" 132 "a132_HW_BMB_OTP_Uncorrctbl" 131 "a131_Bleed_FET_Failure" 130 "a130_IO_CAN_Error" 129 "a129_SW_VSH_Failure" 128 "a128_SW_shunt_MIA" 127 "a127_SW_shunt_SNA" 126 "a126_SW_Thermistor_Failure" 124 "a124_Battery_Coolant_Flood" 123 "a123_SW_Internal_Isolation" 122 "a122_SW_BMS_Therm_Irrational" 121 "a121_SW_NVRAM_Config_Error" 119 "a119_Fast_Open_Vsh_Detected" 117 "a117_SW_Delta_SOC_Weak_Short" 115 "a115_Energy_Rubberbanding_Reset" 112 "a112_LifeModel_Discontinuity" 111 "a111_LifeModel_Spread_Change" 110 "a110_LifeModel_AvgOffset_Change" 109 "a109_HW_BMB_Mute_Status_Mismatch" 108 "a108_SW_BMB_Device_OT" 107 "a107_SW_Stack_Voltage_MIA" 106 "a106_SW_All_Module_Tsense" 105 "a105_SW_One_Module_Tsense" 100 "a100_ThermalEventSuspected" 99 "a099_SW_BMB_Communication" 98 "a098_SW_BMB_Data_Integrity_Loss" 97 "a097_SW_BMB_Over_CAN_Communication" 95 "a095_SW_UI_MIA" 94 "a094_SW_Drive_Inverter_MIA" 92 "a092_SW_ChargePort_Mia_On_Hvs" 91 "a091_SW_ChargePort_MIA" 90 "a090_SW_Gateway_MIA" 89 "a089_SW_VcFront_MIA" 88 "a088_SW_VcFront_MIA_InDrive" 87 "a087_SW_Feim_Test_Blocked" 86 "a086_SW_FC_Contactor_Mismatch" 85 "a085_SW_Pack_Contactor_Mismatch" 84 "a084_SW_Sleep_Wake_Aborted" 83 "a083_SW_Ctr_Close_Failure" 82 "a082_SW_Ctr_Force_Open" 81 "a081_SW_Ctr_Close_Blocked" 80 "a080_SW_Pack_Ctr_Impedance" 79 "a079_Max_Charge_Level_Exceeded" 78 "a078_Rapid_Dch_While_Charging" 77 "a077_SW_Charger_Regulation" 76 "a076_SW_Dch_While_Charging" 75 "a075_SW_Chg_Disable_Failure" 74 "a074_Max_Charge_Level_Reduced" 73 "a073_Unexpected_Loss_Of_Lv" 72 "a072_Module_Brick_Split" 71 "a071_SW_SM_TransCon_Not_Met" 70 "a070_BrickV_Imbalance_Limiting" 69 "a069_SW_Low_Power" 68 "a068_CAC_Imbalance_Limp" 67 "a067_CAC_Imbalance_Limiting" 66 "a066_SOC_Imbalance_Warning" 65 "a065_SW_CAC_Imbalance" 64 "a064_SW_SOC_Imbalance" 63 "a063_SW_ChargePort_Fault" 62 "a062_SW_BrickV_Imbalance" 61 "a061_SW_BrickV_Change" 60 "a060_SW_Leakage_Test_Failure" 59 "a059_SW_Pack_Voltage_Sensing" 58 "a058_SW_Bandolier_Model_Reset" 57 "a057_SW_Bandolier_Model_Warning" 56 "a056_SW_Standby_Supply_Fault" 55 "a055_SW_HvChain_Model_Fault" 54 "a054_SW_Ver_Supply_Fault" 52 "a052_SW_PCS_MIA" 51 "a051_SW_HVC_Vref_Bad" 50 "a050_SW_Brick_Voltage_MIA" 49 "a049_SW_Thermal_Event" 48 "a048_SW_Watch_Dog_Warning" 47 "a047_SW_Task_Stack_Overflow" 46 "a046_SW_Task_Stack_Usage" 45 "a045_SW_Exception" 44 "a044_SW_Assertion" 43 "a043_SW_Watch_Dog_Reset" 42 "a042_SW_MPU_Error" 41 "a041_SW_Destructive_Reset_Source" 40 "a040_SW_Watch_Dog_HW_Triggered" 39 "a039_SW_DC_Link_Over_Voltage" 37 "a037_SW_Flood_Port_Open" 36 "a036_SW_HvpHvilFault" 35 "a035_SW_Isolation" 34 "a034_SW_Passive_Isolation" 33 "a033_VoltageDeviation" 32 "a032_VoltageLoss" 31 "a031_AlertsSetDuringSleep" 30 "a030_Impedance_Deviation" 29 "a029_dSoc_Limiting" 28 "a028_ShuntAsicCurrentOffsetDeviation" 27 "a027_SW_Repeated_Isolation_Failure_In_Drive" 26 "a026_SW_HFCurrent_Anomaly" 25 "a025_SW_PwrBalance_Anomaly" 24 "a024_SW_Islanded_Brick" 23 "a023_SW_Stack_OV" 22 "a022_SW_Over_Current" 21 "a021_SW_Dr_Limits_Regulation" 20 "a020_SW_Brick_Instability" 19 "a019_SW_Module_OT" 18 "a018_SW_Brick_UV" 17 "a017_SW_Brick_OV" 16 "a016_Pack_Module_Id_Mismatch" 7 "a007_SW_Slowed_Chg_Batt_Cold" 4 "a004_Cal_Vs_Serial_Birth_Date_Mismatch" 3 "a003_SW_Pack_Birth_Date_Missing" 2 "a002_Pack_Performance_Config_Mismatch" 1 "a001_Pack_Config_Mismatch" 0 "ALERT_DO_NOT_USE_ZERO" ;
VAL_ 1343 BMS_a083_packContactorRequest 5 "FAULT_OPEN" 4 "OPEN" 3 "CLOSED" 2 "POS_CLOSED_NEG_OPEN" 1 "NEG_CLOSED_POS_OPEN" 0 "SNA" ;
VAL_ 1343 BMS_a085_packContactorSetStatePr 9 "NEGATIVE_CLOSED" 8 "POSITIVE_CLOSED" 7 "WELDED" 6 "PARTIAL_WELD" 5 "CLOSED" 4 "OPENING" 3 "BLOCKED" 2 "CLOSING" 1 "OPEN" 0 "SNA" ;
VAL_ 1343 BMS_a085_packContactorSetState 9 "NEGATIVE_CLOSED" 8 "POSITIVE_CLOSED" 7 "WELDED" 6 "PARTIAL_WELD" 5 "CLOSED" 4 "OPENING" 3 "BLOCKED" 2 "CLOSING" 1 "OPEN" 0 "SNA" ;
VAL_ 1343 BMS_a085_packContactorSetRe_0001 5 "CLOSE_POSITIVE_ONLY" 4 "CLOSE_NEGATIVE_ONLY" 3 "OPEN_IMMEDIATELY" 2 "OPEN" 1 "CLOSE" 0 "SNA" ;
VAL_ 1343 BMS_a085_packContactorSetRequest 5 "CLOSE_POSITIVE_ONLY" 4 "CLOSE_NEGATIVE_ONLY" 3 "OPEN_IMMEDIATELY" 2 "OPEN" 1 "CLOSE" 0 "SNA" ;
VAL_ 1343 BMS_a086_fcContactorSetStatePrev 9 "NEGATIVE_CLOSED" 8 "POSITIVE_CLOSED" 7 "WELDED" 6 "PARTIAL_WELD" 5 "CLOSED" 4 "OPENING" 3 "BLOCKED" 2 "CLOSING" 1 "OPEN" 0 "SNA" ;
VAL_ 1343 BMS_a086_fcContactorSetState 9 "NEGATIVE_CLOSED" 8 "POSITIVE_CLOSED" 7 "WELDED" 6 "PARTIAL_WELD" 5 "CLOSED" 4 "OPENING" 3 "BLOCKED" 2 "CLOSING" 1 "OPEN" 0 "SNA" ;
VAL_ 1343 BMS_a086_fcContactorSetRequestPr 5 "CLOSE_POSITIVE_ONLY" 4 "CLOSE_NEGATIVE_ONLY" 3 "OPEN_IMMEDIATELY" 2 "OPEN" 1 "CLOSE" 0 "SNA" ;
VAL_ 1343 BMS_a086_fcContactorSetRequest 5 "CLOSE_POSITIVE_ONLY" 4 "CLOSE_NEGATIVE_ONLY" 3 "OPEN_IMMEDIATELY" 2 "OPEN" 1 "CLOSE" 0 "SNA" ;
VAL_ 1343 BMS_a087_blockingAlert 188 "a188_DtcConfirmed" 187 "a187_RippleHeatingEmergencyShutdown" 186 "a186_RippleHeatingChargeFault" 185 "a185_LifeModel_CyclingDcrGrowth_Change" 184 "a184_LifeModel_CyclingLoss_Change" 183 "a183_LifeModel_StoDcrGrowth_Change" 182 "a182_LifeModel_NoCurrentLoss_Change" 181 "a181_SW_Shunt_Over_Temperature" 180 "a180_SW_ECU_reset_blocked" 179 "a179_HvpGpoRequestActive" 178 "a178_SW_Uncontrolled_Regen_PwrB" 177 "a177_SW_Energy_Buffer_Size" 176 "a176_SW_GracefulPowerOff" 175 "a175_Charge_Failure_External" 174 "a174_SW_Charge_Failure" 172 "a172_SW_Isolation_Failure_In_Drive_Warning" 171 "a171_SW_Stack_Voltage_Sense" 170 "a170_SW_Limp_Mode" 169 "a169_SW_FC_Pack_Weld" 168 "a168_SW_FC_Full_Weld" 167 "a167_SW_FC_Partial_Weld" 166 "a166_SW_Pack_Full_Weld" 165 "a165_SW_Pack_Partial_Weld" 164 "a164_SW_Uncontrolled_Regen" 162 "a162_SW_No_Power_For_Support" 161 "a161_SW_BMB_Vref_warning" 160 "a160_SW_FC_Ctr_Clean_Failed" 159 "a159_SW_HVP_ECU_Error" 158 "a158_SW_HVP_HVI_Comms" 157 "a157_SW_Hist_Update_Missed" 156 "a156_SW_BMB_Vref_bad" 155 "a155_SW_Weak_short_impedence" 154 "a154_SW_Brick_OV_Warning_Stop_Charge" 152 "a152_Isolation_In_Dc_Charge" 151 "a151_SW_external_isolation" 150 "a150_SW_Missing_Part_Number" 149 "a149_SW_Missing_Config_Block" 148 "a148_SW_Unsupported_BMB_ASIC_Type" 147 "a147_SW_SOC_High_Ah_Error" 146 "a146_SW_Brick_Overdischarged" 145 "a145_SW_SOC_Change" 144 "a144_Hvp_Config_Mismatch" 143 "a143_SW_CAC_Change" 142 "a142_SW_Isolation_Degradation" 141 "a141_SW_BMB_Status_Warning" 140 "a140_HW_BMB_Status_Fault" 139 "a139_SW_DC_Link_V_Irrational" 138 "a138_SW_Brick_OV_Warning" 137 "a137_SW_Brick_UV_Warning" 136 "a136_SW_Module_OT_Warning" 135 "a135_HW_BMB_Diagnostics_Failure" 134 "a134_SW_Delayed_Ctr_Off" 133 "a133_IO_CAN_Bus_Off" 132 "a132_HW_BMB_OTP_Uncorrctbl" 131 "a131_Bleed_FET_Failure" 130 "a130_IO_CAN_Error" 129 "a129_SW_VSH_Failure" 128 "a128_SW_shunt_MIA" 127 "a127_SW_shunt_SNA" 126 "a126_SW_Thermistor_Failure" 124 "a124_Battery_Coolant_Flood" 123 "a123_SW_Internal_Isolation" 122 "a122_SW_BMS_Therm_Irrational" 121 "a121_SW_NVRAM_Config_Error" 119 "a119_Fast_Open_Vsh_Detected" 117 "a117_SW_Delta_SOC_Weak_Short" 115 "a115_Energy_Rubberbanding_Reset" 112 "a112_LifeModel_Discontinuity" 111 "a111_LifeModel_Spread_Change" 110 "a110_LifeModel_AvgOffset_Change" 109 "a109_HW_BMB_Mute_Status_Mismatch" 108 "a108_SW_BMB_Device_OT" 107 "a107_SW_Stack_Voltage_MIA" 106 "a106_SW_All_Module_Tsense" 105 "a105_SW_One_Module_Tsense" 100 "a100_ThermalEventSuspected" 99 "a099_SW_BMB_Communication" 98 "a098_SW_BMB_Data_Integrity_Loss" 97 "a097_SW_BMB_Over_CAN_Communication" 95 "a095_SW_UI_MIA" 94 "a094_SW_Drive_Inverter_MIA" 92 "a092_SW_ChargePort_Mia_On_Hvs" 91 "a091_SW_ChargePort_MIA" 90 "a090_SW_Gateway_MIA" 89 "a089_SW_VcFront_MIA" 88 "a088_SW_VcFront_MIA_InDrive" 87 "a087_SW_Feim_Test_Blocked" 86 "a086_SW_FC_Contactor_Mismatch" 85 "a085_SW_Pack_Contactor_Mismatch" 84 "a084_SW_Sleep_Wake_Aborted" 83 "a083_SW_Ctr_Close_Failure" 82 "a082_SW_Ctr_Force_Open" 81 "a081_SW_Ctr_Close_Blocked" 80 "a080_SW_Pack_Ctr_Impedance" 79 "a079_Max_Charge_Level_Exceeded" 78 "a078_Rapid_Dch_While_Charging" 77 "a077_SW_Charger_Regulation" 76 "a076_SW_Dch_While_Charging" 75 "a075_SW_Chg_Disable_Failure" 74 "a074_Max_Charge_Level_Reduced" 73 "a073_Unexpected_Loss_Of_Lv" 72 "a072_Module_Brick_Split" 71 "a071_SW_SM_TransCon_Not_Met" 70 "a070_BrickV_Imbalance_Limiting" 69 "a069_SW_Low_Power" 68 "a068_CAC_Imbalance_Limp" 67 "a067_CAC_Imbalance_Limiting" 66 "a066_SOC_Imbalance_Warning" 65 "a065_SW_CAC_Imbalance" 64 "a064_SW_SOC_Imbalance" 63 "a063_SW_ChargePort_Fault" 62 "a062_SW_BrickV_Imbalance" 61 "a061_SW_BrickV_Change" 60 "a060_SW_Leakage_Test_Failure" 59 "a059_SW_Pack_Voltage_Sensing" 58 "a058_SW_Bandolier_Model_Reset" 57 "a057_SW_Bandolier_Model_Warning" 56 "a056_SW_Standby_Supply_Fault" 55 "a055_SW_HvChain_Model_Fault" 54 "a054_SW_Ver_Supply_Fault" 52 "a052_SW_PCS_MIA" 51 "a051_SW_HVC_Vref_Bad" 50 "a050_SW_Brick_Voltage_MIA" 49 "a049_SW_Thermal_Event" 48 "a048_SW_Watch_Dog_Warning" 47 "a047_SW_Task_Stack_Overflow" 46 "a046_SW_Task_Stack_Usage" 45 "a045_SW_Exception" 44 "a044_SW_Assertion" 43 "a043_SW_Watch_Dog_Reset" 42 "a042_SW_MPU_Error" 41 "a041_SW_Destructive_Reset_Source" 40 "a040_SW_Watch_Dog_HW_Triggered" 39 "a039_SW_DC_Link_Over_Voltage" 37 "a037_SW_Flood_Port_Open" 36 "a036_SW_HvpHvilFault" 35 "a035_SW_Isolation" 34 "a034_SW_Passive_Isolation" 33 "a033_VoltageDeviation" 32 "a032_VoltageLoss" 31 "a031_AlertsSetDuringSleep" 30 "a030_Impedance_Deviation" 29 "a029_dSoc_Limiting" 28 "a028_ShuntAsicCurrentOffsetDeviation" 27 "a027_SW_Repeated_Isolation_Failure_In_Drive" 26 "a026_SW_HFCurrent_Anomaly" 25 "a025_SW_PwrBalance_Anomaly" 24 "a024_SW_Islanded_Brick" 23 "a023_SW_Stack_OV" 22 "a022_SW_Over_Current" 21 "a021_SW_Dr_Limits_Regulation" 20 "a020_SW_Brick_Instability" 19 "a019_SW_Module_OT" 18 "a018_SW_Brick_UV" 17 "a017_SW_Brick_OV" 16 "a016_Pack_Module_Id_Mismatch" 7 "a007_SW_Slowed_Chg_Batt_Cold" 4 "a004_Cal_Vs_Serial_Birth_Date_Mismatch" 3 "a003_SW_Pack_Birth_Date_Missing" 2 "a002_Pack_Performance_Config_Mismatch" 1 "a001_Pack_Config_Mismatch" 0 "ALERT_DO_NOT_USE_ZERO" ;
VAL_ 1343 BMS_a090_GTWmessageTout 9 "UI_TRIPPLANNING" 8 "MCU_DRIVERLIMITS" 7 "GTW_CARCONFIG2" 6 "GTW_12VSTATUS" 5 "MCU_ODOMETER" 4 "GTW_CARCONFIG" 3 "GTW_PTNM" 2 "GTW_BODYSTATUS" 1 "MCU_POWER" 0 "GTW_COMMANDS" ;
VAL_ 1343 BMS_a098_bmbCommStatusTypeA 3 "BYPASSED" 2 "NOMINAL" 1 "BAD" 0 "MISSING" ;
VAL_ 1343 BMS_a098_bmbCommStatusTypeB 3 "BYPASSED" 2 "NOMINAL" 1 "BAD" 0 "MISSING" ;
VAL_ 1343 BMS_a099_bmbCommStatusTypeA 3 "BYPASSED" 2 "NOMINAL" 1 "BAD" 0 "MISSING" ;
VAL_ 1343 BMS_a099_bmbCommStatusTypeB 3 "BYPASSED" 2 "NOMINAL" 1 "BAD" 0 "MISSING" ;
VAL_ 1343 BMS_a099_bmbChainBreakType 5 "TAIL_BREAK" 4 "HEAD_BREAK" 3 "INVALID_BREAK" 2 "DOUBLE_BREAK" 1 "SINGLE_BREAK" 0 "NONE" ;
VAL_ 1343 BMS_a117_brickSoc2 1023 "SNA" ;
VAL_ 1343 BMS_a117_dSocAlpha 4095 "SNA" ;
VAL_ 1343 BMS_a135_bmbDiagnosticsType 3 "UNUSED" 2 "BMB_DIAG_TEST5" 1 "BMB_DIAG_TESTA" 0 "BMB_DIAG_NONE" ;
VAL_ 1343 BMS_a140_faultType 162 "FAULT_COMM1_BY_UART_TR" 161 "FAULT_COMM1_BY_UART_RR" 160 "FAULT_COMM1_BY_COMMCLR_DET" 159 "FAULT_COMM1_BY_STOP_DET" 158 "FAULT_COMM2_BY_COML_TR" 157 "FAULT_COMM2_BY_COML_RR" 156 "FAULT_COMM2_BY_COML_RC" 155 "FAULT_COMM2_BY_COML_BIT" 154 "FAULT_COMM2_BY_COMH_TR" 153 "FAULT_COMM2_BY_COMH_RR" 152 "FAULT_COMM2_BY_COMH_RC" 151 "FAULT_COMM2_BY_COMH_BIT" 150 "FAULT_COMM3_BY_FCOMM_DET" 149 "FAULT_COMM3_BY_FTONE_DET" 148 "FAULT_COMM3_BY_HB_FAIL" 147 "FAULT_COMM3_BY_HB_FAST" 146 "FAULT_OTP_BY_DED_DET" 145 "FAULT_OTP_BY_SEC_DET" 144 "FAULT_OTP_BY_CUST_CRC" 143 "FAULT_OTP_BY_FACT_CRC" 142 "FAULT_OTP_BY_CUSTLDERR" 141 "FAULT_OTP_BY_FACTLDERR" 140 "FAULT_OTP_BY_GBLOVERR" 139 "FAULT_SYS_BY_LFO" 138 "FAULT_SYS_BY_SHUTDOWN_REC" 137 "FAULT_SYS_BY_GPIO" 136 "FAULT_SYS_BY_DRST" 135 "FAULT_SYS_BY_CTL" 134 "FAULT_SYS_BY_CTS" 133 "FAULT_SYS_BY_TSHUT" 132 "FAULT_SYS_BY_TWARN" 131 "FAULT_COMP_GPIO_BY_GPIO8_FAIL" 130 "FAULT_COMP_GPIO_BY_GPIO7_FAIL" 129 "FAULT_COMP_GPIO_BY_GPIO6_FAIL" 128 "FAULT_COMP_GPIO_BY_GPIO5_FAIL" 127 "FAULT_COMP_GPIO_BY_GPIO4_FAIL" 126 "FAULT_COMP_GPIO_BY_GPIO3_FAIL" 125 "FAULT_COMP_GPIO_BY_GPIO2_FAIL" 124 "FAULT_COMP_GPIO_BY_GPIO1_FAIL" 123 "FAULT_COMP_VCCB1_BY_CELL16_FAIL" 122 "FAULT_COMP_VCCB1_BY_CELL15_FAIL" 121 "FAULT_COMP_VCCB1_BY_CELL14_FAIL" 120 "FAULT_COMP_VCCB1_BY_CELL13_FAIL" 119 "FAULT_COMP_VCCB1_BY_CELL12_FAIL" 118 "FAULT_COMP_VCCB1_BY_CELL11_FAIL" 117 "FAULT_COMP_VCCB1_BY_CELL10_FAIL" 116 "FAULT_COMP_VCCB1_BY_CELL9_FAIL" 115 "FAULT_COMP_VCCB2_BY_CELL8_FAIL" 114 "FAULT_COMP_VCCB2_BY_CELL7_FAIL" 113 "FAULT_COMP_VCCB2_BY_CELL6_FAIL" 112 "FAULT_COMP_VCCB2_BY_CELL5_FAIL" 111 "FAULT_COMP_VCCB2_BY_CELL4_FAIL" 110 "FAULT_COMP_VCCB2_BY_CELL3_FAIL" 109 "FAULT_COMP_VCCB2_BY_CELL2_FAIL" 108 "FAULT_COMP_VCCB2_BY_CELL1_FAIL" 107 "FAULT_COMP_VCOW1_BY_VCOW16_FAIL" 106 "FAULT_COMP_VCOW1_BY_VCOW15_FAIL" 105 "FAULT_COMP_VCOW1_BY_VCOW14_FAIL" 104 "FAULT_COMP_VCOW1_BY_VCOW13_FAIL" 103 "FAULT_COMP_VCOW1_BY_VCOW12_FAIL" 102 "FAULT_COMP_VCOW1_BY_VCOW11_FAIL" 101 "FAULT_COMP_VCOW1_BY_VCOW10_FAIL" 100 "FAULT_COMP_VCOW1_BY_VCOW9_FAIL" 99 "FAULT_COMP_VCOW2_BY_VCOW8_FAIL" 98 "FAULT_COMP_VCOW2_BY_VCOW7_FAIL" 97 "FAULT_COMP_VCOW2_BY_VCOW6_FAIL" 96 "FAULT_COMP_VCOW2_BY_VCOW5_FAIL" 95 "FAULT_COMP_VCOW2_BY_VCOW4_FAIL" 94 "FAULT_COMP_VCOW2_BY_VCOW3_FAIL" 93 "FAULT_COMP_VCOW2_BY_VCOW2_FAIL" 92 "FAULT_COMP_VCOW2_BY_VCOW1_FAIL" 91 "FAULT_COMP_CBOW1_BY_CBOW16_FAIL" 90 "FAULT_COMP_CBOW1_BY_CBOW15_FAIL" 89 "FAULT_COMP_CBOW1_BY_CBOW14_FAIL" 88 "FAULT_COMP_CBOW1_BY_CBOW13_FAIL" 87 "FAULT_COMP_CBOW1_BY_CBOW12_FAIL" 86 "FAULT_COMP_CBOW1_BY_CBOW11_FAIL" 85 "FAULT_COMP_CBOW1_BY_CBOW10_FAIL" 84 "FAULT_COMP_CBOW1_BY_CBOW9_FAIL" 83 "FAULT_COMP_CBOW2_BY_CBOW8_FAIL" 82 "FAULT_COMP_CBOW2_BY_CBOW7_FAIL" 81 "FAULT_COMP_CBOW2_BY_CBOW6_FAIL" 80 "FAULT_COMP_CBOW2_BY_CBOW5_FAIL" 79 "FAULT_COMP_CBOW2_BY_CBOW4_FAIL" 78 "FAULT_COMP_CBOW2_BY_CBOW3_FAIL" 77 "FAULT_COMP_CBOW2_BY_CBOW2_FAIL" 76 "FAULT_COMP_CBOW2_BY_CBOW1_FAIL" 75 "FAULT_COMP_CBFET1_BY_CBFET16_FAIL" 74 "FAULT_COMP_CBFET1_BY_CBFET15_FAIL" 73 "FAULT_COMP_CBFET1_BY_CBFET14_FAIL" 72 "FAULT_COMP_CBFET1_BY_CBFET13_FAIL" 71 "FAULT_COMP_CBFET1_BY_CBFET12_FAIL" 70 "FAULT_COMP_CBFET1_BY_CBFET11_FAIL" 69 "FAULT_COMP_CBFET1_BY_CBFET10_FAIL" 68 "FAULT_COMP_CBFET1_BY_CBFET9_FAIL" 67 "FAULT_COMP_CBFET2_BY_CBFET8_FAIL" 66 "FAULT_COMP_CBFET2_BY_CBFET7_FAIL" 65 "FAULT_COMP_CBFET2_BY_CBFET6_FAIL" 64 "FAULT_COMP_CBFET2_BY_CBFET5_FAIL" 63 "FAULT_COMP_CBFET2_BY_CBFET4_FAIL" 62 "FAULT_COMP_CBFET2_BY_CBFET3_FAIL" 61 "FAULT_COMP_CBFET2_BY_CBFET2_FAIL" 60 "FAULT_COMP_CBFET2_BY_CBFET1_FAIL" 59 "FAULT_COMP_MISC_BY_COMP_ADC_ABORT" 58 "FAULT_COMP_MISC_BY_LPF_FAIL" 57 "FAULT_PWR1_BY_CVSS_OPEN" 56 "FAULT_PWR1_BY_DVSS_OPEN" 55 "FAULT_PWR1_BY_REFHM_OPEN" 54 "FAULT_PWR1_BY_CVDD_UV" 53 "FAULT_PWR1_BY_CVDD_OV" 52 "FAULT_PWR1_BY_DVDD_OV" 51 "FAULT_PWR1_BY_AVDD_OSC" 50 "FAULT_PWR1_BY_AVDD_OV" 49 "FAULT_PWR2_BY_PWRBIST_FAIL" 48 "FAULT_PWR2_BY_REFH_OSC" 47 "FAULT_PWR2_BY_NEG5V_UV" 46 "FAULT_PWR2_BY_TSREF_OSC" 45 "FAULT_PWR2_BY_TSREF_UV" 44 "FAULT_PWR2_BY_TSREF_OV" 43 "FAULT_PWR3_BY_AVDDUV_DRST" 42 "SEQ_ERROR_FAULT_CLEAR" 41 "SEQ_ERROR_FAULT_INJECT" 40 "SEQ_ERROR_CELL_RESUME" 39 "SEQ_ERROR_CELL_FREEZE" 38 "SEQ_ERROR_AUX_RESET" 37 "SEQ_ERROR_AUX_CLEAR" 36 "TEST_MODE" 35 "SUPPLY_RAIL" 34 "CLK_CHECK" 33 "DIGITAL_REF_OV" 32 "DIGITAL_REF_UV" 31 "ANALOG_REF_OV" 30 "ANALOG_REF_UV" 29 "POWER_BIST" 28 "GPIO_COMP" 27 "CBOW_COMP" 26 "VCOW_COMP" 25 "VCCB_COMP" 24 "VBG2_PLAUS" 23 "REFL_PLAUS" 22 "TSREF_PLAUS" 21 "VCM1_PLAUS" 20 "THERM_PLAUS" 19 "DIETEMP_PLAUS" 18 "STACKV_PLAUS" 17 "BRICKV_PLAUS" 16 "ADC_COMP_ABORT" 15 "LPF_FAULT_DET" 14 "AUX_MISC_DRDY" 13 "AUX_GPIO_DRDY" 12 "AUX_VCELL_DRDY" 11 "MAIN_ADC_DRDY" 10 "MAIN_ADC_LPF" 9 "POWER_FAULT" 8 "SYSTEM_FAULT" 7 "COMM_FAULT" 6 "OTP_FAULT" 5 "ADC_COMP_FAULT" 4 "ERROR_OTP_FAULT" 3 "ERROR_OTP_WARNING" 2 "ERROR_ADC_SEQUENCE" 1 "ERROR_POWER_RESET" 0 "ERROR_NONE" ;
VAL_ 1343 BMS_a142_mode 4 "VOLTAGE_SETTLING_MODE" 3 "FEIM_POSITIVE_MODE" 2 "FEIM_NEGATIVE_MODE" 1 "VEHICLE_ISOLATION_MODE" 0 "MODE_RESET" ;
VAL_ 1343 BMS_a145_brickChangeHystRatio 1023 "SNA" ;
VAL_ 1343 BMS_a146_state 10 "DIAG" 9 "SNA" 8 "TEST" 7 "WELD" 6 "FAULT" 5 "CLEAR_FAULT" 4 "FEIM" 3 "CHARGE" 2 "SUPPORT" 1 "DRIVE" 0 "STANDBY" ;
VAL_ 1343 BMS_a152_mode 4 "VOLTAGE_SETTLING_MODE" 3 "FEIM_POSITIVE_MODE" 2 "FEIM_NEGATIVE_MODE" 1 "VEHICLE_ISOLATION_MODE" 0 "MODE_RESET" ;
VAL_ 1343 BMS_a156_VrefStatus 3 "BYPASSED" 2 "NOMINAL" 1 "BAD" 0 "MISSING" ;
VAL_ 800 BMS_matrixIndex 3 "AlertMatrix3" 2 "AlertMatrix2" 1 "AlertMatrix1" 0 "AlertMatrix0" ;
VAL_ 818 BMS_bmbMinMaxMultiplexer 2 "END" 1 "VOLT_MUX1" 0 "THERM_MUX0" ;
VAL_ 1138 BMS_chargeCurrentLimitMode 20 "CHG_LIMIT_RIPPLE_HEAT_ACTIVE" 19 "CHG_LIMIT_NEAR_HWOT_LIMIT" 18 "CHG_LIMIT_LIMP_MODE" 17 "CHG_LIMIT_MISSING_CELL" 16 "CHG_LIMIT_CAC_IMBALANCE" 15 "CHG_LIMIT_PCS_IMPLICIT" 14 "CHG_LIMIT_EVSE_IMPLICIT" 13 "CHG_LIMIT_RAMP_UP_PHASE" 12 "CHG_LIMIT_HVAC_COOLING" 11 "CHG_LIMIT_HV_CHAIN" 10 "CHG_LIMIT_CONFIG" 9 "CHG_LIMIT_TETHERING" 8 "CHG_LIMIT_LEAKY_BUCKET" 7 "CHG_LIMIT_BRICK_VOLTAGE_REG" 6 "CHG_LIMIT_BRICK_TEMP_TOO_COLD" 5 "CHG_LIMIT_BRICK_TEMP_TOO_HOT" 4 "CHG_LIMIT_BRICK_TEMP_OPTIMAL_CELL_PROFILE" 3 "CHG_LIMIT_CP" 2 "CHG_LIMIT_PCS" 1 "CHG_LIMIT_EVSE" 0 "CHG_LIMIT_NONE" ;
VAL_ 1138 BMS_timeToFinishHeatForCharge 127 "SNA" 126 "CALCULATING" ;
VAL_ 1138 BMS_diNodeModelTemp 2047 "SNA" ;
VAL_ 562 BMS_internalHvilSenseV 65535 "SNA" ;
VAL_ 562 BMS_hvilCoverVSense 65535 "SNA" ;
VAL_ 2029 BMS_10HzDebug_Id 34 "AGED_SOC_OCV" 33 "THM_TARGETS" 32 "SOC_AND_OCV" 31 "DRIVE_LIMITS" 30 "STANDBY_SUPPLY" 29 "SLEEP_WAKE" 28 "POWER_PREDICTION_3" 27 "POWER_PREDICTION_2" 26 "POWER_PREDICTION_1" 25 "ADC_FLOOD" 24 "ADC_MISC" 23 "ADC_DCLINK" 22 "ADC_CP" 21 "ADC_VREF" 20 "WAKE_TIMERS" 19 "CAC_3" 18 "CAC_2" 17 "CAC_1" 16 "HYST" 15 "PACK_VOLTAGES" 14 "THM_MODEL_DATA_11" 13 "THM_MODEL_DATA_10" 12 "THM_MODEL_DATA_9" 3 "SOC_RESTING" 2 "ISOLATION" 1 "AHR_COUNTER" 0 "STATE" ;
VAL_ 690 BMS_energyStatusMultiplexer 2 "Mux2" 1 "Mux1" 0 "Mux0" ;
VAL_ 690 BMS_nominalFullPackEnergy 65535 "SNA" ;
VAL_ 690 BMS_nominalEnergyRemaining 65535 "SNA" ;
VAL_ 690 BMS_idealEnergyRemaining 65535 "SNA" ;
VAL_ 690 BMS_energyBuffer 65535 "SNA" ;
VAL_ 690 BMS_expectedEnergyRemaining 65535 "SNA" ;
VAL_ 690 BMS_energyToChargeComplete 65535 "SNA" ;
VAL_ 690 BMS_energyRemainingDisplay 65535 "SNA" ;
VAL_ 690 BMS_energyRemainingTDisplay 65535 "SNA" ;
VAL_ 690 BMS_userFacingSoe 2047 "SNA" ;
VAL_ 306 BMS_packCurrent -32768 "SNA" ;
VAL_ 306 BMS_currentUnfiltered -32768 "SNA" ;
VAL_ 306 BMS_chgTimeToFull 4095 "SNA" ;
VAL_ 768 BMS_infoIndex 255 "END" 31 "SUBCOMPONENT_GITHASH" 30 "PACKAGE_SN_8_14" 29 "PACKAGE_SN_1_7" 27 "PACKAGE_PN_15_20" 26 "PACKAGE_PN_8_14" 25 "PACKAGE_PN_1_7" 23 "SUBCOMPONENT2" 22 "VARIANTCRC" 20 "UDS_PROTOCOL_BOOTCRC" 19 "VERSION_DEPRECATED" 18 "BOOTLOADER_GITHASH" 17 "APP_GITHASH" 16 "SUBCOMPONENT" 15 "BOOTLOADER_CRC" 14 "BOOTLOADER_SVN" 13 "APP_CRC" 11 "PCBAID_ASSYID_USAGEID" 10 "BUILD_HWID_COMPONENTID" 9 "DEPRECATED_9" 8 "DEPRECATED_8" 7 "DEPRECATED_7" 6 "DEPRECATED_6" 5 "DEPRECATED_5" 4 "DEPRECATED_4" 3 "DEPRECATED_3" 2 "DEPRECATED_2" 1 "DEPRECATED_1" 0 "DEPRECATED_0" ;
VAL_ 768 BMS_buildType 4 "INFO_MFG_BUILD" 3 "INFO_TRACEABLE_CI_BUILD" 2 "INFO_LOCAL_BUILD" 1 "INFO_PLATFORM_BUILD" 0 "INFO_UNKNOWN_BUILD" ;
VAL_ 1010 BMS_kwhCounter_Id 14 "END" 13 "MUX13" 12 "MUX12" 11 "MUX11" 10 "MUX10" 9 "MUX9" 8 "MUX8" 7 "MUX7" 6 "MUX6" 5 "MUX5" 4 "MUX4" 3 "MUX3" 2 "MUX2" 1 "MUX1" 0 "MUX0" ;
VAL_ 884 BMS_log1MuxId 27 "SLEEP_CURRENT_2" 26 "SLEEP_CURRENT_1" 25 "CHARGE_LIMIT_2" 24 "CHARGE_LIMIT_1" 23 "CHARGE_ENERGY_4" 22 "CHARGE_ENERGY_3" 21 "CHARGE_ENERGY_2" 20 "CHARGE_ENERGY_1" 19 "PACK_DATA" 18 "IMPEDANCE_DEVIATION_2" 17 "IMPEDANCE_DEVIATION_1" 16 "SOC_BY_DELTA_V_2" 15 "SOC_BY_DELTA_V_1" 14 "CHARGE_REGULATION" 13 "CHARGE_TERMINATION" 12 "BANDOLIER_MODEL_THERMISTOR_TEMPS_2" 11 "BANDOLIER_MODEL_THERMISTOR_TEMPS_1" 10 "BANDOLIER_MODEL_PACK_TEMPS" 9 "CHARGE_INTERFACE_2" 8 "CHARGE_INTERFACE_1" 7 "NEG_CTR_HEALTH_2" 6 "NEG_CTR_HEALTH_1" 5 "POS_CTR_HEALTH_2" 4 "POS_CTR_HEALTH_1" 3 "STATES_AND_BOOLS" 2 "CPU_USAGE3" 1 "CPU_USAGE2" 0 "CPU_USAGE1" ;
VAL_ 884 BMS_hvChargeStatus 8 "CHARGE_BLOCKED" 7 "CHARGE_FAULTED" 6 "EMERGENCY_SHUTDOWN" 5 "GRACEFUL_SHUTDOWN" 4 "CHARGE_ENABLED" 3 "CHARGE_ENABLING" 2 "EXT_PRECHARGE_ALLOWED" 1 "EXT_EVSE_TEST_ALLOWED" 0 "CHARGE_STANDBY" ;
